VERSION "Version"

NS_ :

BS_:

BU_: Tester CCU ADC CCU_CCURT1 CCU_CCURT2 RLR RRR ZCUF ZCUL ZCUR ZCUT EMS IDM DCDC IPS NIDU DCUR OBC OPC LPC CPC EMCM GCU DCUF IPU BMS EOPR EVCC DCDC2 EDL SRS ECS EPS EPB RBM IBCS ICM IID IDC PHUDD AMP WHUD IMR INU IFC FAPA PAS PCS SCMR SCMRL SCMRR SCMRM MFS WSM DRM IDU FCP LBMSAD AVAS ATSS DLPFL FBLCM FLISD FLLCM FRLCM RLLCMA RLLCMB RRLCMA RRLCMB RLISD DLPML DLPMR TRM PSDL PSDR HVSPRL HVSPRR RFR SBM WCM ETC TBOX2 TBOX IDUR CBM PLGM TMC LPC2 SCMT RCP RRISD LBMS RLBMS CCURT1 CCURT2 RT1_C1 RT2_C3 RT1_C0 OTAWL RAS EBB RCICP WCMFR WCMRL SAS CD

BO_ 696 CCU_ZCUR_SBM_5: 64 CCU
 SG_ SBM_5_CRC : 7|16@0+ (1,0) [0|65535] ""  ADC,FAPA
 SG_ SBM_5_Counter : 23|8@0+ (1,0) [0|255] ""  ADC,FAPA
 SG_ KAE_EDK1UnlockBtnPressSt : 31|2@0+ (1,0) [0|3] ""  ADC,FAPA
 SG_ KAE_EDK1LockBtnPressSt : 29|2@0+ (1,0) [0|3] ""  ADC,FAPA
 SG_ KAE_EDK1RESBtnPressSt : 27|2@0+ (1,0) [0|3] ""  ADC,FAPA
 SG_ KAE_EDK1PSD_LBtnPressSt : 25|2@0+ (1,0) [0|3] ""  ADC,FAPA
 SG_ KAE_EDK1PSD_RBtnPressSt : 39|2@0+ (1,0) [0|3] ""  ADC,FAPA
 SG_ KAE_EDK1TrunkBtnPressSt : 37|2@0+ (1,0) [0|3] ""  ADC,FAPA
 SG_ KAE_EDK1PanicBtnPressSt : 35|2@0+ (1,0) [0|3] ""  ADC,FAPA
 SG_ KAE_EDK1User_definedBtnPressSt : 33|2@0+ (1,0) [0|3] ""  ADC,FAPA
 SG_ KAE_EDK2UnlockBtnPressSt : 47|2@0+ (1,0) [0|3] ""  ADC,FAPA
 SG_ KAE_EDK2LockBtnPressSt : 45|2@0+ (1,0) [0|3] ""  ADC,FAPA
 SG_ KAE_EDK2RESBtnPressSt : 43|2@0+ (1,0) [0|3] ""  ADC,FAPA
 SG_ KAE_EDK2PSD_LBtnPressSt : 41|2@0+ (1,0) [0|3] ""  ADC,FAPA
 SG_ KAE_EDK2PSD_RBtnPressSt : 55|2@0+ (1,0) [0|3] ""  ADC,FAPA
 SG_ KAE_EDK2TrunkBtnPressSt : 53|2@0+ (1,0) [0|3] ""  ADC,FAPA
 SG_ KAE_EDK2PanicBtnPressSt : 51|2@0+ (1,0) [0|3] ""  ADC,FAPA
 SG_ KAE_EDK2User_definedBtnPressSt : 49|2@0+ (1,0) [0|3] ""  ADC,FAPA
 SG_ KAE_EDK3UnlockBtnPressSt : 63|2@0+ (1,0) [0|3] ""  ADC,FAPA
 SG_ KAE_EDK3LockBtnPressSt : 61|2@0+ (1,0) [0|3] ""  ADC,FAPA
 SG_ KAE_EDK3RESBtnPressSt : 59|2@0+ (1,0) [0|3] ""  ADC,FAPA
 SG_ KAE_EDK3PSD_LBtnPressSt : 57|2@0+ (1,0) [0|3] ""  ADC,FAPA
 SG_ KAE_EDK3PSD_RBtnPressSt : 71|2@0+ (1,0) [0|3] ""  ADC,FAPA
 SG_ KAE_EDK3TrunkBtnPressSt : 69|2@0+ (1,0) [0|3] ""  ADC,FAPA
 SG_ KAE_EDK3PanicBtnPressSt : 67|2@0+ (1,0) [0|3] ""  ADC,FAPA
 SG_ KAE_EDK3User_definedBtnPressSt : 65|2@0+ (1,0) [0|3] ""  ADC,FAPA
 SG_ KAE_RPADirectionSel : 79|3@0+ (1,0) [0|7] ""  ADC,FAPA
 SG_ KAE_RPAmode : 76|2@0+ (1,0) [0|3] ""  ADC,FAPA
 SG_ KAE_RPADeviceSt : 74|3@0+ (1,0) [0|7] ""  ADC,FAPA
 SG_ KAE_PhoneBatt : 87|8@0+ (1,0) [0|100] ""  ADC,FAPA
 SG_ KAE_RPACheckReq : 95|1@0+ (1,0) [0|1] ""  ADC,FAPA
 SG_ KAE_RPAKeyPstSt : 94|2@0+ (1,0) [0|3] ""  ADC,FAPA
 SG_ KAE_RPADeviceFailReason : 92|4@0+ (1,0) [0|15] ""  ADC,FAPA
 SG_ KAE_RPABtnSt : 88|1@0+ (1,0) [0|1] ""  ADC,FAPA
 SG_ KAE_ForRPAFailReason : 103|4@0+ (1,0) [0|15] ""  ADC,FAPA
 SG_ KAE_RPABtnStVD : 99|1@0+ (1,0) [0|1] ""  ADC,FAPA
 SG_ KAE_RPACancelBtnSt : 98|1@0+ (1,0) [0|1] ""  ADC,FAPA
 SG_ KAE_RPACancelBtnStVD : 97|1@0+ (1,0) [0|1] ""  ADC,FAPA
 SG_ KAE_ComSDKUBouncesSt : 96|1@0+ (1,0) [0|1] ""  ADC,FAPA
 SG_ KAE_HAVPCancelParking : 111|1@0+ (1,0) [0|1] ""  ADC,FAPA
 SG_ KAE_HAVPDisclaimerAgree : 110|2@0+ (1,0) [0|3] ""  ADC,FAPA
 SG_ KAE_HAVPPathSelect : 108|4@0+ (1,0) [0|15] ""  ADC,FAPA
 SG_ KAE_RPAResponse : 119|8@0+ (1,0) [0|255] ""  ADC,FAPA
 SG_ KAE_HAVPUWBZone : 127|4@0+ (1,0) [0|15] ""  ADC,FAPA
 SG_ KAE_HAVPUWBXPosition : 123|12@0+ (1,0) [0|4095] ""  ADC,FAPA
 SG_ KAE_HAVPUWBYPosition : 143|12@0+ (1,0) [0|4095] ""  ADC,FAPA
 SG_ KAE_UnlockDoorReq : 147|1@0+ (1,0) [0|1] ""  ADC,FAPA
 SG_ KAE_UnlockDoorReqVD : 146|1@0+ (1,0) [0|1] ""  ADC,FAPA
 SG_ KAE_LockDoorReq : 145|1@0+ (1,0) [0|1] ""  ADC,FAPA
 SG_ KAE_LockDoorReqVD : 144|1@0+ (1,0) [0|1] ""  ADC,FAPA
 SG_ KAE_WindowsCloseReq : 159|1@0+ (1,0) [0|1] ""  ADC,FAPA
 SG_ KAE_WindowsCloseReqVD : 158|1@0+ (1,0) [0|1] ""  ADC,FAPA
 SG_ KAE_WindowsOpenReq : 157|1@0+ (1,0) [0|1] ""  ADC,FAPA
 SG_ KAE_WindowsOpenReqVD : 156|1@0+ (1,0) [0|1] ""  ADC,FAPA
 SG_ KAE_TrunkUnlockReq : 155|1@0+ (1,0) [0|1] ""  ADC,FAPA
 SG_ KAE_TrunkUnlockReqVD : 154|1@0+ (1,0) [0|1] ""  ADC,FAPA
 SG_ KAE_HoodUnlockReq : 153|1@0+ (1,0) [0|1] ""  ADC,FAPA
 SG_ KAE_HoodUnlockReqVD : 152|1@0+ (1,0) [0|1] ""  ADC,FAPA
 SG_ KAE_PLGMOpenReq : 167|1@0+ (1,0) [0|1] ""  ADC,FAPA
 SG_ KAE_PLGMOpenReqVD : 166|1@0+ (1,0) [0|1] ""  ADC,FAPA
 SG_ KAE_PLGMCloseReq : 165|1@0+ (1,0) [0|1] ""  ADC,FAPA
 SG_ KAE_PLGMCloseReqVD : 164|1@0+ (1,0) [0|1] ""  ADC,FAPA
 SG_ KAE_SunRoofOpenReq : 163|1@0+ (1,0) [0|1] ""  ADC,FAPA
 SG_ KAE_SunRoofOpenReqVD : 162|1@0+ (1,0) [0|1] ""  ADC,FAPA
 SG_ KAE_SunRoofCloseReq : 161|1@0+ (1,0) [0|1] ""  ADC,FAPA
 SG_ KAE_SunRoofCloseReqVD : 160|1@0+ (1,0) [0|1] ""  ADC,FAPA
 SG_ KAE_PAAReq : 287|4@0+ (1,0) [0|15] ""  ADC,FAPA
 SG_ KAE_PAAReqVd : 283|1@0+ (1,0) [0|1] ""  ADC,FAPA
 SG_ KAE_EDK1UnlockBtnSt : 282|1@0+ (1,0) [0|1] ""  ADC,FAPA
 SG_ KAE_EDK1LockBtnSt : 281|1@0+ (1,0) [0|1] ""  ADC,FAPA
 SG_ KAE_EDK1RESBtnSt : 280|1@0+ (1,0) [0|1] ""  ADC,FAPA
 SG_ KAE_EDK1PSD_LBtnSt : 295|1@0+ (1,0) [0|1] ""  ADC,FAPA
 SG_ KAE_EDK1PSD_RBtnSt : 294|1@0+ (1,0) [0|1] ""  ADC,FAPA
 SG_ KAE_EDK1TrunkBtnSt : 293|1@0+ (1,0) [0|1] ""  ADC,FAPA
 SG_ KAE_EDK1PanicBtnSt : 292|1@0+ (1,0) [0|1] ""  ADC,FAPA
 SG_ KAE_EDK1User_definedBtnSt : 291|1@0+ (1,0) [0|1] ""  ADC,FAPA
 SG_ KAE_EDK2UnlockBtnSt : 290|1@0+ (1,0) [0|1] ""  ADC,FAPA
 SG_ KAE_EDK2LockBtnSt : 289|1@0+ (1,0) [0|1] ""  ADC,FAPA
 SG_ KAE_EDK2RESBtnSt : 288|1@0+ (1,0) [0|1] ""  ADC,FAPA
 SG_ PKC_RemPwrOnOffReq : 314|3@0+ (1,0) [0|7] ""  ADC,FAPA
 SG_ KAE_EDK2PSD_LBtnSt : 303|1@0+ (1,0) [0|1] ""  ADC,FAPA
 SG_ KAE_EDK2PSD_RBtnSt : 302|1@0+ (1,0) [0|1] ""  ADC,FAPA
 SG_ KAE_EDK2TrunkBtnSt : 301|1@0+ (1,0) [0|1] ""  ADC,FAPA
 SG_ KAE_EDK2PanicBtnSt : 300|1@0+ (1,0) [0|1] ""  ADC,FAPA
 SG_ KAE_EDK2User_definedBtnSt : 299|1@0+ (1,0) [0|1] ""  ADC,FAPA
 SG_ KAE_EDK3UnlockBtnSt : 298|1@0+ (1,0) [0|1] ""  ADC,FAPA
 SG_ KAE_EDK3LockBtnSt : 297|1@0+ (1,0) [0|1] ""  ADC,FAPA
 SG_ KAE_EDK3RESBtnSt : 296|1@0+ (1,0) [0|1] ""  ADC,FAPA
 SG_ KAE_EDK3PSD_LBtnSt : 311|1@0+ (1,0) [0|1] ""  ADC,FAPA
 SG_ KAE_EDK3PSD_RBtnSt : 310|1@0+ (1,0) [0|1] ""  ADC,FAPA
 SG_ KAE_EDK3TrunkBtnSt : 309|1@0+ (1,0) [0|1] ""  ADC,FAPA
 SG_ KAE_EDK3PanicBtnSt : 308|1@0+ (1,0) [0|1] ""  ADC,FAPA
 SG_ KAE_EDK3User_definedBtnSt : 316|1@0+ (1,0) [0|1] ""  ADC,FAPA
 SG_ PKC_PhoneRPAOnlineOrNot : 455|8@0+ (1,0) [0|255] ""  ADC

BO_ 134 CCU_VIM_ADCCode: 16 CCU_CCURT1
 SG_ Theft_Auth_ADCCode : 7|128@0+ (1,0) [0|3.40282366920938E+38] ""  ADC,FAPA

BO_ 793 CCU_LBMS_1: 64 CCU
 SG_ LBMS_1_CRC : 7|16@0+ (1,0) [0|65535] ""  ADC
 SG_ LBMS_1_Counter : 23|8@0+ (1,0) [0|255] ""  ADC
 SG_ LBMS_SOFVD : 28|1@0+ (1,0) [0|1] ""  ADC
 SG_ LBMS_SOFEN : 30|2@0+ (1,0) [0|3] ""  ADC

BO_ 1024 CCU_TimeSync: 16 CCU
 SG_ SYNC_FC_Type : 7|8@0+ (1,0) [0|255] ""  ZCUF,ZCUL,ZCUR,ZCUT,ADC,FAPA
 SG_ SYNC_FC_CRC : 15|8@0+ (1,0) [0|255] ""  ZCUF,ZCUL,ZCUR,ZCUT,ADC,FAPA
 SG_ SYNC_FC_Sequencecnt : 19|4@0+ (1,0) [0|15] ""  ZCUF,ZCUL,ZCUR,ZCUT,ADC,FAPA
 SG_ SYNC_FC_TimeDomain : 23|4@0+ (1,0) [0|15] ""  ZCUF,ZCUL,ZCUR,ZCUT,ADC,FAPA
 SG_ SYNC_FC_OVS : 25|2@0+ (1,0) [0|3] ""  ZCUF,ZCUL,ZCUR,ZCUT,ADC,FAPA
 SG_ SYNC_FC_SGW : 26|1@0+ (1,0) [0|1] ""  ZCUF,ZCUL,ZCUR,ZCUT,ADC,FAPA
 SG_ SYNC_FC_Reserved : 31|5@0+ (1,0) [0|31] ""  ZCUF,ZCUL,ZCUR,ZCUT,ADC,FAPA
 SG_ SYNC_FC_SyncTime : 39|32@0+ (1,0) [0|4294967295] ""  ZCUF,ZCUL,ZCUR,ZCUT,ADC,FAPA

BO_ 476 CCU_FCP_1: 16 CCU
 SG_ FCP_OmniViewBtnSt : 96|1@0+ (1,0) [0|1] ""  IDC,ADC
 SG_ FCP_OmniViewBtnStVD : 97|1@0+ (1,0) [0|1] ""  IDC,ADC

BO_ 1657 ADC_MCU_Diag_Request: 64 Tester
 SG_ ADC_MCU_Diag_Request : 7|64@0+ (1,0) [0|0] ""  ADC

BO_ 1806 ADC_Phys_Diag_Rx: 64 Tester
 SG_ ADC_Diag_Request : 7|512@0+ (1,0) [0|0] ""  ADC

BO_ 1854 FR_Phys_Diag_Rx: 64 Tester
 SG_ FR_Diag_Request : 7|512@0+ (1,0) [0|0] ""  ADC,IFC,FAPA

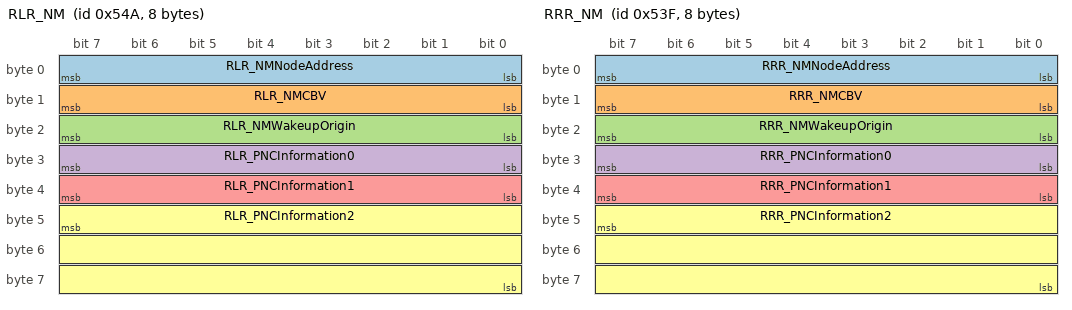
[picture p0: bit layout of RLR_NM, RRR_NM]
BO_ 1354 RLR_NM: 8 RLR
 SG_ RLR_NMNodeAddress : 7|8@0+ (1,0) [0|255] ""  CCU,ADC,RRR
 SG_ RLR_NMCBV : 15|8@0+ (1,0) [0|0] ""  CCU,ADC,RRR
 SG_ RLR_NMWakeupOrigin : 23|8@0+ (1,0) [0|255] ""  CCU,ADC,RRR
 SG_ RLR_PNCInformation0 : 31|8@0+ (1,0) [0|255] ""  CCU,ADC,RRR
 SG_ RLR_PNCInformation1 : 39|8@0+ (1,0) [0|255] ""  CCU,ADC,RRR
 SG_ RLR_PNCInformation2 : 47|24@0+ (1,0) [0|0] ""  CCU,ADC,RRR

BO_ 987 RLR_1: 32 RLR
 SG_ RLR_1_CRC : 7|16@0+ (1,0) [0|65535] ""  ADC,IFC,FAPA
 SG_ RLR_1_Counter : 23|8@0+ (1,0) [0|255] ""  ADC,IFC,FAPA
 SG_ RLR_MRRSt : 31|3@0+ (1,0) [0|7] ""  ADC,IFC,FAPA
 SG_ RLR_ExMirLedWarnL : 28|2@0+ (1,0) [0|3] ""  ADC,IFC,FAPA
 SG_ RLR_LCASt : 26|2@0+ (1,0) [0|3] ""  ADC,IFC,FAPA
 SG_ RLR_LCAWarnLeft : 24|2@0+ (1,0) [0|3] ""  ADC,IFC,FAPA
 SG_ RLR_ClusterLamp : 38|3@0+ (1,0) [0|7] ""  ADC,IFC,FAPA
 SG_ RLR_DOWWarnL : 35|2@0+ (1,0) [0|3] ""  ADC,IFC,FAPA
 SG_ RLR_DOWSt : 33|2@0+ (1,0) [0|3] ""  ADC,IFC,FAPA
 SG_ RLR_AudioWarnFL : 41|2@0+ (1,0) [0|3] ""  ADC,IFC,FAPA
 SG_ RLR_AudioWarnRL : 43|2@0+ (1,0) [0|3] ""  ADC,IFC,FAPA
 SG_ RLR_IALWarnFL : 45|2@0+ (1,0) [0|3] ""  ADC,IFC,FAPA
 SG_ RLR_IALWarnRL : 47|2@0+ (1,0) [0|3] ""  ADC,IFC,FAPA
 SG_ RLR_RCTAWarnLeft : 49|2@0+ (1,0) [0|3] ""  ADC,IFC,FAPA
 SG_ RLR_RCWSt : 51|2@0+ (1,0) [0|3] ""  ADC,IFC,FAPA
 SG_ RLR_RCWWarn : 53|2@0+ (1,0) [0|3] ""  ADC,IFC,FAPA,RRR
 SG_ RLR_TargetLVD : 55|2@0+ (1,0) [0|3] ""  ADC,IFC,FAPA
 SG_ RLR_TargetRelSpdL : 63|10@0+ (0.06225,-10) [-10|50] "m/s"  ADC,IFC,FAPA
 SG_ RLR_TargetDstL : 69|11@0+ (0.06225,-90) [-90|10] "m"  ADC,IFC,FAPA
 SG_ RLR_TargetLatDistL : 74|7@0+ (0.1,0) [0|12.7] "m"  ADC,IFC,FAPA
 SG_ RLR_RCTASt : 83|2@0+ (1,0) [0|3] ""  ADC,IFC,FAPA
 SG_ RLR_RCTAAssistType : 81|2@0+ (1,0) [0|3] ""  ADC,IFC,FAPA,RRR

BO_ 1343 RRR_NM: 8 RRR
 SG_ RRR_NMNodeAddress : 7|8@0+ (1,0) [0|255] ""  CCU,ADC,RLR
 SG_ RRR_NMCBV : 15|8@0+ (1,0) [0|0] ""  CCU,ADC,RLR
 SG_ RRR_NMWakeupOrigin : 23|8@0+ (1,0) [0|255] ""  CCU,ADC,RLR
 SG_ RRR_PNCInformation0 : 31|8@0+ (1,0) [0|255] ""  CCU,ADC,RLR
 SG_ RRR_PNCInformation1 : 39|8@0+ (1,0) [0|255] ""  CCU,ADC,RLR
 SG_ RRR_PNCInformation2 : 47|24@0+ (1,0) [0|0] ""  CCU,ADC,RLR

BO_ 932 RRR_1: 32 RRR
 SG_ RRR_1_CRC : 7|16@0+ (1,0) [0|65535] ""  ADC,IFC,FAPA
 SG_ RRR_1_Counter : 23|8@0+ (1,0) [0|255] ""  ADC,IFC,FAPA
 SG_ RRR_MRRSt : 31|3@0+ (1,0) [0|7] ""  ADC,IFC,FAPA
 SG_ RRR_ExMirLedWarnR : 28|2@0+ (1,0) [0|3] ""  ADC,IFC,FAPA
 SG_ RRR_LCASt : 26|2@0+ (1,0) [0|3] ""  ADC,IFC,FAPA
 SG_ RRR_LCAWarnRight : 24|2@0+ (1,0) [0|3] ""  ADC,IFC,FAPA
 SG_ RRR_ClusterLamp : 38|3@0+ (1,0) [0|7] ""  ADC,IFC,FAPA
 SG_ RRR_DOWWarnR : 35|2@0+ (1,0) [0|3] ""  ADC,IFC,FAPA
 SG_ RRR_DOWSt : 33|2@0+ (1,0) [0|3] ""  ADC,IFC,FAPA
 SG_ RRR_AudioWarnFR : 41|2@0+ (1,0) [0|3] ""  ADC,IFC,FAPA
 SG_ RRR_AudioWarnRR : 43|2@0+ (1,0) [0|3] ""  ADC,IFC,FAPA
 SG_ RRR_IALWarnFR : 45|2@0+ (1,0) [0|3] ""  ADC,IFC,FAPA
 SG_ RRR_IALWarnRR : 47|2@0+ (1,0) [0|3] ""  ADC,IFC,FAPA
 SG_ RRR_RCTASt : 49|2@0+ (1,0) [0|3] ""  ADC,IFC,FAPA
 SG_ RRR_RCTAWarnRight : 51|2@0+ (1,0) [0|3] ""  ADC,IFC,FAPA
 SG_ RRR_RCWSt : 53|2@0+ (1,0) [0|3] ""  ADC,IFC,FAPA
 SG_ RRR_RCWWarn : 55|2@0+ (1,0) [0|3] ""  ADC,IFC,FAPA
 SG_ RRR_RCTBTargetDecel : 63|8@0+ (0.05,-10) [-10|2.75] "m/s2"  ADC,IFC,FAPA
 SG_ RRR_RCTBBrkReq : 64|1@0+ (1,0) [0|1] ""  ADC,IFC,FAPA
 SG_ RRR_TargetLatDistR : 71|7@0+ (0.1,-12.7) [-12.7|0] ""  ADC,IFC,FAPA
 SG_ RRR_TargetRelSpdR : 79|10@0+ (0.06225,-10) [-10|50] "m/s"  ADC,IFC,FAPA
 SG_ RRR_RCTBBrkgVD : 83|1@0+ (1,0) [0|1] ""  ADC,IFC,FAPA
 SG_ RRR_TargetRVD : 85|2@0+ (1,0) [0|3] ""  ADC,IFC,FAPA
 SG_ RRR_TargetDstR : 82|11@0+ (0.06225,-90) [-90|10] "m"  ADC,IFC,FAPA
 SG_ RRR_RCTAAssistType : 103|2@0+ (1,0) [0|3] ""  ADC,IFC,FAPA

BO_ 620 CCU_PADS_2: 32 CCU_CCURT1
 SG_ CCU_PADS_2_CRC : 7|16@0+ (1,0) [0|65535] ""  ADC,IFC,FAPA
 SG_ CCU_PADS_2_Counter : 23|8@0+ (1,0) [0|255] ""  ADC,IFC,FAPA
 SG_ UINM_PADS_ResponseErr : 28|1@0+ (1,0) [0|1] ""  ADC,IFC,FAPA
 SG_ UINM_PADS_CustomSWSt : 41|1@0+ (1,0) [0|1] ""  ICM,IDC,ADC,IFC,FAPA
 SG_ UINM_PADS_CustomSWStVD : 42|1@0+ (1,0) [0|1] ""  ICM,IDC,ADC,IFC,FAPA
 SG_ UINM_PADS_CustomSWstuck : 43|1@0+ (1,0) [0|1] ""  ICM,IDC,ADC,IFC,FAPA
 SG_ UINM_PADS_IDC_PlaySWSt : 58|1@0+ (1,0) [0|1] ""  ICM,IDC,ADC,IFC,FAPA
 SG_ UINM_PADS_IDC_PlaySWStVD : 59|1@0+ (1,0) [0|1] ""  ICM,IDC,ADC,IFC,FAPA
 SG_ UINM_PADS_CruSetSpeedRollerRotatedDir : 62|2@0+ (1,0) [0|3] ""  ICM,IDC,ADC,IFC,FAPA
 SG_ UINM_PADS_FolDistIncSWSt : 63|1@0+ (1,0) [0|1] ""  ICM,IDC,ADC,IFC,FAPA
 SG_ UINM_PADS_CruSetSpeedRollerSt : 69|6@0+ (1,0) [0|63] ""  ICM,IDC,ADC,IFC,FAPA
 SG_ UINM_PADS_FolDistIncSWStVD : 70|1@0+ (1,0) [0|1] ""  ICM,IDC,ADC,IFC,FAPA
 SG_ UINM_PADS_FolDistIncSWStuckSt : 71|1@0+ (1,0) [0|1] ""  ICM,IDC,ADC,IFC,FAPA
 SG_ UINM_PADS_FolDistDecSWStVD : 73|1@0+ (1,0) [0|1] ""  ICM,IDC,ADC,IFC,FAPA
 SG_ UINM_PADS_FolDistDecSWStuckSt : 74|1@0+ (1,0) [0|1] ""  ICM,IDC,ADC,IFC,FAPA
 SG_ UINM_PADS_OKSWSt : 75|1@0+ (1,0) [0|1] ""  ICM,IDC,ADC,IFC,FAPA
 SG_ UINM_PADS_OKSWStVD : 76|1@0+ (1,0) [0|1] ""  ICM,IDC,ADC,IFC,FAPA
 SG_ UINM_PADS_OKSWStuckSt : 77|1@0+ (1,0) [0|1] ""  ICM,IDC,ADC,IFC,FAPA
 SG_ UINM_PADS_CruSetSpeedRollerVD : 79|1@0+ (1,0) [0|1] ""  IDC,ADC,IFC,FAPA
 SG_ UINM_PADS_FolDistDecSWSt : 72|1@0+ (1,0) [0|1] ""  ICM,IDC,ADC,IFC,FAPA
 SG_ IL_PADS_LightbarErrSt : 140|1@0+ (1,0) [0|1] "/"  ADC,FAPA
 SG_ UINM_PADS_CruSWSt : 107|1@0+ (1,0) [0|1] ""  ADC,IFC,FAPA
 SG_ UINM_PADS_CruSWStVD : 108|1@0+ (1,0) [0|1] ""  ADC,IFC,FAPA
 SG_ UINM_PADS_CruSWStuckSt : 109|1@0+ (1,0) [0|1] ""  ADC,IFC,FAPA
 SG_ UINM_PADS_CruSpeedDecSWSt : 110|1@0+ (1,0) [0|1] ""  ADC,IFC,FAPA
 SG_ UINM_PADS_CruSpeedDecSWStVD : 111|1@0+ (1,0) [0|1] ""  ADC,IFC,FAPA
 SG_ UINM_PADS_CruSpeedDecSWStuckSt : 112|1@0+ (1,0) [0|1] ""  ADC,IFC,FAPA
 SG_ UINM_PADS_CruResumeSpeedIncSWSt : 113|1@0+ (1,0) [0|1] ""  ADC,IFC,FAPA
 SG_ UINM_PADS_CruResumeSpeedIncSWStVD : 114|1@0+ (1,0) [0|1] ""  ADC,IFC,FAPA
 SG_ UINM_PADS_CruResumeSpeedIncSWStuckSt : 115|1@0+ (1,0) [0|1] ""  ADC,IFC,FAPA
 SG_ UINM_PADS_CruTJAICASWSt : 119|1@0+ (1,0) [0|1] ""  ADC,IFC,FAPA
 SG_ UINM_PADS_CruTJAICASWStVD : 120|1@0+ (1,0) [0|1] ""  ADC,IFC,FAPA
 SG_ UINM_PADS_CruTJAICASWStuckSt : 121|1@0+ (1,0) [0|1] ""  ADC,IFC,FAPA
 SG_ UINM_PADS_Custom2SWSt : 125|1@0+ (1,0) [0|1] ""  IDC,ADC,IFC,FAPA
 SG_ UINM_PADS_Custom2SWStVD : 126|1@0+ (1,0) [0|1] ""  IDC,ADC,IFC,FAPA
 SG_ UINM_PADS_Custom2SWStuckSt : 127|1@0+ (1,0) [0|1] ""  IDC,ADC,IFC,FAPA
 SG_ UINM_PADS_ACCSWSt : 129|2@0+ (1,0) [0|3] ""  ADC,IFC,FAPA
 SG_ UINM_PADS_VoltageFaultSt : 131|2@0+ (1,0) [0|3] ""  ADC,IFC,FAPA
 SG_ UINM_PADS_L3SWSt : 133|2@0+ (1,0) [0|3] ""  ADC
 SG_ UINM_PADS_L3SWStVD : 134|1@0+ (1,0) [0|1] ""  ADC
 SG_ UINM_PADS_L3SWStuckSt : 135|1@0+ (1,0) [0|1] ""  ADC
 SG_ IL_PADS_LightbarSt : 139|4@0+ (1,0) [0|15] "/"  ADC,FAPA

CM_ SG_ 696 SBM_5_CRC "E2E Profile 5 CRC";
CM_ SG_ 696 SBM_5_Counter "E2E Profile 5 Counter";
CM_ SG_ 696 KAE_EDK1UnlockBtnPressSt "EDK Unlock Button Pressed Status";
CM_ SG_ 696 KAE_EDK1LockBtnPressSt "EDK Lock Button Pressed Status";
CM_ SG_ 696 KAE_EDK1RESBtnPressSt "EDK RES Button Status";
CM_ SG_ 696 KAE_EDK1PSD_LBtnPressSt "EDK PSD_L Button Status";
CM_ SG_ 696 KAE_EDK1PSD_RBtnPressSt "EDK PSD_R Button Status";
CM_ SG_ 696 KAE_EDK1TrunkBtnPressSt "EDK Trunk Button Status";
CM_ SG_ 696 KAE_EDK1PanicBtnPressSt "EDK Panic Button Status";
CM_ SG_ 696 KAE_EDK1User_definedBtnPressSt "EDK User_defined Button Status";
CM_ SG_ 696 KAE_EDK2UnlockBtnPressSt "EDK Unlock Button Pressed Status";
CM_ SG_ 696 KAE_EDK2LockBtnPressSt "EDK Lock Button Pressed Status";
CM_ SG_ 696 KAE_EDK2RESBtnPressSt "EDK RES Button Status";
CM_ SG_ 696 KAE_EDK2PSD_LBtnPressSt "EDK PSD_L Button Status";
CM_ SG_ 696 KAE_EDK2PSD_RBtnPressSt "EDK PSD_R Button Status";
CM_ SG_ 696 KAE_EDK2TrunkBtnPressSt "EDK Trunk Button Status";
CM_ SG_ 696 KAE_EDK2PanicBtnPressSt "EDK Panic Button Status";
CM_ SG_ 696 KAE_EDK2User_definedBtnPressSt "EDK User_defined Button Status";
CM_ SG_ 696 KAE_EDK3UnlockBtnPressSt "EDK Unlock Button Pressed Status";
CM_ SG_ 696 KAE_EDK3LockBtnPressSt "EDK Lock Button Pressed Status";
CM_ SG_ 696 KAE_EDK3RESBtnPressSt "EDK RES Button Status";
CM_ SG_ 696 KAE_EDK3PSD_LBtnPressSt "EDK PSD_L Button Status";
CM_ SG_ 696 KAE_EDK3PSD_RBtnPressSt "EDK PSD_R Button Status";
CM_ SG_ 696 KAE_EDK3TrunkBtnPressSt "EDK Trunk Button Status";
CM_ SG_ 696 KAE_EDK3PanicBtnPressSt "EDK Panic Button Status";
CM_ SG_ 696 KAE_EDK3User_definedBtnPressSt "EDK User_defined Button Status";
CM_ SG_ 696 KAE_RPADirectionSel "RPA Direction Selection";
CM_ SG_ 696 KAE_RPAmode "SBM RPA mode";
CM_ SG_ 696 KAE_RPADeviceSt "RPA Device Status";
CM_ SG_ 696 KAE_PhoneBatt "SBM Phone batt";
CM_ SG_ 696 KAE_RPACheckReq "SBM RPA Checking Req";
CM_ SG_ 696 KAE_RPAKeyPstSt "RPA Key Position Status";
CM_ SG_ 696 KAE_RPADeviceFailReason "RPA Device Failure Reason";
CM_ SG_ 696 KAE_RPABtnSt "RPA Button Status";
CM_ SG_ 696 KAE_ForRPAFailReason "RPA and SBM failure reason";
CM_ SG_ 696 KAE_RPABtnStVD "RPA Button Status valid value";
CM_ SG_ 696 KAE_RPACancelBtnSt "RPA Cancal Button Status";
CM_ SG_ 696 KAE_RPACancelBtnStVD "RPA Button Statusvalid valid value";
CM_ SG_ 696 KAE_ComSDKUBouncesSt "Communication status between SBM and SDK,This signal bounces every time the SDK updates the data";
CM_ SG_ 696 KAE_HAVPCancelParking "HAVP User cancellation SBM";
CM_ SG_ 696 KAE_HAVPDisclaimerAgree "App HAVP Disclaimer confirm";
CM_ SG_ 696 KAE_HAVPPathSelect "HAVP User path selection SBM";
CM_ SG_ 696 KAE_RPAResponse "SBM Response RPA Challenge  Singal";
CM_ SG_ 696 KAE_HAVPUWBZone "SBM UWB HAVP Zone";
CM_ SG_ 696 KAE_HAVPUWBXPosition "SBM UWB HAVP X Position";
CM_ SG_ 696 KAE_HAVPUWBYPosition "SBM UWB HAVP Y Position";
CM_ SG_ 696 KAE_UnlockDoorReq "Virtual Key APP Unlock door request";
CM_ SG_ 696 KAE_UnlockDoorReqVD "KAE_UnlockDoorReq valid value";
CM_ SG_ 696 KAE_LockDoorReq "Virtual Key APP Lock door request";
CM_ SG_ 696 KAE_LockDoorReqVD "KAE_LockDoorReq valid value";
CM_ SG_ 696 KAE_WindowsCloseReq "Virtual Key APP close the windows request";
CM_ SG_ 696 KAE_WindowsCloseReqVD "KAE_WindowsCloseReq valid value";
CM_ SG_ 696 KAE_WindowsOpenReq "Virtual Key APP open the windows request";
CM_ SG_ 696 KAE_WindowsOpenReqVD "KAE_WindowsOpenReq valid value";
CM_ SG_ 696 KAE_TrunkUnlockReq "Virtual Key APP request unlock the trunck";
CM_ SG_ 696 KAE_TrunkUnlockReqVD "KAE_TrunkUnlockReq valid value";
CM_ SG_ 696 KAE_HoodUnlockReq "Virtual Key APP request unlock the hood";
CM_ SG_ 696 KAE_HoodUnlockReqVD "KAE_HoodeUnlockReq valid value";
CM_ SG_ 696 KAE_PLGMOpenReq "Virtual Key APP PLGM(Power Liftgate Module) open request";
CM_ SG_ 696 KAE_PLGMOpenReqVD "KAE_PLGMOpenReq valid value";
CM_ SG_ 696 KAE_PLGMCloseReq "Virtual Key APP PLGM(Power Liftgate Module) close request";
CM_ SG_ 696 KAE_PLGMCloseReqVD "KAE_PLGMCloseReq valid value";
CM_ SG_ 696 KAE_SunRoofOpenReq "Virtual Key APP sun roof open request";
CM_ SG_ 696 KAE_SunRoofOpenReqVD "KAE_SunRoofOpenReq valid value";
CM_ SG_ 696 KAE_SunRoofCloseReq "Virtual Key APP sun roof close request";
CM_ SG_ 696 KAE_SunRoofCloseReqVD "KAE_SunRoofCloseReq valid value";
CM_ SG_ 696 KAE_PAAReq "KAE PAA request";
CM_ SG_ 696 KAE_PAAReqVd "KAE_PAA Req valid value";
CM_ SG_ 696 KAE_EDK1UnlockBtnSt "EDK1 Unlock Button current Status";
CM_ SG_ 696 KAE_EDK1LockBtnSt "EDK1 Lock Button current Status";
CM_ SG_ 696 KAE_EDK1RESBtnSt "EDK1 RES Button  current Status";
CM_ SG_ 696 KAE_EDK1PSD_LBtnSt "EDK1 PSD_L Button current Status";
CM_ SG_ 696 KAE_EDK1PSD_RBtnSt "EDK1 PSD_R Button current Status";
CM_ SG_ 696 KAE_EDK1TrunkBtnSt "EDK1 Trunk Button current Status";
CM_ SG_ 696 KAE_EDK1PanicBtnSt "EDK1 Panic Button current Status";
CM_ SG_ 696 KAE_EDK1User_definedBtnSt "EDK1 User_defined Button current Status";
CM_ SG_ 696 KAE_EDK2UnlockBtnSt "EDK2 Unlock Button current Status";
CM_ SG_ 696 KAE_EDK2LockBtnSt "EDK2 Lock Button current Status";
CM_ SG_ 696 KAE_EDK2RESBtnSt "EDK2 RES Button  current Status";
CM_ SG_ 696 PKC_RemPwrOnOffReq "RPA power on and power off request";
CM_ SG_ 696 KAE_EDK2PSD_LBtnSt "EDK2 PSD_L Button current Status";
CM_ SG_ 696 KAE_EDK2PSD_RBtnSt "EDK2 PSD_R Button current Status";
CM_ SG_ 696 KAE_EDK2TrunkBtnSt "EDK2 Trunk Button current Status";
CM_ SG_ 696 KAE_EDK2PanicBtnSt "EDK2 Panic Button current Status";
CM_ SG_ 696 KAE_EDK2User_definedBtnSt "EDK2 User_defined Button current Status";
CM_ SG_ 696 KAE_EDK3UnlockBtnSt "EDK3 Unlock Button current Status";
CM_ SG_ 696 KAE_EDK3LockBtnSt "EDK3 Lock Button current Status";
CM_ SG_ 696 KAE_EDK3RESBtnSt "EDK3 RES Button  current Status";
CM_ SG_ 696 KAE_EDK3PSD_LBtnSt "EDK3 PSD_L Button current Status";
CM_ SG_ 696 KAE_EDK3PSD_RBtnSt "EDK3 PSD_R Button current Status";
CM_ SG_ 696 KAE_EDK3TrunkBtnSt "EDK3 Trunk Button current Status";
CM_ SG_ 696 KAE_EDK3PanicBtnSt "EDK3 Panic Button current Status";
CM_ SG_ 696 KAE_EDK3User_definedBtnSt "EDK3 User_defined Button current Status";
CM_ SG_ 696 PKC_PhoneRPAOnlineOrNot "Phone RPA Online Or Not";
CM_ SG_ 134 Theft_Auth_ADCCode "Remote Control Random Code to ADC";
CM_ SG_ 793 LBMS_1_CRC "E2E Profile 5 CRC";
CM_ SG_ 793 LBMS_1_Counter "E2E Profile 5 Counter";
CM_ SG_ 793 LBMS_SOFVD "LBMS Validity of SOF";
CM_ SG_ 793 LBMS_SOFEN "LBMS  State of Function Enable";
CM_ SG_ 1024 SYNC_FC_Type "Type=0x20:TsyncType=0x28:Tsync FUP";
CM_ SG_ 1024 SYNC_FC_CRC "CRC";
CM_ SG_ 1024 SYNC_FC_Sequencecnt "Sequence counter";
CM_ SG_ 1024 SYNC_FC_TimeDomain "Time Domain";
CM_ SG_ 1024 SYNC_FC_OVS "In FUP PDUOVS=Overflow of seconds";
CM_ SG_ 1024 SYNC_FC_SGW "In FUP PDUSyncToGTM=0SyncToSubDomain=1";
CM_ SG_ 1024 SYNC_FC_Reserved "In FUP PDUReserved default=0";
CM_ SG_ 1024 SYNC_FC_SyncTime "Tsync:SyncTimeSec=32bit LSB of the 48 bits seconds part timeTsync FUP:Sync TimeNSec=32 bit value in nanosconds";
CM_ SG_ 476 FCP_OmniViewBtnSt "OmniView Button Status";
CM_ SG_ 476 FCP_OmniViewBtnStVD "indicates signal FCP_OmniViewBtnSt validity";
CM_ SG_ 1657 ADC_MCU_Diag_Request "Diagnostic function of ADC_MCU request";
CM_ SG_ 1806 ADC_Diag_Request "Diagnostic physical request";
CM_ SG_ 1854 FR_Diag_Request "Diagnostic physical request";
CM_ SG_ 1354 RLR_NMNodeAddress "RLR node address";
CM_ SG_ 1354 RLR_NMCBV "RLR Network management control bit vector";
CM_ SG_ 1354 RLR_NMWakeupOrigin "Origin of the wake up";
CM_ SG_ 1354 RLR_PNCInformation0 "PNC Information";
CM_ SG_ 1354 RLR_PNCInformation1 "PNC Information";
CM_ SG_ 1354 RLR_PNCInformation2 "PNC Information";
CM_ SG_ 987 RLR_1_CRC "E2E Profile 5 CRC";
CM_ SG_ 987 RLR_1_Counter "E2E Profile 5 Counter";
CM_ SG_ 987 RLR_MRRSt "MRR systems ON OFF andError Status";
CM_ SG_ 987 RLR_ExMirLedWarnL "Exterior mirror LED warning left";
CM_ SG_ 987 RLR_LCASt "BSD-LCA Function status";
CM_ SG_ 987 RLR_LCAWarnLeft " the vehicle Left warning level in the LCA feature";
CM_ SG_ 987 RLR_ClusterLamp "Cluster lamp color status";
CM_ SG_ 987 RLR_DOWWarnL "DOW warning left";
CM_ SG_ 987 RLR_DOWSt "DOW function state left";
CM_ SG_ 987 RLR_AudioWarnFL "Front left door speaker warning";
CM_ SG_ 987 RLR_AudioWarnRL "Rear left door speaker warning";
CM_ SG_ 987 RLR_IALWarnFL "Front left door light warning";
CM_ SG_ 987 RLR_IALWarnRL "Rear left door light warning";
CM_ SG_ 987 RLR_RCTAWarnLeft "the vehicle left warning in the RCTAfeature";
CM_ SG_ 987 RLR_RCWSt "RCW(rear collision warning ) feature status";
CM_ SG_ 987 RLR_RCWWarn "the vehicle warning level in the RCWfeature";
CM_ SG_ 987 RLR_TargetLVD "ELK left target valid state";
CM_ SG_ 987 RLR_TargetRelSpdL "ELK left target relative speed";
CM_ SG_ 987 RLR_TargetDstL "ELK left target relative distance";
CM_ SG_ 987 RLR_TargetLatDistL "ELK left target lateral relative distance ";
CM_ SG_ 987 RLR_RCTASt "RCTA Function status left";
CM_ SG_ 987 RLR_RCTAAssistType "RCTA assist type request";
CM_ SG_ 1343 RRR_NMNodeAddress "RRR node address";
CM_ SG_ 1343 RRR_NMCBV "RRR Network management control bit vector";
CM_ SG_ 1343 RRR_NMWakeupOrigin "Origin of the wake up";
CM_ SG_ 1343 RRR_PNCInformation0 "PNC Information";
CM_ SG_ 1343 RRR_PNCInformation1 "PNC Information";
CM_ SG_ 1343 RRR_PNCInformation2 "PNC Information";
CM_ SG_ 932 RRR_1_CRC "E2E Profile 5 CRC";
CM_ SG_ 932 RRR_1_Counter "E2E Profile 5 Counter";
CM_ SG_ 932 RRR_MRRSt "MRR systems ON OFF andError Status";
CM_ SG_ 932 RRR_ExMirLedWarnR "Exterior mirror LED warning right";
CM_ SG_ 932 RRR_LCASt "BSD-LCA Function status";
CM_ SG_ 932 RRR_LCAWarnRight " the vehicle right warning level in the LCA feature";
CM_ SG_ 932 RRR_ClusterLamp "Cluster lamp color status";
CM_ SG_ 932 RRR_DOWWarnR "DOW warning right";
CM_ SG_ 932 RRR_DOWSt "DOW function state  right";
CM_ SG_ 932 RRR_AudioWarnFR "Front right door speaker warning";
CM_ SG_ 932 RRR_AudioWarnRR "Rear right door speaker warning";
CM_ SG_ 932 RRR_IALWarnFR "Front right door light warning";
CM_ SG_ 932 RRR_IALWarnRR "Rear right door light warning";
CM_ SG_ 932 RRR_RCTASt "RCTA Function status";
CM_ SG_ 932 RRR_RCTAWarnRight "the vehicle right warning in the RCTAfeature";
CM_ SG_ 932 RRR_RCWSt "RCW(rear collision warning ) feature status";
CM_ SG_ 932 RRR_RCWWarn "the vehicle warning level in the RCWfeature";
CM_ SG_ 932 RRR_RCTBTargetDecel "target deceleration value from RCTB";
CM_ SG_ 932 RRR_RCTBBrkReq "RCTB brake request";
CM_ SG_ 932 RRR_TargetLatDistR "ELK right target lateral relative distance";
CM_ SG_ 932 RRR_TargetRelSpdR "ELK right target relative speed";
CM_ SG_ 932 RRR_RCTBBrkgVD "RCTB brake request valid flag";
CM_ SG_ 932 RRR_TargetRVD "ELK right target valid state";
CM_ SG_ 932 RRR_TargetDstR "ELK right target relative distance";
CM_ SG_ 932 RRR_RCTAAssistType "RCTA assist type request";
CM_ SG_ 620 CCU_PADS_2_CRC "E2E Profile 5 CRC";
CM_ SG_ 620 CCU_PADS_2_Counter "E2E Profile 5 Counter";
CM_ SG_ 620 UINM_PADS_ResponseErr "LIN response error";
CM_ SG_ 620 UINM_PADS_CustomSWSt "PADS Custom  swtich state";
CM_ SG_ 620 UINM_PADS_CustomSWStVD "PADS_CustomSWSt validity";
CM_ SG_ 620 UINM_PADS_CustomSWstuck "PADS Custom  swtich stuck state";
CM_ SG_ 620 UINM_PADS_IDC_PlaySWSt "Indicates PADS Play swtich state";
CM_ SG_ 620 UINM_PADS_IDC_PlaySWStVD "Indicates PADS_IDC_PlaySWSt validity";
CM_ SG_ 620 UINM_PADS_CruSetSpeedRollerRotatedDir "indicate PADS curise  roller rotating direction";
CM_ SG_ 620 UINM_PADS_FolDistIncSWSt "PADS Following distance level increase  swtich state";
CM_ SG_ 620 UINM_PADS_CruSetSpeedRollerSt "indicate PADS curise  roller rotating steps";
CM_ SG_ 620 UINM_PADS_FolDistIncSWStVD "Indicates PADS_FolDistIncSWSt validity";
CM_ SG_ 620 UINM_PADS_FolDistIncSWStuckSt "Indicates PADS's   distance level increase swtich stuck state";
CM_ SG_ 620 UINM_PADS_FolDistDecSWStVD "Indicates PADS_FolDistDecSWSt validity";
CM_ SG_ 620 UINM_PADS_FolDistDecSWStuckSt "Indicates PADS's   distance level decrease swtich stuck state";
CM_ SG_ 620 UINM_PADS_OKSWSt "PADS OK swtich state";
CM_ SG_ 620 UINM_PADS_OKSWStVD "Indicates PADS_OKSWSt validity";
CM_ SG_ 620 UINM_PADS_OKSWStuckSt "PADS OK swtich Stuck state";
CM_ SG_ 620 UINM_PADS_CruSetSpeedRollerVD "Indicates PADS's CruSetSpeed singal  validity";
CM_ SG_ 620 UINM_PADS_FolDistDecSWSt "PADS Following distance level decrease  swtich state";
CM_ SG_ 620 IL_PADS_LightbarErrSt "Steering wheel ambient light bar error feedback ";
CM_ SG_ 620 UINM_PADS_CruSWSt "Indicates PADS's Cruise On or Off swtich state";
CM_ SG_ 620 UINM_PADS_CruSWStVD "Indicates PADS_CruSWSt validity";
CM_ SG_ 620 UINM_PADS_CruSWStuckSt "Indicates PADS's Cruise On or Off swtich  stuck state";
CM_ SG_ 620 UINM_PADS_CruSpeedDecSWSt "Indicates PADS's Cruise Speed decrease swtich state";
CM_ SG_ 620 UINM_PADS_CruSpeedDecSWStVD "Indicates PADS_CruSpeedDecSWSt validity";
CM_ SG_ 620 UINM_PADS_CruSpeedDecSWStuckSt "Indicates PADS's Cruise Speed decrease swtich stcuk state";
CM_ SG_ 620 UINM_PADS_CruResumeSpeedIncSWSt "Indicates PADS's Cruise Resume&Speed increase or resume swtich state";
CM_ SG_ 620 UINM_PADS_CruResumeSpeedIncSWStVD "Indicates PADS_CruResumeSpeedIncSWSt validity";
CM_ SG_ 620 UINM_PADS_CruResumeSpeedIncSWStuckSt "Indicates PADS's Cruise Resume&Speed increase or resume swtich state";
CM_ SG_ 620 UINM_PADS_CruTJAICASWSt "Indicates PADS's Trafiic Jam Assist or Integrated Cruise Assit  swtich state";
CM_ SG_ 620 UINM_PADS_CruTJAICASWStVD "Indicates PADS_CruTJAICASWSt validity";
CM_ SG_ 620 UINM_PADS_CruTJAICASWStuckSt "Indicates PADS's Trafiic Jam Assist or Integrated Cruise Assit  swtich Stuck state";
CM_ SG_ 620 UINM_PADS_Custom2SWSt "PADS Custom2  swtich state";
CM_ SG_ 620 UINM_PADS_Custom2SWStVD "PADS_Custom2SWSt validity";
CM_ SG_ 620 UINM_PADS_Custom2SWStuckSt "PADS Custom2  swtich stuck state";
CM_ SG_ 620 UINM_PADS_ACCSWSt "Indicates PADS's ACC swtich state";
CM_ SG_ 620 UINM_PADS_VoltageFaultSt "Indicates PADS's Supply voltage fault state";
CM_ SG_ 620 UINM_PADS_L3SWSt "Indicates PADS's L3 swtich state";
CM_ SG_ 620 UINM_PADS_L3SWStVD "Indicates PADS's L3 swtich state Validity";
CM_ SG_ 620 UINM_PADS_L3SWStuckSt "Indicates PADS's IDC MODE swtich stuck state";
CM_ SG_ 620 IL_PADS_LightbarSt "Steering wheel ambient light bar current status";

BA_DEF_ BO_  "GenMsgCycleTime" INT 0 0;
BA_DEF_ BO_  "GenMsgCycleTimeFast" INT 0 0;
BA_DEF_ BO_  "GenMsgSendType" ENUM  "Periodic","Event","IfActive","POE","PA","FixedPeriodic","Event","EnabledPeriodic","NotUsed","NotUsed","EventPeriodic","NotUsed","NotUsed","NoMsgSendType";
BA_DEF_ BO_  "VFrameFormat" ENUM  "StandardCAN","ExtendedCAN","reserved","reserved","reserved","reserved","reserved","reserved","reserved","reserved","reserved","reserved","reserved","reserved","StandardCAN_FD","ExtendedCAN_FD";
BA_DEF_ BO_  "CANFD_BRS" ENUM  "0","1";
BA_DEF_ SG_  "EventCommandSignal" ENUM  "No","Yes";
BA_DEF_ SG_  "GatewayedSignals" ENUM  "No","Yes";
BA_DEF_ SG_  "GenSigInactiveValue" HEX 0 0;
BA_DEF_ SG_  "GenSigInvalidValue" HEX 0 0;
BA_DEF_ SG_  "GenSigSendType" ENUM  "Trigger","Passive","Cyclic","OnWrite","OnWriteWithRepetition","OnChange","OnChangeWithRepetition","IfActive","IfActiveWithRepetition","NoSigSendType";
BA_DEF_ SG_  "GenSigStartValue" HEX 0 0;
BA_DEF_ SG_  "GenSigTimeoutValue" HEX 0 0;
BA_DEF_ SG_  "Remark" STRING ;
BA_ "GenMsgCycleTime" BO_ 696 40;
BA_ "GenMsgCycleTimeFast" BO_ 696 0;
BA_ "GenMsgSendType" BO_ 696 0;
BA_ "VFrameFormat" BO_ 696 14;
BA_ "CANFD_BRS" BO_ 696 1;
BA_ "GenMsgCycleTime" BO_ 696 40;
BA_ "GenMsgCycleTimeFast" BO_ 696 0;
BA_ "GenMsgSendType" BO_ 696 0;
BA_ "VFrameFormat" BO_ 696 14;
BA_ "CANFD_BRS" BO_ 696 1;
BA_ "GenMsgCycleTime" BO_ 696 40;
BA_ "GenMsgCycleTimeFast" BO_ 696 0;
BA_ "GenMsgSendType" BO_ 696 0;
BA_ "VFrameFormat" BO_ 696 14;
BA_ "CANFD_BRS" BO_ 696 1;
BA_ "GenMsgCycleTime" BO_ 696 40;
BA_ "GenMsgCycleTimeFast" BO_ 696 0;
BA_ "GenMsgSendType" BO_ 696 0;
BA_ "VFrameFormat" BO_ 696 14;
BA_ "CANFD_BRS" BO_ 696 1;
BA_ "GenMsgCycleTime" BO_ 696 40;
BA_ "GenMsgCycleTimeFast" BO_ 696 0;
BA_ "GenMsgSendType" BO_ 696 0;
BA_ "VFrameFormat" BO_ 696 14;
BA_ "CANFD_BRS" BO_ 696 1;
BA_ "GenMsgCycleTime" BO_ 696 40;
BA_ "GenMsgCycleTimeFast" BO_ 696 0;
BA_ "GenMsgSendType" BO_ 696 0;
BA_ "VFrameFormat" BO_ 696 14;
BA_ "CANFD_BRS" BO_ 696 1;
BA_ "GenMsgCycleTime" BO_ 696 40;
BA_ "GenMsgCycleTimeFast" BO_ 696 0;
BA_ "GenMsgSendType" BO_ 696 0;
BA_ "VFrameFormat" BO_ 696 14;
BA_ "CANFD_BRS" BO_ 696 1;
BA_ "GenMsgCycleTime" BO_ 696 40;
BA_ "GenMsgCycleTimeFast" BO_ 696 0;
BA_ "GenMsgSendType" BO_ 696 0;
BA_ "VFrameFormat" BO_ 696 14;
BA_ "CANFD_BRS" BO_ 696 1;
BA_ "GenMsgCycleTime" BO_ 696 40;
BA_ "GenMsgCycleTimeFast" BO_ 696 0;
BA_ "GenMsgSendType" BO_ 696 0;
BA_ "VFrameFormat" BO_ 696 14;
BA_ "CANFD_BRS" BO_ 696 1;
BA_ "GenMsgCycleTime" BO_ 696 40;
BA_ "GenMsgCycleTimeFast" BO_ 696 0;
BA_ "GenMsgSendType" BO_ 696 0;
BA_ "VFrameFormat" BO_ 696 14;
BA_ "CANFD_BRS" BO_ 696 1;
BA_ "GenMsgCycleTime" BO_ 696 40;
BA_ "GenMsgCycleTimeFast" BO_ 696 0;
BA_ "GenMsgSendType" BO_ 696 0;
BA_ "VFrameFormat" BO_ 696 14;
BA_ "CANFD_BRS" BO_ 696 1;
BA_ "GenMsgCycleTime" BO_ 696 40;
BA_ "GenMsgCycleTimeFast" BO_ 696 0;
BA_ "GenMsgSendType" BO_ 696 0;
BA_ "VFrameFormat" BO_ 696 14;
BA_ "CANFD_BRS" BO_ 696 1;
BA_ "GenMsgCycleTime" BO_ 696 40;
BA_ "GenMsgCycleTimeFast" BO_ 696 0;
BA_ "GenMsgSendType" BO_ 696 0;
BA_ "VFrameFormat" BO_ 696 14;
BA_ "CANFD_BRS" BO_ 696 1;
BA_ "GenMsgCycleTime" BO_ 696 40;
BA_ "GenMsgCycleTimeFast" BO_ 696 0;
BA_ "GenMsgSendType" BO_ 696 0;
BA_ "VFrameFormat" BO_ 696 14;
BA_ "CANFD_BRS" BO_ 696 1;
BA_ "GenMsgCycleTime" BO_ 696 40;
BA_ "GenMsgCycleTimeFast" BO_ 696 0;
BA_ "GenMsgSendType" BO_ 696 0;
BA_ "VFrameFormat" BO_ 696 14;
BA_ "CANFD_BRS" BO_ 696 1;
BA_ "GenMsgCycleTime" BO_ 696 40;
BA_ "GenMsgCycleTimeFast" BO_ 696 0;
BA_ "GenMsgSendType" BO_ 696 0;
BA_ "VFrameFormat" BO_ 696 14;
BA_ "CANFD_BRS" BO_ 696 1;
BA_ "GenMsgCycleTime" BO_ 696 40;
BA_ "GenMsgCycleTimeFast" BO_ 696 0;
BA_ "GenMsgSendType" BO_ 696 0;
BA_ "VFrameFormat" BO_ 696 14;
BA_ "CANFD_BRS" BO_ 696 1;
BA_ "GenMsgCycleTime" BO_ 696 40;
BA_ "GenMsgCycleTimeFast" BO_ 696 0;
BA_ "GenMsgSendType" BO_ 696 0;
BA_ "VFrameFormat" BO_ 696 14;
BA_ "CANFD_BRS" BO_ 696 1;
BA_ "GenMsgCycleTime" BO_ 696 40;
BA_ "GenMsgCycleTimeFast" BO_ 696 0;
BA_ "GenMsgSendType" BO_ 696 0;
BA_ "VFrameFormat" BO_ 696 14;
BA_ "CANFD_BRS" BO_ 696 1;
BA_ "GenMsgCycleTime" BO_ 696 40;
BA_ "GenMsgCycleTimeFast" BO_ 696 0;
BA_ "GenMsgSendType" BO_ 696 0;
BA_ "VFrameFormat" BO_ 696 14;
BA_ "CANFD_BRS" BO_ 696 1;
BA_ "GenMsgCycleTime" BO_ 696 40;
BA_ "GenMsgCycleTimeFast" BO_ 696 0;
BA_ "GenMsgSendType" BO_ 696 0;
BA_ "VFrameFormat" BO_ 696 14;
BA_ "CANFD_BRS" BO_ 696 1;
BA_ "GenMsgCycleTime" BO_ 696 40;
BA_ "GenMsgCycleTimeFast" BO_ 696 0;
BA_ "GenMsgSendType" BO_ 696 0;
BA_ "VFrameFormat" BO_ 696 14;
BA_ "CANFD_BRS" BO_ 696 1;
BA_ "GenMsgCycleTime" BO_ 696 40;
BA_ "GenMsgCycleTimeFast" BO_ 696 0;
BA_ "GenMsgSendType" BO_ 696 0;
BA_ "VFrameFormat" BO_ 696 14;
BA_ "CANFD_BRS" BO_ 696 1;
BA_ "GenMsgCycleTime" BO_ 696 40;
BA_ "GenMsgCycleTimeFast" BO_ 696 0;
BA_ "GenMsgSendType" BO_ 696 0;
BA_ "VFrameFormat" BO_ 696 14;
BA_ "CANFD_BRS" BO_ 696 1;
BA_ "GenMsgCycleTime" BO_ 696 40;
BA_ "GenMsgCycleTimeFast" BO_ 696 0;
BA_ "GenMsgSendType" BO_ 696 0;
BA_ "VFrameFormat" BO_ 696 14;
BA_ "CANFD_BRS" BO_ 696 1;
BA_ "GenMsgCycleTime" BO_ 696 40;
BA_ "GenMsgCycleTimeFast" BO_ 696 0;
BA_ "GenMsgSendType" BO_ 696 0;
BA_ "VFrameFormat" BO_ 696 14;
BA_ "CANFD_BRS" BO_ 696 1;
BA_ "GenMsgCycleTime" BO_ 696 40;
BA_ "GenMsgCycleTimeFast" BO_ 696 0;
BA_ "GenMsgSendType" BO_ 696 0;
BA_ "VFrameFormat" BO_ 696 14;
BA_ "CANFD_BRS" BO_ 696 1;
BA_ "GenMsgCycleTime" BO_ 696 40;
BA_ "GenMsgCycleTimeFast" BO_ 696 0;
BA_ "GenMsgSendType" BO_ 696 0;
BA_ "VFrameFormat" BO_ 696 14;
BA_ "CANFD_BRS" BO_ 696 1;
BA_ "GenMsgCycleTime" BO_ 696 40;
BA_ "GenMsgCycleTimeFast" BO_ 696 0;
BA_ "GenMsgSendType" BO_ 696 0;
BA_ "VFrameFormat" BO_ 696 14;
BA_ "CANFD_BRS" BO_ 696 1;
BA_ "GenMsgCycleTime" BO_ 696 40;
BA_ "GenMsgCycleTimeFast" BO_ 696 0;
BA_ "GenMsgSendType" BO_ 696 0;
BA_ "VFrameFormat" BO_ 696 14;
BA_ "CANFD_BRS" BO_ 696 1;
BA_ "GenMsgCycleTime" BO_ 696 40;
BA_ "GenMsgCycleTimeFast" BO_ 696 0;
BA_ "GenMsgSendType" BO_ 696 0;
BA_ "VFrameFormat" BO_ 696 14;
BA_ "CANFD_BRS" BO_ 696 1;
BA_ "GenMsgCycleTime" BO_ 696 40;
BA_ "GenMsgCycleTimeFast" BO_ 696 0;
BA_ "GenMsgSendType" BO_ 696 0;
BA_ "VFrameFormat" BO_ 696 14;
BA_ "CANFD_BRS" BO_ 696 1;
BA_ "GenMsgCycleTime" BO_ 696 40;
BA_ "GenMsgCycleTimeFast" BO_ 696 0;
BA_ "GenMsgSendType" BO_ 696 0;
BA_ "VFrameFormat" BO_ 696 14;
BA_ "CANFD_BRS" BO_ 696 1;
BA_ "GenMsgCycleTime" BO_ 696 40;
BA_ "GenMsgCycleTimeFast" BO_ 696 0;
BA_ "GenMsgSendType" BO_ 696 0;
BA_ "VFrameFormat" BO_ 696 14;
BA_ "CANFD_BRS" BO_ 696 1;
BA_ "GenMsgCycleTime" BO_ 696 40;
BA_ "GenMsgCycleTimeFast" BO_ 696 0;
BA_ "GenMsgSendType" BO_ 696 0;
BA_ "VFrameFormat" BO_ 696 14;
BA_ "CANFD_BRS" BO_ 696 1;
BA_ "GenMsgCycleTime" BO_ 696 40;
BA_ "GenMsgCycleTimeFast" BO_ 696 0;
BA_ "GenMsgSendType" BO_ 696 0;
BA_ "VFrameFormat" BO_ 696 14;
BA_ "CANFD_BRS" BO_ 696 1;
BA_ "GenMsgCycleTime" BO_ 696 40;
BA_ "GenMsgCycleTimeFast" BO_ 696 0;
BA_ "GenMsgSendType" BO_ 696 0;
BA_ "VFrameFormat" BO_ 696 14;
BA_ "CANFD_BRS" BO_ 696 1;
BA_ "GenMsgCycleTime" BO_ 696 40;
BA_ "GenMsgCycleTimeFast" BO_ 696 0;
BA_ "GenMsgSendType" BO_ 696 0;
BA_ "VFrameFormat" BO_ 696 14;
BA_ "CANFD_BRS" BO_ 696 1;
BA_ "GenMsgCycleTime" BO_ 696 40;
BA_ "GenMsgCycleTimeFast" BO_ 696 0;
BA_ "GenMsgSendType" BO_ 696 0;
BA_ "VFrameFormat" BO_ 696 14;
BA_ "CANFD_BRS" BO_ 696 1;
BA_ "GenMsgCycleTime" BO_ 696 40;
BA_ "GenMsgCycleTimeFast" BO_ 696 0;
BA_ "GenMsgSendType" BO_ 696 0;
BA_ "VFrameFormat" BO_ 696 14;
BA_ "CANFD_BRS" BO_ 696 1;
BA_ "GenMsgCycleTime" BO_ 696 40;
BA_ "GenMsgCycleTimeFast" BO_ 696 0;
BA_ "GenMsgSendType" BO_ 696 0;
BA_ "VFrameFormat" BO_ 696 14;
BA_ "CANFD_BRS" BO_ 696 1;
BA_ "GenMsgCycleTime" BO_ 696 40;
BA_ "GenMsgCycleTimeFast" BO_ 696 0;
BA_ "GenMsgSendType" BO_ 696 0;
BA_ "VFrameFormat" BO_ 696 14;
BA_ "CANFD_BRS" BO_ 696 1;
BA_ "GenMsgCycleTime" BO_ 696 40;
BA_ "GenMsgCycleTimeFast" BO_ 696 0;
BA_ "GenMsgSendType" BO_ 696 0;
BA_ "VFrameFormat" BO_ 696 14;
BA_ "CANFD_BRS" BO_ 696 1;
BA_ "GenMsgCycleTime" BO_ 696 40;
BA_ "GenMsgCycleTimeFast" BO_ 696 0;
BA_ "GenMsgSendType" BO_ 696 0;
BA_ "VFrameFormat" BO_ 696 14;
BA_ "CANFD_BRS" BO_ 696 1;
BA_ "GenMsgCycleTime" BO_ 696 40;
BA_ "GenMsgCycleTimeFast" BO_ 696 0;
BA_ "GenMsgSendType" BO_ 696 0;
BA_ "VFrameFormat" BO_ 696 14;
BA_ "CANFD_BRS" BO_ 696 1;
BA_ "GenMsgCycleTime" BO_ 696 40;
BA_ "GenMsgCycleTimeFast" BO_ 696 0;
BA_ "GenMsgSendType" BO_ 696 0;
BA_ "VFrameFormat" BO_ 696 14;
BA_ "CANFD_BRS" BO_ 696 1;
BA_ "GenMsgCycleTime" BO_ 696 40;
BA_ "GenMsgCycleTimeFast" BO_ 696 0;
BA_ "GenMsgSendType" BO_ 696 0;
BA_ "VFrameFormat" BO_ 696 14;
BA_ "CANFD_BRS" BO_ 696 1;
BA_ "GenMsgCycleTime" BO_ 696 40;
BA_ "GenMsgCycleTimeFast" BO_ 696 0;
BA_ "GenMsgSendType" BO_ 696 0;
BA_ "VFrameFormat" BO_ 696 14;
BA_ "CANFD_BRS" BO_ 696 1;
BA_ "GenMsgCycleTime" BO_ 696 40;
BA_ "GenMsgCycleTimeFast" BO_ 696 0;
BA_ "GenMsgSendType" BO_ 696 0;
BA_ "VFrameFormat" BO_ 696 14;
BA_ "CANFD_BRS" BO_ 696 1;
BA_ "GenMsgCycleTime" BO_ 696 40;
BA_ "GenMsgCycleTimeFast" BO_ 696 0;
BA_ "GenMsgSendType" BO_ 696 0;
BA_ "VFrameFormat" BO_ 696 14;
BA_ "CANFD_BRS" BO_ 696 1;
BA_ "GenMsgCycleTime" BO_ 696 40;
BA_ "GenMsgCycleTimeFast" BO_ 696 0;
BA_ "GenMsgSendType" BO_ 696 0;
BA_ "VFrameFormat" BO_ 696 14;
BA_ "CANFD_BRS" BO_ 696 1;
BA_ "GenMsgCycleTime" BO_ 696 40;
BA_ "GenMsgCycleTimeFast" BO_ 696 0;
BA_ "GenMsgSendType" BO_ 696 0;
BA_ "VFrameFormat" BO_ 696 14;
BA_ "CANFD_BRS" BO_ 696 1;
BA_ "GenMsgCycleTime" BO_ 696 40;
BA_ "GenMsgCycleTimeFast" BO_ 696 0;
BA_ "GenMsgSendType" BO_ 696 0;
BA_ "VFrameFormat" BO_ 696 14;
BA_ "CANFD_BRS" BO_ 696 1;
BA_ "GenMsgCycleTime" BO_ 696 40;
BA_ "GenMsgCycleTimeFast" BO_ 696 0;
BA_ "GenMsgSendType" BO_ 696 0;
BA_ "VFrameFormat" BO_ 696 14;
BA_ "CANFD_BRS" BO_ 696 1;
BA_ "GenMsgCycleTime" BO_ 696 40;
BA_ "GenMsgCycleTimeFast" BO_ 696 0;
BA_ "GenMsgSendType" BO_ 696 0;
BA_ "VFrameFormat" BO_ 696 14;
BA_ "CANFD_BRS" BO_ 696 1;
BA_ "GenMsgCycleTime" BO_ 696 40;
BA_ "GenMsgCycleTimeFast" BO_ 696 0;
BA_ "GenMsgSendType" BO_ 696 0;
BA_ "VFrameFormat" BO_ 696 14;
BA_ "CANFD_BRS" BO_ 696 1;
BA_ "GenMsgCycleTime" BO_ 696 40;
BA_ "GenMsgCycleTimeFast" BO_ 696 0;
BA_ "GenMsgSendType" BO_ 696 0;
BA_ "VFrameFormat" BO_ 696 14;
BA_ "CANFD_BRS" BO_ 696 1;
BA_ "GenMsgCycleTime" BO_ 696 40;
BA_ "GenMsgCycleTimeFast" BO_ 696 0;
BA_ "GenMsgSendType" BO_ 696 0;
BA_ "VFrameFormat" BO_ 696 14;
BA_ "CANFD_BRS" BO_ 696 1;
BA_ "GenMsgCycleTime" BO_ 696 40;
BA_ "GenMsgCycleTimeFast" BO_ 696 0;
BA_ "GenMsgSendType" BO_ 696 0;
BA_ "VFrameFormat" BO_ 696 14;
BA_ "CANFD_BRS" BO_ 696 1;
BA_ "GenMsgCycleTime" BO_ 696 40;
BA_ "GenMsgCycleTimeFast" BO_ 696 0;
BA_ "GenMsgSendType" BO_ 696 0;
BA_ "VFrameFormat" BO_ 696 14;
BA_ "CANFD_BRS" BO_ 696 1;
BA_ "GenMsgCycleTime" BO_ 696 40;
BA_ "GenMsgCycleTimeFast" BO_ 696 0;
BA_ "GenMsgSendType" BO_ 696 0;
BA_ "VFrameFormat" BO_ 696 14;
BA_ "CANFD_BRS" BO_ 696 1;
BA_ "GenMsgCycleTime" BO_ 696 40;
BA_ "GenMsgCycleTimeFast" BO_ 696 0;
BA_ "GenMsgSendType" BO_ 696 0;
BA_ "VFrameFormat" BO_ 696 14;
BA_ "CANFD_BRS" BO_ 696 1;
BA_ "GenMsgCycleTime" BO_ 696 40;
BA_ "GenMsgCycleTimeFast" BO_ 696 0;
BA_ "GenMsgSendType" BO_ 696 0;
BA_ "VFrameFormat" BO_ 696 14;
BA_ "CANFD_BRS" BO_ 696 1;
BA_ "GenMsgCycleTime" BO_ 696 40;
BA_ "GenMsgCycleTimeFast" BO_ 696 0;
BA_ "GenMsgSendType" BO_ 696 0;
BA_ "VFrameFormat" BO_ 696 14;
BA_ "CANFD_BRS" BO_ 696 1;
BA_ "GenMsgCycleTime" BO_ 696 40;
BA_ "GenMsgCycleTimeFast" BO_ 696 0;
BA_ "GenMsgSendType" BO_ 696 0;
BA_ "VFrameFormat" BO_ 696 14;
BA_ "CANFD_BRS" BO_ 696 1;
BA_ "GenMsgCycleTime" BO_ 696 40;
BA_ "GenMsgCycleTimeFast" BO_ 696 0;
BA_ "GenMsgSendType" BO_ 696 0;
BA_ "VFrameFormat" BO_ 696 14;
BA_ "CANFD_BRS" BO_ 696 1;
BA_ "GenMsgCycleTime" BO_ 696 40;
BA_ "GenMsgCycleTimeFast" BO_ 696 0;
BA_ "GenMsgSendType" BO_ 696 0;
BA_ "VFrameFormat" BO_ 696 14;
BA_ "CANFD_BRS" BO_ 696 1;
BA_ "GenMsgCycleTime" BO_ 696 40;
BA_ "GenMsgCycleTimeFast" BO_ 696 0;
BA_ "GenMsgSendType" BO_ 696 0;
BA_ "VFrameFormat" BO_ 696 14;
BA_ "CANFD_BRS" BO_ 696 1;
BA_ "GenMsgCycleTime" BO_ 696 40;
BA_ "GenMsgCycleTimeFast" BO_ 696 0;
BA_ "GenMsgSendType" BO_ 696 0;
BA_ "VFrameFormat" BO_ 696 14;
BA_ "CANFD_BRS" BO_ 696 1;
BA_ "GenMsgCycleTime" BO_ 696 40;
BA_ "GenMsgCycleTimeFast" BO_ 696 0;
BA_ "GenMsgSendType" BO_ 696 0;
BA_ "VFrameFormat" BO_ 696 14;
BA_ "CANFD_BRS" BO_ 696 1;
BA_ "GenMsgCycleTime" BO_ 696 40;
BA_ "GenMsgCycleTimeFast" BO_ 696 0;
BA_ "GenMsgSendType" BO_ 696 0;
BA_ "VFrameFormat" BO_ 696 14;
BA_ "CANFD_BRS" BO_ 696 1;
BA_ "GenMsgCycleTime" BO_ 696 40;
BA_ "GenMsgCycleTimeFast" BO_ 696 0;
BA_ "GenMsgSendType" BO_ 696 0;
BA_ "VFrameFormat" BO_ 696 14;
BA_ "CANFD_BRS" BO_ 696 1;
BA_ "GenMsgCycleTime" BO_ 696 40;
BA_ "GenMsgCycleTimeFast" BO_ 696 0;
BA_ "GenMsgSendType" BO_ 696 0;
BA_ "VFrameFormat" BO_ 696 14;
BA_ "CANFD_BRS" BO_ 696 1;
BA_ "GenMsgCycleTime" BO_ 696 40;
BA_ "GenMsgCycleTimeFast" BO_ 696 0;
BA_ "GenMsgSendType" BO_ 696 0;
BA_ "VFrameFormat" BO_ 696 14;
BA_ "CANFD_BRS" BO_ 696 1;
BA_ "GenMsgCycleTime" BO_ 696 40;
BA_ "GenMsgCycleTimeFast" BO_ 696 0;
BA_ "GenMsgSendType" BO_ 696 0;
BA_ "VFrameFormat" BO_ 696 14;
BA_ "CANFD_BRS" BO_ 696 1;
BA_ "GenMsgCycleTime" BO_ 696 40;
BA_ "GenMsgCycleTimeFast" BO_ 696 0;
BA_ "GenMsgSendType" BO_ 696 0;
BA_ "VFrameFormat" BO_ 696 14;
BA_ "CANFD_BRS" BO_ 696 1;
BA_ "GenMsgCycleTime" BO_ 696 40;
BA_ "GenMsgCycleTimeFast" BO_ 696 0;
BA_ "GenMsgSendType" BO_ 696 0;
BA_ "VFrameFormat" BO_ 696 14;
BA_ "CANFD_BRS" BO_ 696 1;
BA_ "GenMsgCycleTime" BO_ 696 40;
BA_ "GenMsgCycleTimeFast" BO_ 696 0;
BA_ "GenMsgSendType" BO_ 696 0;
BA_ "VFrameFormat" BO_ 696 14;
BA_ "CANFD_BRS" BO_ 696 1;
BA_ "GenMsgCycleTime" BO_ 696 40;
BA_ "GenMsgCycleTimeFast" BO_ 696 0;
BA_ "GenMsgSendType" BO_ 696 0;
BA_ "VFrameFormat" BO_ 696 14;
BA_ "CANFD_BRS" BO_ 696 1;
BA_ "GenMsgCycleTime" BO_ 696 40;
BA_ "GenMsgCycleTimeFast" BO_ 696 0;
BA_ "GenMsgSendType" BO_ 696 0;
BA_ "VFrameFormat" BO_ 696 14;
BA_ "CANFD_BRS" BO_ 696 1;
BA_ "GenMsgCycleTime" BO_ 696 40;
BA_ "GenMsgCycleTimeFast" BO_ 696 0;
BA_ "GenMsgSendType" BO_ 696 0;
BA_ "VFrameFormat" BO_ 696 14;
BA_ "CANFD_BRS" BO_ 696 1;
BA_ "GenMsgCycleTime" BO_ 696 40;
BA_ "GenMsgCycleTimeFast" BO_ 696 0;
BA_ "GenMsgSendType" BO_ 696 0;
BA_ "VFrameFormat" BO_ 696 14;
BA_ "CANFD_BRS" BO_ 696 1;
BA_ "GenMsgCycleTime" BO_ 696 40;
BA_ "GenMsgCycleTimeFast" BO_ 696 0;
BA_ "GenMsgSendType" BO_ 696 0;
BA_ "VFrameFormat" BO_ 696 14;
BA_ "CANFD_BRS" BO_ 696 1;
BA_ "GenMsgCycleTime" BO_ 696 40;
BA_ "GenMsgCycleTimeFast" BO_ 696 0;
BA_ "GenMsgSendType" BO_ 696 0;
BA_ "VFrameFormat" BO_ 696 14;
BA_ "CANFD_BRS" BO_ 696 1;
BA_ "GenMsgCycleTime" BO_ 696 40;
BA_ "GenMsgCycleTimeFast" BO_ 696 0;
BA_ "GenMsgSendType" BO_ 696 0;
BA_ "VFrameFormat" BO_ 696 14;
BA_ "CANFD_BRS" BO_ 696 1;
BA_ "GenMsgCycleTime" BO_ 696 40;
BA_ "GenMsgCycleTimeFast" BO_ 696 0;
BA_ "GenMsgSendType" BO_ 696 0;
BA_ "VFrameFormat" BO_ 696 14;
BA_ "CANFD_BRS" BO_ 696 1;
BA_ "GenMsgCycleTime" BO_ 696 40;
BA_ "GenMsgCycleTimeFast" BO_ 696 0;
BA_ "GenMsgSendType" BO_ 696 0;
BA_ "VFrameFormat" BO_ 696 14;
BA_ "CANFD_BRS" BO_ 696 1;
BA_ "GenMsgCycleTime" BO_ 696 40;
BA_ "GenMsgCycleTimeFast" BO_ 696 0;
BA_ "GenMsgSendType" BO_ 696 0;
BA_ "VFrameFormat" BO_ 696 14;
BA_ "CANFD_BRS" BO_ 696 1;
BA_ "GenMsgCycleTime" BO_ 696 40;
BA_ "GenMsgCycleTimeFast" BO_ 696 0;
BA_ "GenMsgSendType" BO_ 696 0;
BA_ "VFrameFormat" BO_ 696 14;
BA_ "CANFD_BRS" BO_ 696 1;
BA_ "GenMsgCycleTime" BO_ 696 40;
BA_ "GenMsgCycleTimeFast" BO_ 696 0;
BA_ "GenMsgSendType" BO_ 696 0;
BA_ "VFrameFormat" BO_ 696 14;
BA_ "CANFD_BRS" BO_ 696 1;
BA_ "GenMsgCycleTime" BO_ 696 40;
BA_ "GenMsgCycleTimeFast" BO_ 696 0;
BA_ "GenMsgSendType" BO_ 696 0;
BA_ "VFrameFormat" BO_ 696 14;
BA_ "CANFD_BRS" BO_ 696 1;
BA_ "GenMsgCycleTime" BO_ 696 40;
BA_ "GenMsgCycleTimeFast" BO_ 696 0;
BA_ "GenMsgSendType" BO_ 696 0;
BA_ "VFrameFormat" BO_ 696 14;
BA_ "CANFD_BRS" BO_ 696 1;
BA_ "GenMsgCycleTime" BO_ 696 40;
BA_ "GenMsgCycleTimeFast" BO_ 696 0;
BA_ "GenMsgSendType" BO_ 696 0;
BA_ "VFrameFormat" BO_ 696 14;
BA_ "CANFD_BRS" BO_ 696 1;
BA_ "GenMsgCycleTime" BO_ 696 40;
BA_ "GenMsgCycleTimeFast" BO_ 696 0;
BA_ "GenMsgSendType" BO_ 696 0;
BA_ "VFrameFormat" BO_ 696 14;
BA_ "CANFD_BRS" BO_ 696 1;
BA_ "GenMsgCycleTime" BO_ 134 0;
BA_ "GenMsgCycleTimeFast" BO_ 134 0;
BA_ "GenMsgSendType" BO_ 134 1;
BA_ "VFrameFormat" BO_ 134 14;
BA_ "CANFD_BRS" BO_ 134 1;
BA_ "GenMsgCycleTime" BO_ 793 100;
BA_ "GenMsgCycleTimeFast" BO_ 793 0;
BA_ "GenMsgSendType" BO_ 793 0;
BA_ "VFrameFormat" BO_ 793 14;
BA_ "CANFD_BRS" BO_ 793 1;
BA_ "GenMsgCycleTime" BO_ 793 100;
BA_ "GenMsgCycleTimeFast" BO_ 793 0;
BA_ "GenMsgSendType" BO_ 793 0;
BA_ "VFrameFormat" BO_ 793 14;
BA_ "CANFD_BRS" BO_ 793 1;
BA_ "GenMsgCycleTime" BO_ 793 100;
BA_ "GenMsgCycleTimeFast" BO_ 793 0;
BA_ "GenMsgSendType" BO_ 793 0;
BA_ "VFrameFormat" BO_ 793 14;
BA_ "CANFD_BRS" BO_ 793 1;
BA_ "GenMsgCycleTime" BO_ 793 100;
BA_ "GenMsgCycleTimeFast" BO_ 793 0;
BA_ "GenMsgSendType" BO_ 793 0;
BA_ "VFrameFormat" BO_ 793 14;
BA_ "CANFD_BRS" BO_ 793 1;
BA_ "GenMsgCycleTime" BO_ 1024 500;
BA_ "GenMsgCycleTimeFast" BO_ 1024 0;
BA_ "GenMsgSendType" BO_ 1024 0;
BA_ "VFrameFormat" BO_ 1024 14;
BA_ "CANFD_BRS" BO_ 1024 1;
BA_ "GenMsgCycleTime" BO_ 1024 500;
BA_ "GenMsgCycleTimeFast" BO_ 1024 0;
BA_ "GenMsgSendType" BO_ 1024 0;
BA_ "VFrameFormat" BO_ 1024 14;
BA_ "CANFD_BRS" BO_ 1024 1;
BA_ "GenMsgCycleTime" BO_ 1024 500;
BA_ "GenMsgCycleTimeFast" BO_ 1024 0;
BA_ "GenMsgSendType" BO_ 1024 0;
BA_ "VFrameFormat" BO_ 1024 14;
BA_ "CANFD_BRS" BO_ 1024 1;
BA_ "GenMsgCycleTime" BO_ 1024 500;
BA_ "GenMsgCycleTimeFast" BO_ 1024 0;
BA_ "GenMsgSendType" BO_ 1024 0;
BA_ "VFrameFormat" BO_ 1024 14;
BA_ "CANFD_BRS" BO_ 1024 1;
BA_ "GenMsgCycleTime" BO_ 1024 500;
BA_ "GenMsgCycleTimeFast" BO_ 1024 0;
BA_ "GenMsgSendType" BO_ 1024 0;
BA_ "VFrameFormat" BO_ 1024 14;
BA_ "CANFD_BRS" BO_ 1024 1;
BA_ "GenMsgCycleTime" BO_ 1024 500;
BA_ "GenMsgCycleTimeFast" BO_ 1024 0;
BA_ "GenMsgSendType" BO_ 1024 0;
BA_ "VFrameFormat" BO_ 1024 14;
BA_ "CANFD_BRS" BO_ 1024 1;
BA_ "GenMsgCycleTime" BO_ 1024 500;
BA_ "GenMsgCycleTimeFast" BO_ 1024 0;
BA_ "GenMsgSendType" BO_ 1024 0;
BA_ "VFrameFormat" BO_ 1024 14;
BA_ "CANFD_BRS" BO_ 1024 1;
BA_ "GenMsgCycleTime" BO_ 1024 500;
BA_ "GenMsgCycleTimeFast" BO_ 1024 0;
BA_ "GenMsgSendType" BO_ 1024 0;
BA_ "VFrameFormat" BO_ 1024 14;
BA_ "CANFD_BRS" BO_ 1024 1;
BA_ "GenMsgCycleTime" BO_ 476 1000;
BA_ "GenMsgCycleTimeFast" BO_ 476 40;
BA_ "GenMsgSendType" BO_ 476 4;
BA_ "VFrameFormat" BO_ 476 14;
BA_ "CANFD_BRS" BO_ 476 1;
BA_ "GenMsgCycleTime" BO_ 476 1000;
BA_ "GenMsgCycleTimeFast" BO_ 476 40;
BA_ "GenMsgSendType" BO_ 476 4;
BA_ "VFrameFormat" BO_ 476 14;
BA_ "CANFD_BRS" BO_ 476 1;
BA_ "GenMsgCycleTime" BO_ 1657 0;
BA_ "GenMsgCycleTimeFast" BO_ 1657 0;
BA_ "GenMsgSendType" BO_ 1657 1;
BA_ "VFrameFormat" BO_ 1657 14;
BA_ "CANFD_BRS" BO_ 1657 1;
BA_ "GenMsgCycleTime" BO_ 1806 0;
BA_ "GenMsgCycleTimeFast" BO_ 1806 0;
BA_ "GenMsgSendType" BO_ 1806 1;
BA_ "VFrameFormat" BO_ 1806 14;
BA_ "CANFD_BRS" BO_ 1806 1;
BA_ "GenMsgCycleTime" BO_ 1854 0;
BA_ "GenMsgCycleTimeFast" BO_ 1854 0;
BA_ "GenMsgSendType" BO_ 1854 1;
BA_ "VFrameFormat" BO_ 1854 14;
BA_ "CANFD_BRS" BO_ 1854 1;
BA_ "GenMsgCycleTime" BO_ 1354 200;
BA_ "GenMsgCycleTimeFast" BO_ 1354 0;
BA_ "GenMsgSendType" BO_ 1354 0;
BA_ "VFrameFormat" BO_ 1354 0;
BA_ "CANFD_BRS" BO_ 1354 1;
BA_ "GenMsgCycleTime" BO_ 1354 200;
BA_ "GenMsgCycleTimeFast" BO_ 1354 0;
BA_ "GenMsgSendType" BO_ 1354 0;
BA_ "VFrameFormat" BO_ 1354 0;
BA_ "CANFD_BRS" BO_ 1354 1;
BA_ "GenMsgCycleTime" BO_ 1354 200;
BA_ "GenMsgCycleTimeFast" BO_ 1354 0;
BA_ "GenMsgSendType" BO_ 1354 0;
BA_ "VFrameFormat" BO_ 1354 0;
BA_ "CANFD_BRS" BO_ 1354 1;
BA_ "GenMsgCycleTime" BO_ 1354 200;
BA_ "GenMsgCycleTimeFast" BO_ 1354 0;
BA_ "GenMsgSendType" BO_ 1354 0;
BA_ "VFrameFormat" BO_ 1354 0;
BA_ "CANFD_BRS" BO_ 1354 1;
BA_ "GenMsgCycleTime" BO_ 1354 200;
BA_ "GenMsgCycleTimeFast" BO_ 1354 0;
BA_ "GenMsgSendType" BO_ 1354 0;
BA_ "VFrameFormat" BO_ 1354 0;
BA_ "CANFD_BRS" BO_ 1354 1;
BA_ "GenMsgCycleTime" BO_ 1354 200;
BA_ "GenMsgCycleTimeFast" BO_ 1354 0;
BA_ "GenMsgSendType" BO_ 1354 0;
BA_ "VFrameFormat" BO_ 1354 0;
BA_ "CANFD_BRS" BO_ 1354 1;
BA_ "GenMsgCycleTime" BO_ 987 50;
BA_ "GenMsgCycleTimeFast" BO_ 987 0;
BA_ "GenMsgSendType" BO_ 987 0;
BA_ "VFrameFormat" BO_ 987 14;
BA_ "CANFD_BRS" BO_ 987 1;
BA_ "GenMsgCycleTime" BO_ 987 50;
BA_ "GenMsgCycleTimeFast" BO_ 987 0;
BA_ "GenMsgSendType" BO_ 987 0;
BA_ "VFrameFormat" BO_ 987 14;
BA_ "CANFD_BRS" BO_ 987 1;
BA_ "GenMsgCycleTime" BO_ 987 50;
BA_ "GenMsgCycleTimeFast" BO_ 987 0;
BA_ "GenMsgSendType" BO_ 987 0;
BA_ "VFrameFormat" BO_ 987 14;
BA_ "CANFD_BRS" BO_ 987 1;
BA_ "GenMsgCycleTime" BO_ 987 50;
BA_ "GenMsgCycleTimeFast" BO_ 987 0;
BA_ "GenMsgSendType" BO_ 987 0;
BA_ "VFrameFormat" BO_ 987 14;
BA_ "CANFD_BRS" BO_ 987 1;
BA_ "GenMsgCycleTime" BO_ 987 50;
BA_ "GenMsgCycleTimeFast" BO_ 987 0;
BA_ "GenMsgSendType" BO_ 987 0;
BA_ "VFrameFormat" BO_ 987 14;
BA_ "CANFD_BRS" BO_ 987 1;
BA_ "GenMsgCycleTime" BO_ 987 50;
BA_ "GenMsgCycleTimeFast" BO_ 987 0;
BA_ "GenMsgSendType" BO_ 987 0;
BA_ "VFrameFormat" BO_ 987 14;
BA_ "CANFD_BRS" BO_ 987 1;
BA_ "GenMsgCycleTime" BO_ 987 50;
BA_ "GenMsgCycleTimeFast" BO_ 987 0;
BA_ "GenMsgSendType" BO_ 987 0;
BA_ "VFrameFormat" BO_ 987 14;
BA_ "CANFD_BRS" BO_ 987 1;
BA_ "GenMsgCycleTime" BO_ 987 50;
BA_ "GenMsgCycleTimeFast" BO_ 987 0;
BA_ "GenMsgSendType" BO_ 987 0;
BA_ "VFrameFormat" BO_ 987 14;
BA_ "CANFD_BRS" BO_ 987 1;
BA_ "GenMsgCycleTime" BO_ 987 50;
BA_ "GenMsgCycleTimeFast" BO_ 987 0;
BA_ "GenMsgSendType" BO_ 987 0;
BA_ "VFrameFormat" BO_ 987 14;
BA_ "CANFD_BRS" BO_ 987 1;
BA_ "GenMsgCycleTime" BO_ 987 50;
BA_ "GenMsgCycleTimeFast" BO_ 987 0;
BA_ "GenMsgSendType" BO_ 987 0;
BA_ "VFrameFormat" BO_ 987 14;
BA_ "CANFD_BRS" BO_ 987 1;
BA_ "GenMsgCycleTime" BO_ 987 50;
BA_ "GenMsgCycleTimeFast" BO_ 987 0;
BA_ "GenMsgSendType" BO_ 987 0;
BA_ "VFrameFormat" BO_ 987 14;
BA_ "CANFD_BRS" BO_ 987 1;
BA_ "GenMsgCycleTime" BO_ 987 50;
BA_ "GenMsgCycleTimeFast" BO_ 987 0;
BA_ "GenMsgSendType" BO_ 987 0;
BA_ "VFrameFormat" BO_ 987 14;
BA_ "CANFD_BRS" BO_ 987 1;
BA_ "GenMsgCycleTime" BO_ 987 50;
BA_ "GenMsgCycleTimeFast" BO_ 987 0;
BA_ "GenMsgSendType" BO_ 987 0;
BA_ "VFrameFormat" BO_ 987 14;
BA_ "CANFD_BRS" BO_ 987 1;
BA_ "GenMsgCycleTime" BO_ 987 50;
BA_ "GenMsgCycleTimeFast" BO_ 987 0;
BA_ "GenMsgSendType" BO_ 987 0;
BA_ "VFrameFormat" BO_ 987 14;
BA_ "CANFD_BRS" BO_ 987 1;
BA_ "GenMsgCycleTime" BO_ 987 50;
BA_ "GenMsgCycleTimeFast" BO_ 987 0;
BA_ "GenMsgSendType" BO_ 987 0;
BA_ "VFrameFormat" BO_ 987 14;
BA_ "CANFD_BRS" BO_ 987 1;
BA_ "GenMsgCycleTime" BO_ 987 50;
BA_ "GenMsgCycleTimeFast" BO_ 987 0;
BA_ "GenMsgSendType" BO_ 987 0;
BA_ "VFrameFormat" BO_ 987 14;
BA_ "CANFD_BRS" BO_ 987 1;
BA_ "GenMsgCycleTime" BO_ 987 50;
BA_ "GenMsgCycleTimeFast" BO_ 987 0;
BA_ "GenMsgSendType" BO_ 987 0;
BA_ "VFrameFormat" BO_ 987 14;
BA_ "CANFD_BRS" BO_ 987 1;
BA_ "GenMsgCycleTime" BO_ 987 50;
BA_ "GenMsgCycleTimeFast" BO_ 987 0;
BA_ "GenMsgSendType" BO_ 987 0;
BA_ "VFrameFormat" BO_ 987 14;
BA_ "CANFD_BRS" BO_ 987 1;
BA_ "GenMsgCycleTime" BO_ 987 50;
BA_ "GenMsgCycleTimeFast" BO_ 987 0;
BA_ "GenMsgSendType" BO_ 987 0;
BA_ "VFrameFormat" BO_ 987 14;
BA_ "CANFD_BRS" BO_ 987 1;
BA_ "GenMsgCycleTime" BO_ 987 50;
BA_ "GenMsgCycleTimeFast" BO_ 987 0;
BA_ "GenMsgSendType" BO_ 987 0;
BA_ "VFrameFormat" BO_ 987 14;
BA_ "CANFD_BRS" BO_ 987 1;
BA_ "GenMsgCycleTime" BO_ 987 50;
BA_ "GenMsgCycleTimeFast" BO_ 987 0;
BA_ "GenMsgSendType" BO_ 987 0;
BA_ "VFrameFormat" BO_ 987 14;
BA_ "CANFD_BRS" BO_ 987 1;
BA_ "GenMsgCycleTime" BO_ 987 50;
BA_ "GenMsgCycleTimeFast" BO_ 987 0;
BA_ "GenMsgSendType" BO_ 987 0;
BA_ "VFrameFormat" BO_ 987 14;
BA_ "CANFD_BRS" BO_ 987 1;
BA_ "GenMsgCycleTime" BO_ 1343 200;
BA_ "GenMsgCycleTimeFast" BO_ 1343 0;
BA_ "GenMsgSendType" BO_ 1343 0;
BA_ "VFrameFormat" BO_ 1343 0;
BA_ "CANFD_BRS" BO_ 1343 1;
BA_ "GenMsgCycleTime" BO_ 1343 200;
BA_ "GenMsgCycleTimeFast" BO_ 1343 0;
BA_ "GenMsgSendType" BO_ 1343 0;
BA_ "VFrameFormat" BO_ 1343 0;
BA_ "CANFD_BRS" BO_ 1343 1;
BA_ "GenMsgCycleTime" BO_ 1343 200;
BA_ "GenMsgCycleTimeFast" BO_ 1343 0;
BA_ "GenMsgSendType" BO_ 1343 0;
BA_ "VFrameFormat" BO_ 1343 0;
BA_ "CANFD_BRS" BO_ 1343 1;
BA_ "GenMsgCycleTime" BO_ 1343 200;
BA_ "GenMsgCycleTimeFast" BO_ 1343 0;
BA_ "GenMsgSendType" BO_ 1343 0;
BA_ "VFrameFormat" BO_ 1343 0;
BA_ "CANFD_BRS" BO_ 1343 1;
BA_ "GenMsgCycleTime" BO_ 1343 200;
BA_ "GenMsgCycleTimeFast" BO_ 1343 0;
BA_ "GenMsgSendType" BO_ 1343 0;
BA_ "VFrameFormat" BO_ 1343 0;
BA_ "CANFD_BRS" BO_ 1343 1;
BA_ "GenMsgCycleTime" BO_ 1343 200;
BA_ "GenMsgCycleTimeFast" BO_ 1343 0;
BA_ "GenMsgSendType" BO_ 1343 0;
BA_ "VFrameFormat" BO_ 1343 0;
BA_ "CANFD_BRS" BO_ 1343 1;
BA_ "GenMsgCycleTime" BO_ 932 50;
BA_ "GenMsgCycleTimeFast" BO_ 932 0;
BA_ "GenMsgSendType" BO_ 932 0;
BA_ "VFrameFormat" BO_ 932 14;
BA_ "CANFD_BRS" BO_ 932 1;
BA_ "GenMsgCycleTime" BO_ 932 50;
BA_ "GenMsgCycleTimeFast" BO_ 932 0;
BA_ "GenMsgSendType" BO_ 932 0;
BA_ "VFrameFormat" BO_ 932 14;
BA_ "CANFD_BRS" BO_ 932 1;
BA_ "GenMsgCycleTime" BO_ 932 50;
BA_ "GenMsgCycleTimeFast" BO_ 932 0;
BA_ "GenMsgSendType" BO_ 932 0;
BA_ "VFrameFormat" BO_ 932 14;
BA_ "CANFD_BRS" BO_ 932 1;
BA_ "GenMsgCycleTime" BO_ 932 50;
BA_ "GenMsgCycleTimeFast" BO_ 932 0;
BA_ "GenMsgSendType" BO_ 932 0;
BA_ "VFrameFormat" BO_ 932 14;
BA_ "CANFD_BRS" BO_ 932 1;
BA_ "GenMsgCycleTime" BO_ 932 50;
BA_ "GenMsgCycleTimeFast" BO_ 932 0;
BA_ "GenMsgSendType" BO_ 932 0;
BA_ "VFrameFormat" BO_ 932 14;
BA_ "CANFD_BRS" BO_ 932 1;
BA_ "GenMsgCycleTime" BO_ 932 50;
BA_ "GenMsgCycleTimeFast" BO_ 932 0;
BA_ "GenMsgSendType" BO_ 932 0;
BA_ "VFrameFormat" BO_ 932 14;
BA_ "CANFD_BRS" BO_ 932 1;
BA_ "GenMsgCycleTime" BO_ 932 50;
BA_ "GenMsgCycleTimeFast" BO_ 932 0;
BA_ "GenMsgSendType" BO_ 932 0;
BA_ "VFrameFormat" BO_ 932 14;
BA_ "CANFD_BRS" BO_ 932 1;
BA_ "GenMsgCycleTime" BO_ 932 50;
BA_ "GenMsgCycleTimeFast" BO_ 932 0;
BA_ "GenMsgSendType" BO_ 932 0;
BA_ "VFrameFormat" BO_ 932 14;
BA_ "CANFD_BRS" BO_ 932 1;
BA_ "GenMsgCycleTime" BO_ 932 50;
BA_ "GenMsgCycleTimeFast" BO_ 932 0;
BA_ "GenMsgSendType" BO_ 932 0;
BA_ "VFrameFormat" BO_ 932 14;
BA_ "CANFD_BRS" BO_ 932 1;
BA_ "GenMsgCycleTime" BO_ 932 50;
BA_ "GenMsgCycleTimeFast" BO_ 932 0;
BA_ "GenMsgSendType" BO_ 932 0;
BA_ "VFrameFormat" BO_ 932 14;
BA_ "CANFD_BRS" BO_ 932 1;
BA_ "GenMsgCycleTime" BO_ 932 50;
BA_ "GenMsgCycleTimeFast" BO_ 932 0;
BA_ "GenMsgSendType" BO_ 932 0;
BA_ "VFrameFormat" BO_ 932 14;
BA_ "CANFD_BRS" BO_ 932 1;
BA_ "GenMsgCycleTime" BO_ 932 50;
BA_ "GenMsgCycleTimeFast" BO_ 932 0;
BA_ "GenMsgSendType" BO_ 932 0;
BA_ "VFrameFormat" BO_ 932 14;
BA_ "CANFD_BRS" BO_ 932 1;
BA_ "GenMsgCycleTime" BO_ 932 50;
BA_ "GenMsgCycleTimeFast" BO_ 932 0;
BA_ "GenMsgSendType" BO_ 932 0;
BA_ "VFrameFormat" BO_ 932 14;
BA_ "CANFD_BRS" BO_ 932 1;
BA_ "GenMsgCycleTime" BO_ 932 50;
BA_ "GenMsgCycleTimeFast" BO_ 932 0;
BA_ "GenMsgSendType" BO_ 932 0;
BA_ "VFrameFormat" BO_ 932 14;
BA_ "CANFD_BRS" BO_ 932 1;
BA_ "GenMsgCycleTime" BO_ 932 50;
BA_ "GenMsgCycleTimeFast" BO_ 932 0;
BA_ "GenMsgSendType" BO_ 932 0;
BA_ "VFrameFormat" BO_ 932 14;
BA_ "CANFD_BRS" BO_ 932 1;
BA_ "GenMsgCycleTime" BO_ 932 50;
BA_ "GenMsgCycleTimeFast" BO_ 932 0;
BA_ "GenMsgSendType" BO_ 932 0;
BA_ "VFrameFormat" BO_ 932 14;
BA_ "CANFD_BRS" BO_ 932 1;
BA_ "GenMsgCycleTime" BO_ 932 50;
BA_ "GenMsgCycleTimeFast" BO_ 932 0;
BA_ "GenMsgSendType" BO_ 932 0;
BA_ "VFrameFormat" BO_ 932 14;
BA_ "CANFD_BRS" BO_ 932 1;
BA_ "GenMsgCycleTime" BO_ 932 50;
BA_ "GenMsgCycleTimeFast" BO_ 932 0;
BA_ "GenMsgSendType" BO_ 932 0;
BA_ "VFrameFormat" BO_ 932 14;
BA_ "CANFD_BRS" BO_ 932 1;
BA_ "GenMsgCycleTime" BO_ 932 50;
BA_ "GenMsgCycleTimeFast" BO_ 932 0;
BA_ "GenMsgSendType" BO_ 932 0;
BA_ "VFrameFormat" BO_ 932 14;
BA_ "CANFD_BRS" BO_ 932 1;
BA_ "GenMsgCycleTime" BO_ 932 50;
BA_ "GenMsgCycleTimeFast" BO_ 932 0;
BA_ "GenMsgSendType" BO_ 932 0;
BA_ "VFrameFormat" BO_ 932 14;
BA_ "CANFD_BRS" BO_ 932 1;
BA_ "GenMsgCycleTime" BO_ 932 50;
BA_ "GenMsgCycleTimeFast" BO_ 932 0;
BA_ "GenMsgSendType" BO_ 932 0;
BA_ "VFrameFormat" BO_ 932 14;
BA_ "CANFD_BRS" BO_ 932 1;
BA_ "GenMsgCycleTime" BO_ 932 50;
BA_ "GenMsgCycleTimeFast" BO_ 932 0;
BA_ "GenMsgSendType" BO_ 932 0;
BA_ "VFrameFormat" BO_ 932 14;
BA_ "CANFD_BRS" BO_ 932 1;
BA_ "GenMsgCycleTime" BO_ 932 50;
BA_ "GenMsgCycleTimeFast" BO_ 932 0;
BA_ "GenMsgSendType" BO_ 932 0;
BA_ "VFrameFormat" BO_ 932 14;
BA_ "CANFD_BRS" BO_ 932 1;
BA_ "GenMsgCycleTime" BO_ 932 50;
BA_ "GenMsgCycleTimeFast" BO_ 932 0;
BA_ "GenMsgSendType" BO_ 932 0;
BA_ "VFrameFormat" BO_ 932 14;
BA_ "CANFD_BRS" BO_ 932 1;
BA_ "GenMsgCycleTime" BO_ 932 50;
BA_ "GenMsgCycleTimeFast" BO_ 932 0;
BA_ "GenMsgSendType" BO_ 932 0;
BA_ "VFrameFormat" BO_ 932 14;
BA_ "CANFD_BRS" BO_ 932 1;
BA_ "GenMsgCycleTime" BO_ 620 60;
BA_ "GenMsgCycleTimeFast" BO_ 620 0;
BA_ "GenMsgSendType" BO_ 620 0;
BA_ "VFrameFormat" BO_ 620 14;
BA_ "CANFD_BRS" BO_ 620 1;
BA_ "GenMsgCycleTime" BO_ 620 60;
BA_ "GenMsgCycleTimeFast" BO_ 620 0;
BA_ "GenMsgSendType" BO_ 620 0;
BA_ "VFrameFormat" BO_ 620 14;
BA_ "CANFD_BRS" BO_ 620 1;
BA_ "GenMsgCycleTime" BO_ 620 60;
BA_ "GenMsgCycleTimeFast" BO_ 620 0;
BA_ "GenMsgSendType" BO_ 620 0;
BA_ "VFrameFormat" BO_ 620 14;
BA_ "CANFD_BRS" BO_ 620 1;
BA_ "GenMsgCycleTime" BO_ 620 60;
BA_ "GenMsgCycleTimeFast" BO_ 620 0;
BA_ "GenMsgSendType" BO_ 620 0;
BA_ "VFrameFormat" BO_ 620 14;
BA_ "CANFD_BRS" BO_ 620 1;
BA_ "GenMsgCycleTime" BO_ 620 60;
BA_ "GenMsgCycleTimeFast" BO_ 620 0;
BA_ "GenMsgSendType" BO_ 620 0;
BA_ "VFrameFormat" BO_ 620 14;
BA_ "CANFD_BRS" BO_ 620 1;
BA_ "GenMsgCycleTime" BO_ 620 60;
BA_ "GenMsgCycleTimeFast" BO_ 620 0;
BA_ "GenMsgSendType" BO_ 620 0;
BA_ "VFrameFormat" BO_ 620 14;
BA_ "CANFD_BRS" BO_ 620 1;
BA_ "GenMsgCycleTime" BO_ 620 60;
BA_ "GenMsgCycleTimeFast" BO_ 620 0;
BA_ "GenMsgSendType" BO_ 620 0;
BA_ "VFrameFormat" BO_ 620 14;
BA_ "CANFD_BRS" BO_ 620 1;
BA_ "GenMsgCycleTime" BO_ 620 60;
BA_ "GenMsgCycleTimeFast" BO_ 620 0;
BA_ "GenMsgSendType" BO_ 620 0;
BA_ "VFrameFormat" BO_ 620 14;
BA_ "CANFD_BRS" BO_ 620 1;
BA_ "GenMsgCycleTime" BO_ 620 60;
BA_ "GenMsgCycleTimeFast" BO_ 620 0;
BA_ "GenMsgSendType" BO_ 620 0;
BA_ "VFrameFormat" BO_ 620 14;
BA_ "CANFD_BRS" BO_ 620 1;
BA_ "GenMsgCycleTime" BO_ 620 60;
BA_ "GenMsgCycleTimeFast" BO_ 620 0;
BA_ "GenMsgSendType" BO_ 620 0;
BA_ "VFrameFormat" BO_ 620 14;
BA_ "CANFD_BRS" BO_ 620 1;
BA_ "GenMsgCycleTime" BO_ 620 60;
BA_ "GenMsgCycleTimeFast" BO_ 620 0;
BA_ "GenMsgSendType" BO_ 620 0;
BA_ "VFrameFormat" BO_ 620 14;
BA_ "CANFD_BRS" BO_ 620 1;
BA_ "GenMsgCycleTime" BO_ 620 60;
BA_ "GenMsgCycleTimeFast" BO_ 620 0;
BA_ "GenMsgSendType" BO_ 620 0;
BA_ "VFrameFormat" BO_ 620 14;
BA_ "CANFD_BRS" BO_ 620 1;
BA_ "GenMsgCycleTime" BO_ 620 60;
BA_ "GenMsgCycleTimeFast" BO_ 620 0;
BA_ "GenMsgSendType" BO_ 620 0;
BA_ "VFrameFormat" BO_ 620 14;
BA_ "CANFD_BRS" BO_ 620 1;
BA_ "GenMsgCycleTime" BO_ 620 60;
BA_ "GenMsgCycleTimeFast" BO_ 620 0;
BA_ "GenMsgSendType" BO_ 620 0;
BA_ "VFrameFormat" BO_ 620 14;
BA_ "CANFD_BRS" BO_ 620 1;
BA_ "GenMsgCycleTime" BO_ 620 60;
BA_ "GenMsgCycleTimeFast" BO_ 620 0;
BA_ "GenMsgSendType" BO_ 620 0;
BA_ "VFrameFormat" BO_ 620 14;
BA_ "CANFD_BRS" BO_ 620 1;
BA_ "GenMsgCycleTime" BO_ 620 60;
BA_ "GenMsgCycleTimeFast" BO_ 620 0;
BA_ "GenMsgSendType" BO_ 620 0;
BA_ "VFrameFormat" BO_ 620 14;
BA_ "CANFD_BRS" BO_ 620 1;
BA_ "GenMsgCycleTime" BO_ 620 60;
BA_ "GenMsgCycleTimeFast" BO_ 620 0;
BA_ "GenMsgSendType" BO_ 620 0;
BA_ "VFrameFormat" BO_ 620 14;
BA_ "CANFD_BRS" BO_ 620 1;
BA_ "GenMsgCycleTime" BO_ 620 60;
BA_ "GenMsgCycleTimeFast" BO_ 620 0;
BA_ "GenMsgSendType" BO_ 620 0;
BA_ "VFrameFormat" BO_ 620 14;
BA_ "CANFD_BRS" BO_ 620 1;
BA_ "GenMsgCycleTime" BO_ 620 60;
BA_ "GenMsgCycleTimeFast" BO_ 620 0;
BA_ "GenMsgSendType" BO_ 620 0;
BA_ "VFrameFormat" BO_ 620 14;
BA_ "CANFD_BRS" BO_ 620 1;
BA_ "GenMsgCycleTime" BO_ 620 60;
BA_ "GenMsgCycleTimeFast" BO_ 620 0;
BA_ "GenMsgSendType" BO_ 620 0;
BA_ "VFrameFormat" BO_ 620 14;
BA_ "CANFD_BRS" BO_ 620 1;
BA_ "GenMsgCycleTime" BO_ 620 60;
BA_ "GenMsgCycleTimeFast" BO_ 620 0;
BA_ "GenMsgSendType" BO_ 620 0;
BA_ "VFrameFormat" BO_ 620 14;
BA_ "CANFD_BRS" BO_ 620 1;
BA_ "GenMsgCycleTime" BO_ 620 60;
BA_ "GenMsgCycleTimeFast" BO_ 620 0;
BA_ "GenMsgSendType" BO_ 620 0;
BA_ "VFrameFormat" BO_ 620 14;
BA_ "CANFD_BRS" BO_ 620 1;
BA_ "GenMsgCycleTime" BO_ 620 60;
BA_ "GenMsgCycleTimeFast" BO_ 620 0;
BA_ "GenMsgSendType" BO_ 620 0;
BA_ "VFrameFormat" BO_ 620 14;
BA_ "CANFD_BRS" BO_ 620 1;
BA_ "GenMsgCycleTime" BO_ 620 60;
BA_ "GenMsgCycleTimeFast" BO_ 620 0;
BA_ "GenMsgSendType" BO_ 620 0;
BA_ "VFrameFormat" BO_ 620 14;
BA_ "CANFD_BRS" BO_ 620 1;
BA_ "GenMsgCycleTime" BO_ 620 60;
BA_ "GenMsgCycleTimeFast" BO_ 620 0;
BA_ "GenMsgSendType" BO_ 620 0;
BA_ "VFrameFormat" BO_ 620 14;
BA_ "CANFD_BRS" BO_ 620 1;
BA_ "GenMsgCycleTime" BO_ 620 60;
BA_ "GenMsgCycleTimeFast" BO_ 620 0;
BA_ "GenMsgSendType" BO_ 620 0;
BA_ "VFrameFormat" BO_ 620 14;
BA_ "CANFD_BRS" BO_ 620 1;
BA_ "GenMsgCycleTime" BO_ 620 60;
BA_ "GenMsgCycleTimeFast" BO_ 620 0;
BA_ "GenMsgSendType" BO_ 620 0;
BA_ "VFrameFormat" BO_ 620 14;
BA_ "CANFD_BRS" BO_ 620 1;
BA_ "GenMsgCycleTime" BO_ 620 60;
BA_ "GenMsgCycleTimeFast" BO_ 620 0;
BA_ "GenMsgSendType" BO_ 620 0;
BA_ "VFrameFormat" BO_ 620 14;
BA_ "CANFD_BRS" BO_ 620 1;
BA_ "GenMsgCycleTime" BO_ 620 60;
BA_ "GenMsgCycleTimeFast" BO_ 620 0;
BA_ "GenMsgSendType" BO_ 620 0;
BA_ "VFrameFormat" BO_ 620 14;
BA_ "CANFD_BRS" BO_ 620 1;
BA_ "GenMsgCycleTime" BO_ 620 60;
BA_ "GenMsgCycleTimeFast" BO_ 620 0;
BA_ "GenMsgSendType" BO_ 620 0;
BA_ "VFrameFormat" BO_ 620 14;
BA_ "CANFD_BRS" BO_ 620 1;
BA_ "GenMsgCycleTime" BO_ 620 60;
BA_ "GenMsgCycleTimeFast" BO_ 620 0;
BA_ "GenMsgSendType" BO_ 620 0;
BA_ "VFrameFormat" BO_ 620 14;
BA_ "CANFD_BRS" BO_ 620 1;
BA_ "GenMsgCycleTime" BO_ 620 60;
BA_ "GenMsgCycleTimeFast" BO_ 620 0;
BA_ "GenMsgSendType" BO_ 620 0;
BA_ "VFrameFormat" BO_ 620 14;
BA_ "CANFD_BRS" BO_ 620 1;
BA_ "GenMsgCycleTime" BO_ 620 60;
BA_ "GenMsgCycleTimeFast" BO_ 620 0;
BA_ "GenMsgSendType" BO_ 620 0;
BA_ "VFrameFormat" BO_ 620 14;
BA_ "CANFD_BRS" BO_ 620 1;
BA_ "GenMsgCycleTime" BO_ 620 60;
BA_ "GenMsgCycleTimeFast" BO_ 620 0;
BA_ "GenMsgSendType" BO_ 620 0;
BA_ "VFrameFormat" BO_ 620 14;
BA_ "CANFD_BRS" BO_ 620 1;
BA_ "GenMsgCycleTime" BO_ 620 60;
BA_ "GenMsgCycleTimeFast" BO_ 620 0;
BA_ "GenMsgSendType" BO_ 620 0;
BA_ "VFrameFormat" BO_ 620 14;
BA_ "CANFD_BRS" BO_ 620 1;
BA_ "GenMsgCycleTime" BO_ 620 60;
BA_ "GenMsgCycleTimeFast" BO_ 620 0;
BA_ "GenMsgSendType" BO_ 620 0;
BA_ "VFrameFormat" BO_ 620 14;
BA_ "CANFD_BRS" BO_ 620 1;
BA_ "GenMsgCycleTime" BO_ 620 60;
BA_ "GenMsgCycleTimeFast" BO_ 620 0;
BA_ "GenMsgSendType" BO_ 620 0;
BA_ "VFrameFormat" BO_ 620 14;
BA_ "CANFD_BRS" BO_ 620 1;
BA_ "GenMsgCycleTime" BO_ 620 60;
BA_ "GenMsgCycleTimeFast" BO_ 620 0;
BA_ "GenMsgSendType" BO_ 620 0;
BA_ "VFrameFormat" BO_ 620 14;
BA_ "CANFD_BRS" BO_ 620 1;
BA_ "GenMsgCycleTime" BO_ 620 60;
BA_ "GenMsgCycleTimeFast" BO_ 620 0;
BA_ "GenMsgSendType" BO_ 620 0;
BA_ "VFrameFormat" BO_ 620 14;
BA_ "CANFD_BRS" BO_ 620 1;
BA_ "GenMsgCycleTime" BO_ 620 60;
BA_ "GenMsgCycleTimeFast" BO_ 620 0;
BA_ "GenMsgSendType" BO_ 620 0;
BA_ "VFrameFormat" BO_ 620 14;
BA_ "CANFD_BRS" BO_ 620 1;
BA_ "GenMsgCycleTime" BO_ 620 60;
BA_ "GenMsgCycleTimeFast" BO_ 620 0;
BA_ "GenMsgSendType" BO_ 620 0;
BA_ "VFrameFormat" BO_ 620 14;
BA_ "CANFD_BRS" BO_ 620 1;
BA_ "GenMsgCycleTime" BO_ 620 60;
BA_ "GenMsgCycleTimeFast" BO_ 620 0;
BA_ "GenMsgSendType" BO_ 620 0;
BA_ "VFrameFormat" BO_ 620 14;
BA_ "CANFD_BRS" BO_ 620 1;
BA_ "EventCommandSignal" SG_ 696 SBM_5_CRC 0;
BA_ "GatewayedSignals" SG_ 696 SBM_5_CRC 0;
BA_ "GenSigInactiveValue" SG_ 696 SBM_5_CRC 0;
BA_ "GenSigInvalidValue" SG_ 696 SBM_5_CRC 0;
BA_ "GenSigSendType" SG_ 696 SBM_5_CRC 1;
BA_ "GenSigStartValue" SG_ 696 SBM_5_CRC 0;
BA_ "GenSigTimeoutValue" SG_ 696 SBM_5_CRC 0;
BA_ "Remark" SG_ 696 SBM_5_CRC "";
BA_ "EventCommandSignal" SG_ 696 SBM_5_Counter 0;
BA_ "GatewayedSignals" SG_ 696 SBM_5_Counter 0;
BA_ "GenSigInactiveValue" SG_ 696 SBM_5_Counter 0;
BA_ "GenSigInvalidValue" SG_ 696 SBM_5_Counter 0;
BA_ "GenSigSendType" SG_ 696 SBM_5_Counter 1;
BA_ "GenSigStartValue" SG_ 696 SBM_5_Counter 0;
BA_ "GenSigTimeoutValue" SG_ 696 SBM_5_Counter 0;
BA_ "Remark" SG_ 696 SBM_5_Counter "";
BA_ "EventCommandSignal" SG_ 696 KAE_EDK1UnlockBtnPressSt 0;
BA_ "GatewayedSignals" SG_ 696 KAE_EDK1UnlockBtnPressSt 0;
BA_ "GenSigInactiveValue" SG_ 696 KAE_EDK1UnlockBtnPressSt 0;
BA_ "GenSigInvalidValue" SG_ 696 KAE_EDK1UnlockBtnPressSt 0;
BA_ "GenSigSendType" SG_ 696 KAE_EDK1UnlockBtnPressSt 1;
BA_ "GenSigStartValue" SG_ 696 KAE_EDK1UnlockBtnPressSt 0;
BA_ "GenSigTimeoutValue" SG_ 696 KAE_EDK1UnlockBtnPressSt 0;
BA_ "Remark" SG_ 696 KAE_EDK1UnlockBtnPressSt "";
BA_ "EventCommandSignal" SG_ 696 KAE_EDK1LockBtnPressSt 0;
BA_ "GatewayedSignals" SG_ 696 KAE_EDK1LockBtnPressSt 0;
BA_ "GenSigInactiveValue" SG_ 696 KAE_EDK1LockBtnPressSt 0;
BA_ "GenSigInvalidValue" SG_ 696 KAE_EDK1LockBtnPressSt 0;
BA_ "GenSigSendType" SG_ 696 KAE_EDK1LockBtnPressSt 1;
BA_ "GenSigStartValue" SG_ 696 KAE_EDK1LockBtnPressSt 0;
BA_ "GenSigTimeoutValue" SG_ 696 KAE_EDK1LockBtnPressSt 0;
BA_ "Remark" SG_ 696 KAE_EDK1LockBtnPressSt "";
BA_ "EventCommandSignal" SG_ 696 KAE_EDK1RESBtnPressSt 0;
BA_ "GatewayedSignals" SG_ 696 KAE_EDK1RESBtnPressSt 0;
BA_ "GenSigInactiveValue" SG_ 696 KAE_EDK1RESBtnPressSt 0;
BA_ "GenSigInvalidValue" SG_ 696 KAE_EDK1RESBtnPressSt 0;
BA_ "GenSigSendType" SG_ 696 KAE_EDK1RESBtnPressSt 1;
BA_ "GenSigStartValue" SG_ 696 KAE_EDK1RESBtnPressSt 0;
BA_ "GenSigTimeoutValue" SG_ 696 KAE_EDK1RESBtnPressSt 0;
BA_ "Remark" SG_ 696 KAE_EDK1RESBtnPressSt "";
BA_ "EventCommandSignal" SG_ 696 KAE_EDK1PSD_LBtnPressSt 0;
BA_ "GatewayedSignals" SG_ 696 KAE_EDK1PSD_LBtnPressSt 0;
BA_ "GenSigInactiveValue" SG_ 696 KAE_EDK1PSD_LBtnPressSt 0;
BA_ "GenSigInvalidValue" SG_ 696 KAE_EDK1PSD_LBtnPressSt 0;
BA_ "GenSigSendType" SG_ 696 KAE_EDK1PSD_LBtnPressSt 1;
BA_ "GenSigStartValue" SG_ 696 KAE_EDK1PSD_LBtnPressSt 0;
BA_ "GenSigTimeoutValue" SG_ 696 KAE_EDK1PSD_LBtnPressSt 0;
BA_ "Remark" SG_ 696 KAE_EDK1PSD_LBtnPressSt "";
BA_ "EventCommandSignal" SG_ 696 KAE_EDK1PSD_RBtnPressSt 0;
BA_ "GatewayedSignals" SG_ 696 KAE_EDK1PSD_RBtnPressSt 0;
BA_ "GenSigInactiveValue" SG_ 696 KAE_EDK1PSD_RBtnPressSt 0;
BA_ "GenSigInvalidValue" SG_ 696 KAE_EDK1PSD_RBtnPressSt 0;
BA_ "GenSigSendType" SG_ 696 KAE_EDK1PSD_RBtnPressSt 1;
BA_ "GenSigStartValue" SG_ 696 KAE_EDK1PSD_RBtnPressSt 0;
BA_ "GenSigTimeoutValue" SG_ 696 KAE_EDK1PSD_RBtnPressSt 0;
BA_ "Remark" SG_ 696 KAE_EDK1PSD_RBtnPressSt "";
BA_ "EventCommandSignal" SG_ 696 KAE_EDK1TrunkBtnPressSt 0;
BA_ "GatewayedSignals" SG_ 696 KAE_EDK1TrunkBtnPressSt 0;
BA_ "GenSigInactiveValue" SG_ 696 KAE_EDK1TrunkBtnPressSt 0;
BA_ "GenSigInvalidValue" SG_ 696 KAE_EDK1TrunkBtnPressSt 0;
BA_ "GenSigSendType" SG_ 696 KAE_EDK1TrunkBtnPressSt 1;
BA_ "GenSigStartValue" SG_ 696 KAE_EDK1TrunkBtnPressSt 0;
BA_ "GenSigTimeoutValue" SG_ 696 KAE_EDK1TrunkBtnPressSt 0;
BA_ "Remark" SG_ 696 KAE_EDK1TrunkBtnPressSt "";
BA_ "EventCommandSignal" SG_ 696 KAE_EDK1PanicBtnPressSt 0;
BA_ "GatewayedSignals" SG_ 696 KAE_EDK1PanicBtnPressSt 0;
BA_ "GenSigInactiveValue" SG_ 696 KAE_EDK1PanicBtnPressSt 0;
BA_ "GenSigInvalidValue" SG_ 696 KAE_EDK1PanicBtnPressSt 0;
BA_ "GenSigSendType" SG_ 696 KAE_EDK1PanicBtnPressSt 1;
BA_ "GenSigStartValue" SG_ 696 KAE_EDK1PanicBtnPressSt 0;
BA_ "GenSigTimeoutValue" SG_ 696 KAE_EDK1PanicBtnPressSt 0;
BA_ "Remark" SG_ 696 KAE_EDK1PanicBtnPressSt "";
BA_ "EventCommandSignal" SG_ 696 KAE_EDK1User_definedBtnPressSt 0;
BA_ "GatewayedSignals" SG_ 696 KAE_EDK1User_definedBtnPressSt 0;
BA_ "GenSigInactiveValue" SG_ 696 KAE_EDK1User_definedBtnPressSt 0;
BA_ "GenSigInvalidValue" SG_ 696 KAE_EDK1User_definedBtnPressSt 0;
BA_ "GenSigSendType" SG_ 696 KAE_EDK1User_definedBtnPressSt 1;
BA_ "GenSigStartValue" SG_ 696 KAE_EDK1User_definedBtnPressSt 0;
BA_ "GenSigTimeoutValue" SG_ 696 KAE_EDK1User_definedBtnPressSt 0;
BA_ "Remark" SG_ 696 KAE_EDK1User_definedBtnPressSt "";
BA_ "EventCommandSignal" SG_ 696 KAE_EDK2UnlockBtnPressSt 0;
BA_ "GatewayedSignals" SG_ 696 KAE_EDK2UnlockBtnPressSt 0;
BA_ "GenSigInactiveValue" SG_ 696 KAE_EDK2UnlockBtnPressSt 0;
BA_ "GenSigInvalidValue" SG_ 696 KAE_EDK2UnlockBtnPressSt 0;
BA_ "GenSigSendType" SG_ 696 KAE_EDK2UnlockBtnPressSt 1;
BA_ "GenSigStartValue" SG_ 696 KAE_EDK2UnlockBtnPressSt 0;
BA_ "GenSigTimeoutValue" SG_ 696 KAE_EDK2UnlockBtnPressSt 0;
BA_ "Remark" SG_ 696 KAE_EDK2UnlockBtnPressSt "";
BA_ "EventCommandSignal" SG_ 696 KAE_EDK2LockBtnPressSt 0;
BA_ "GatewayedSignals" SG_ 696 KAE_EDK2LockBtnPressSt 0;
BA_ "GenSigInactiveValue" SG_ 696 KAE_EDK2LockBtnPressSt 0;
BA_ "GenSigInvalidValue" SG_ 696 KAE_EDK2LockBtnPressSt 0;
BA_ "GenSigSendType" SG_ 696 KAE_EDK2LockBtnPressSt 1;
BA_ "GenSigStartValue" SG_ 696 KAE_EDK2LockBtnPressSt 0;
BA_ "GenSigTimeoutValue" SG_ 696 KAE_EDK2LockBtnPressSt 0;
BA_ "Remark" SG_ 696 KAE_EDK2LockBtnPressSt "";
BA_ "EventCommandSignal" SG_ 696 KAE_EDK2RESBtnPressSt 0;
BA_ "GatewayedSignals" SG_ 696 KAE_EDK2RESBtnPressSt 0;
BA_ "GenSigInactiveValue" SG_ 696 KAE_EDK2RESBtnPressSt 0;
BA_ "GenSigInvalidValue" SG_ 696 KAE_EDK2RESBtnPressSt 0;
BA_ "GenSigSendType" SG_ 696 KAE_EDK2RESBtnPressSt 1;
BA_ "GenSigStartValue" SG_ 696 KAE_EDK2RESBtnPressSt 0;
BA_ "GenSigTimeoutValue" SG_ 696 KAE_EDK2RESBtnPressSt 0;
BA_ "Remark" SG_ 696 KAE_EDK2RESBtnPressSt "";
BA_ "EventCommandSignal" SG_ 696 KAE_EDK2PSD_LBtnPressSt 0;
BA_ "GatewayedSignals" SG_ 696 KAE_EDK2PSD_LBtnPressSt 0;
BA_ "GenSigInactiveValue" SG_ 696 KAE_EDK2PSD_LBtnPressSt 0;
BA_ "GenSigInvalidValue" SG_ 696 KAE_EDK2PSD_LBtnPressSt 0;
BA_ "GenSigSendType" SG_ 696 KAE_EDK2PSD_LBtnPressSt 1;
BA_ "GenSigStartValue" SG_ 696 KAE_EDK2PSD_LBtnPressSt 0;
BA_ "GenSigTimeoutValue" SG_ 696 KAE_EDK2PSD_LBtnPressSt 0;
BA_ "Remark" SG_ 696 KAE_EDK2PSD_LBtnPressSt "";
BA_ "EventCommandSignal" SG_ 696 KAE_EDK2PSD_RBtnPressSt 0;
BA_ "GatewayedSignals" SG_ 696 KAE_EDK2PSD_RBtnPressSt 0;
BA_ "GenSigInactiveValue" SG_ 696 KAE_EDK2PSD_RBtnPressSt 0;
BA_ "GenSigInvalidValue" SG_ 696 KAE_EDK2PSD_RBtnPressSt 0;
BA_ "GenSigSendType" SG_ 696 KAE_EDK2PSD_RBtnPressSt 1;
BA_ "GenSigStartValue" SG_ 696 KAE_EDK2PSD_RBtnPressSt 0;
BA_ "GenSigTimeoutValue" SG_ 696 KAE_EDK2PSD_RBtnPressSt 0;
BA_ "Remark" SG_ 696 KAE_EDK2PSD_RBtnPressSt "";
BA_ "EventCommandSignal" SG_ 696 KAE_EDK2TrunkBtnPressSt 0;
BA_ "GatewayedSignals" SG_ 696 KAE_EDK2TrunkBtnPressSt 0;
BA_ "GenSigInactiveValue" SG_ 696 KAE_EDK2TrunkBtnPressSt 0;
BA_ "GenSigInvalidValue" SG_ 696 KAE_EDK2TrunkBtnPressSt 0;
BA_ "GenSigSendType" SG_ 696 KAE_EDK2TrunkBtnPressSt 1;
BA_ "GenSigStartValue" SG_ 696 KAE_EDK2TrunkBtnPressSt 0;
BA_ "GenSigTimeoutValue" SG_ 696 KAE_EDK2TrunkBtnPressSt 0;
BA_ "Remark" SG_ 696 KAE_EDK2TrunkBtnPressSt "";
BA_ "EventCommandSignal" SG_ 696 KAE_EDK2PanicBtnPressSt 0;
BA_ "GatewayedSignals" SG_ 696 KAE_EDK2PanicBtnPressSt 0;
BA_ "GenSigInactiveValue" SG_ 696 KAE_EDK2PanicBtnPressSt 0;
BA_ "GenSigInvalidValue" SG_ 696 KAE_EDK2PanicBtnPressSt 0;
BA_ "GenSigSendType" SG_ 696 KAE_EDK2PanicBtnPressSt 1;
BA_ "GenSigStartValue" SG_ 696 KAE_EDK2PanicBtnPressSt 0;
BA_ "GenSigTimeoutValue" SG_ 696 KAE_EDK2PanicBtnPressSt 0;
BA_ "Remark" SG_ 696 KAE_EDK2PanicBtnPressSt "";
BA_ "EventCommandSignal" SG_ 696 KAE_EDK2User_definedBtnPressSt 0;
BA_ "GatewayedSignals" SG_ 696 KAE_EDK2User_definedBtnPressSt 0;
BA_ "GenSigInactiveValue" SG_ 696 KAE_EDK2User_definedBtnPressSt 0;
BA_ "GenSigInvalidValue" SG_ 696 KAE_EDK2User_definedBtnPressSt 0;
BA_ "GenSigSendType" SG_ 696 KAE_EDK2User_definedBtnPressSt 1;
BA_ "GenSigStartValue" SG_ 696 KAE_EDK2User_definedBtnPressSt 0;
BA_ "GenSigTimeoutValue" SG_ 696 KAE_EDK2User_definedBtnPressSt 0;
BA_ "Remark" SG_ 696 KAE_EDK2User_definedBtnPressSt "";
BA_ "EventCommandSignal" SG_ 696 KAE_EDK3UnlockBtnPressSt 0;
BA_ "GatewayedSignals" SG_ 696 KAE_EDK3UnlockBtnPressSt 0;
BA_ "GenSigInactiveValue" SG_ 696 KAE_EDK3UnlockBtnPressSt 0;
BA_ "GenSigInvalidValue" SG_ 696 KAE_EDK3UnlockBtnPressSt 0;
BA_ "GenSigSendType" SG_ 696 KAE_EDK3UnlockBtnPressSt 1;
BA_ "GenSigStartValue" SG_ 696 KAE_EDK3UnlockBtnPressSt 0;
BA_ "GenSigTimeoutValue" SG_ 696 KAE_EDK3UnlockBtnPressSt 0;
BA_ "Remark" SG_ 696 KAE_EDK3UnlockBtnPressSt "";
BA_ "EventCommandSignal" SG_ 696 KAE_EDK3LockBtnPressSt 0;
BA_ "GatewayedSignals" SG_ 696 KAE_EDK3LockBtnPressSt 0;
BA_ "GenSigInactiveValue" SG_ 696 KAE_EDK3LockBtnPressSt 0;
BA_ "GenSigInvalidValue" SG_ 696 KAE_EDK3LockBtnPressSt 0;
BA_ "GenSigSendType" SG_ 696 KAE_EDK3LockBtnPressSt 1;
BA_ "GenSigStartValue" SG_ 696 KAE_EDK3LockBtnPressSt 0;
BA_ "GenSigTimeoutValue" SG_ 696 KAE_EDK3LockBtnPressSt 0;
BA_ "Remark" SG_ 696 KAE_EDK3LockBtnPressSt "";
BA_ "EventCommandSignal" SG_ 696 KAE_EDK3RESBtnPressSt 0;
BA_ "GatewayedSignals" SG_ 696 KAE_EDK3RESBtnPressSt 0;
BA_ "GenSigInactiveValue" SG_ 696 KAE_EDK3RESBtnPressSt 0;
BA_ "GenSigInvalidValue" SG_ 696 KAE_EDK3RESBtnPressSt 0;
BA_ "GenSigSendType" SG_ 696 KAE_EDK3RESBtnPressSt 1;
BA_ "GenSigStartValue" SG_ 696 KAE_EDK3RESBtnPressSt 0;
BA_ "GenSigTimeoutValue" SG_ 696 KAE_EDK3RESBtnPressSt 0;
BA_ "Remark" SG_ 696 KAE_EDK3RESBtnPressSt "";
BA_ "EventCommandSignal" SG_ 696 KAE_EDK3PSD_LBtnPressSt 0;
BA_ "GatewayedSignals" SG_ 696 KAE_EDK3PSD_LBtnPressSt 0;
BA_ "GenSigInactiveValue" SG_ 696 KAE_EDK3PSD_LBtnPressSt 0;
BA_ "GenSigInvalidValue" SG_ 696 KAE_EDK3PSD_LBtnPressSt 0;
BA_ "GenSigSendType" SG_ 696 KAE_EDK3PSD_LBtnPressSt 1;
BA_ "GenSigStartValue" SG_ 696 KAE_EDK3PSD_LBtnPressSt 0;
BA_ "GenSigTimeoutValue" SG_ 696 KAE_EDK3PSD_LBtnPressSt 0;
BA_ "Remark" SG_ 696 KAE_EDK3PSD_LBtnPressSt "";
BA_ "EventCommandSignal" SG_ 696 KAE_EDK3PSD_RBtnPressSt 0;
BA_ "GatewayedSignals" SG_ 696 KAE_EDK3PSD_RBtnPressSt 0;
BA_ "GenSigInactiveValue" SG_ 696 KAE_EDK3PSD_RBtnPressSt 0;
BA_ "GenSigInvalidValue" SG_ 696 KAE_EDK3PSD_RBtnPressSt 0;
BA_ "GenSigSendType" SG_ 696 KAE_EDK3PSD_RBtnPressSt 1;
BA_ "GenSigStartValue" SG_ 696 KAE_EDK3PSD_RBtnPressSt 0;
BA_ "GenSigTimeoutValue" SG_ 696 KAE_EDK3PSD_RBtnPressSt 0;
BA_ "Remark" SG_ 696 KAE_EDK3PSD_RBtnPressSt "";
BA_ "EventCommandSignal" SG_ 696 KAE_EDK3TrunkBtnPressSt 0;
BA_ "GatewayedSignals" SG_ 696 KAE_EDK3TrunkBtnPressSt 0;
BA_ "GenSigInactiveValue" SG_ 696 KAE_EDK3TrunkBtnPressSt 0;
BA_ "GenSigInvalidValue" SG_ 696 KAE_EDK3TrunkBtnPressSt 0;
BA_ "GenSigSendType" SG_ 696 KAE_EDK3TrunkBtnPressSt 1;
BA_ "GenSigStartValue" SG_ 696 KAE_EDK3TrunkBtnPressSt 0;
BA_ "GenSigTimeoutValue" SG_ 696 KAE_EDK3TrunkBtnPressSt 0;
BA_ "Remark" SG_ 696 KAE_EDK3TrunkBtnPressSt "";
BA_ "EventCommandSignal" SG_ 696 KAE_EDK3PanicBtnPressSt 0;
BA_ "GatewayedSignals" SG_ 696 KAE_EDK3PanicBtnPressSt 0;
BA_ "GenSigInactiveValue" SG_ 696 KAE_EDK3PanicBtnPressSt 0;
BA_ "GenSigInvalidValue" SG_ 696 KAE_EDK3PanicBtnPressSt 0;
BA_ "GenSigSendType" SG_ 696 KAE_EDK3PanicBtnPressSt 1;
BA_ "GenSigStartValue" SG_ 696 KAE_EDK3PanicBtnPressSt 0;
BA_ "GenSigTimeoutValue" SG_ 696 KAE_EDK3PanicBtnPressSt 0;
BA_ "Remark" SG_ 696 KAE_EDK3PanicBtnPressSt "";
BA_ "EventCommandSignal" SG_ 696 KAE_EDK3User_definedBtnPressSt 0;
BA_ "GatewayedSignals" SG_ 696 KAE_EDK3User_definedBtnPressSt 0;
BA_ "GenSigInactiveValue" SG_ 696 KAE_EDK3User_definedBtnPressSt 0;
BA_ "GenSigInvalidValue" SG_ 696 KAE_EDK3User_definedBtnPressSt 0;
BA_ "GenSigSendType" SG_ 696 KAE_EDK3User_definedBtnPressSt 1;
BA_ "GenSigStartValue" SG_ 696 KAE_EDK3User_definedBtnPressSt 0;
BA_ "GenSigTimeoutValue" SG_ 696 KAE_EDK3User_definedBtnPressSt 0;
BA_ "Remark" SG_ 696 KAE_EDK3User_definedBtnPressSt "";
BA_ "EventCommandSignal" SG_ 696 KAE_RPADirectionSel 0;
BA_ "GatewayedSignals" SG_ 696 KAE_RPADirectionSel 0;
BA_ "GenSigInactiveValue" SG_ 696 KAE_RPADirectionSel 0;
BA_ "GenSigInvalidValue" SG_ 696 KAE_RPADirectionSel 0;
BA_ "GenSigSendType" SG_ 696 KAE_RPADirectionSel 1;
BA_ "GenSigStartValue" SG_ 696 KAE_RPADirectionSel 0;
BA_ "GenSigTimeoutValue" SG_ 696 KAE_RPADirectionSel 0;
BA_ "Remark" SG_ 696 KAE_RPADirectionSel "";
BA_ "EventCommandSignal" SG_ 696 KAE_RPAmode 0;
BA_ "GatewayedSignals" SG_ 696 KAE_RPAmode 0;
BA_ "GenSigInactiveValue" SG_ 696 KAE_RPAmode 0;
BA_ "GenSigInvalidValue" SG_ 696 KAE_RPAmode 0;
BA_ "GenSigSendType" SG_ 696 KAE_RPAmode 1;
BA_ "GenSigStartValue" SG_ 696 KAE_RPAmode 0;
BA_ "GenSigTimeoutValue" SG_ 696 KAE_RPAmode 0;
BA_ "Remark" SG_ 696 KAE_RPAmode "";
BA_ "EventCommandSignal" SG_ 696 KAE_RPADeviceSt 0;
BA_ "GatewayedSignals" SG_ 696 KAE_RPADeviceSt 0;
BA_ "GenSigInactiveValue" SG_ 696 KAE_RPADeviceSt 0;
BA_ "GenSigInvalidValue" SG_ 696 KAE_RPADeviceSt 0;
BA_ "GenSigSendType" SG_ 696 KAE_RPADeviceSt 1;
BA_ "GenSigStartValue" SG_ 696 KAE_RPADeviceSt 0;
BA_ "GenSigTimeoutValue" SG_ 696 KAE_RPADeviceSt 0;
BA_ "Remark" SG_ 696 KAE_RPADeviceSt "";
BA_ "EventCommandSignal" SG_ 696 KAE_PhoneBatt 0;
BA_ "GatewayedSignals" SG_ 696 KAE_PhoneBatt 0;
BA_ "GenSigInactiveValue" SG_ 696 KAE_PhoneBatt 0;
BA_ "GenSigInvalidValue" SG_ 696 KAE_PhoneBatt 0;
BA_ "GenSigSendType" SG_ 696 KAE_PhoneBatt 1;
BA_ "GenSigStartValue" SG_ 696 KAE_PhoneBatt 0;
BA_ "GenSigTimeoutValue" SG_ 696 KAE_PhoneBatt 0;
BA_ "Remark" SG_ 696 KAE_PhoneBatt "";
BA_ "EventCommandSignal" SG_ 696 KAE_RPACheckReq 0;
BA_ "GatewayedSignals" SG_ 696 KAE_RPACheckReq 0;
BA_ "GenSigInactiveValue" SG_ 696 KAE_RPACheckReq 0;
BA_ "GenSigInvalidValue" SG_ 696 KAE_RPACheckReq 0;
BA_ "GenSigSendType" SG_ 696 KAE_RPACheckReq 1;
BA_ "GenSigStartValue" SG_ 696 KAE_RPACheckReq 0;
BA_ "GenSigTimeoutValue" SG_ 696 KAE_RPACheckReq 0;
BA_ "Remark" SG_ 696 KAE_RPACheckReq "";
BA_ "EventCommandSignal" SG_ 696 KAE_RPAKeyPstSt 0;
BA_ "GatewayedSignals" SG_ 696 KAE_RPAKeyPstSt 0;
BA_ "GenSigInactiveValue" SG_ 696 KAE_RPAKeyPstSt 0;
BA_ "GenSigInvalidValue" SG_ 696 KAE_RPAKeyPstSt 0;
BA_ "GenSigSendType" SG_ 696 KAE_RPAKeyPstSt 1;
BA_ "GenSigStartValue" SG_ 696 KAE_RPAKeyPstSt 0;
BA_ "GenSigTimeoutValue" SG_ 696 KAE_RPAKeyPstSt 0;
BA_ "Remark" SG_ 696 KAE_RPAKeyPstSt "";
BA_ "EventCommandSignal" SG_ 696 KAE_RPADeviceFailReason 0;
BA_ "GatewayedSignals" SG_ 696 KAE_RPADeviceFailReason 0;
BA_ "GenSigInactiveValue" SG_ 696 KAE_RPADeviceFailReason 0;
BA_ "GenSigInvalidValue" SG_ 696 KAE_RPADeviceFailReason 0;
BA_ "GenSigSendType" SG_ 696 KAE_RPADeviceFailReason 1;
BA_ "GenSigStartValue" SG_ 696 KAE_RPADeviceFailReason 0;
BA_ "GenSigTimeoutValue" SG_ 696 KAE_RPADeviceFailReason 0;
BA_ "Remark" SG_ 696 KAE_RPADeviceFailReason "";
BA_ "EventCommandSignal" SG_ 696 KAE_RPABtnSt 0;
BA_ "GatewayedSignals" SG_ 696 KAE_RPABtnSt 0;
BA_ "GenSigInactiveValue" SG_ 696 KAE_RPABtnSt 0;
BA_ "GenSigInvalidValue" SG_ 696 KAE_RPABtnSt 0;
BA_ "GenSigSendType" SG_ 696 KAE_RPABtnSt 1;
BA_ "GenSigStartValue" SG_ 696 KAE_RPABtnSt 0;
BA_ "GenSigTimeoutValue" SG_ 696 KAE_RPABtnSt 0;
BA_ "Remark" SG_ 696 KAE_RPABtnSt "";
BA_ "EventCommandSignal" SG_ 696 KAE_ForRPAFailReason 0;
BA_ "GatewayedSignals" SG_ 696 KAE_ForRPAFailReason 0;
BA_ "GenSigInactiveValue" SG_ 696 KAE_ForRPAFailReason 0;
BA_ "GenSigInvalidValue" SG_ 696 KAE_ForRPAFailReason 0;
BA_ "GenSigSendType" SG_ 696 KAE_ForRPAFailReason 1;
BA_ "GenSigStartValue" SG_ 696 KAE_ForRPAFailReason 0;
BA_ "GenSigTimeoutValue" SG_ 696 KAE_ForRPAFailReason 0;
BA_ "Remark" SG_ 696 KAE_ForRPAFailReason "";
BA_ "EventCommandSignal" SG_ 696 KAE_RPABtnStVD 0;
BA_ "GatewayedSignals" SG_ 696 KAE_RPABtnStVD 0;
BA_ "GenSigInactiveValue" SG_ 696 KAE_RPABtnStVD 0;
BA_ "GenSigInvalidValue" SG_ 696 KAE_RPABtnStVD 0;
BA_ "GenSigSendType" SG_ 696 KAE_RPABtnStVD 1;
BA_ "GenSigStartValue" SG_ 696 KAE_RPABtnStVD 0;
BA_ "GenSigTimeoutValue" SG_ 696 KAE_RPABtnStVD 0;
BA_ "Remark" SG_ 696 KAE_RPABtnStVD "";
BA_ "EventCommandSignal" SG_ 696 KAE_RPACancelBtnSt 0;
BA_ "GatewayedSignals" SG_ 696 KAE_RPACancelBtnSt 0;
BA_ "GenSigInactiveValue" SG_ 696 KAE_RPACancelBtnSt 0;
BA_ "GenSigInvalidValue" SG_ 696 KAE_RPACancelBtnSt 0;
BA_ "GenSigSendType" SG_ 696 KAE_RPACancelBtnSt 1;
BA_ "GenSigStartValue" SG_ 696 KAE_RPACancelBtnSt 0;
BA_ "GenSigTimeoutValue" SG_ 696 KAE_RPACancelBtnSt 0;
BA_ "Remark" SG_ 696 KAE_RPACancelBtnSt "";
BA_ "EventCommandSignal" SG_ 696 KAE_RPACancelBtnStVD 0;
BA_ "GatewayedSignals" SG_ 696 KAE_RPACancelBtnStVD 0;
BA_ "GenSigInactiveValue" SG_ 696 KAE_RPACancelBtnStVD 0;
BA_ "GenSigInvalidValue" SG_ 696 KAE_RPACancelBtnStVD 0;
BA_ "GenSigSendType" SG_ 696 KAE_RPACancelBtnStVD 1;
BA_ "GenSigStartValue" SG_ 696 KAE_RPACancelBtnStVD 0;
BA_ "GenSigTimeoutValue" SG_ 696 KAE_RPACancelBtnStVD 0;
BA_ "Remark" SG_ 696 KAE_RPACancelBtnStVD "";
BA_ "EventCommandSignal" SG_ 696 KAE_ComSDKUBouncesSt 0;
BA_ "GatewayedSignals" SG_ 696 KAE_ComSDKUBouncesSt 0;
BA_ "GenSigInactiveValue" SG_ 696 KAE_ComSDKUBouncesSt 0;
BA_ "GenSigInvalidValue" SG_ 696 KAE_ComSDKUBouncesSt 0;
BA_ "GenSigSendType" SG_ 696 KAE_ComSDKUBouncesSt 1;
BA_ "GenSigStartValue" SG_ 696 KAE_ComSDKUBouncesSt 0;
BA_ "GenSigTimeoutValue" SG_ 696 KAE_ComSDKUBouncesSt 0;
BA_ "Remark" SG_ 696 KAE_ComSDKUBouncesSt "";
BA_ "EventCommandSignal" SG_ 696 KAE_HAVPCancelParking 0;
BA_ "GatewayedSignals" SG_ 696 KAE_HAVPCancelParking 0;
BA_ "GenSigInactiveValue" SG_ 696 KAE_HAVPCancelParking 0;
BA_ "GenSigInvalidValue" SG_ 696 KAE_HAVPCancelParking 0;
BA_ "GenSigSendType" SG_ 696 KAE_HAVPCancelParking 1;
BA_ "GenSigStartValue" SG_ 696 KAE_HAVPCancelParking 0;
BA_ "GenSigTimeoutValue" SG_ 696 KAE_HAVPCancelParking 0;
BA_ "Remark" SG_ 696 KAE_HAVPCancelParking "";
BA_ "EventCommandSignal" SG_ 696 KAE_HAVPDisclaimerAgree 0;
BA_ "GatewayedSignals" SG_ 696 KAE_HAVPDisclaimerAgree 0;
BA_ "GenSigInactiveValue" SG_ 696 KAE_HAVPDisclaimerAgree 0;
BA_ "GenSigInvalidValue" SG_ 696 KAE_HAVPDisclaimerAgree 0;
BA_ "GenSigSendType" SG_ 696 KAE_HAVPDisclaimerAgree 1;
BA_ "GenSigStartValue" SG_ 696 KAE_HAVPDisclaimerAgree 0;
BA_ "GenSigTimeoutValue" SG_ 696 KAE_HAVPDisclaimerAgree 0;
BA_ "Remark" SG_ 696 KAE_HAVPDisclaimerAgree "";
BA_ "EventCommandSignal" SG_ 696 KAE_HAVPPathSelect 0;
BA_ "GatewayedSignals" SG_ 696 KAE_HAVPPathSelect 0;
BA_ "GenSigInactiveValue" SG_ 696 KAE_HAVPPathSelect 0;
BA_ "GenSigInvalidValue" SG_ 696 KAE_HAVPPathSelect 0;
BA_ "GenSigSendType" SG_ 696 KAE_HAVPPathSelect 1;
BA_ "GenSigStartValue" SG_ 696 KAE_HAVPPathSelect 0;
BA_ "GenSigTimeoutValue" SG_ 696 KAE_HAVPPathSelect 0;
BA_ "Remark" SG_ 696 KAE_HAVPPathSelect "";
BA_ "EventCommandSignal" SG_ 696 KAE_RPAResponse 0;
BA_ "GatewayedSignals" SG_ 696 KAE_RPAResponse 0;
BA_ "GenSigInactiveValue" SG_ 696 KAE_RPAResponse 0;
BA_ "GenSigInvalidValue" SG_ 696 KAE_RPAResponse 0;
BA_ "GenSigSendType" SG_ 696 KAE_RPAResponse 1;
BA_ "GenSigStartValue" SG_ 696 KAE_RPAResponse 0;
BA_ "GenSigTimeoutValue" SG_ 696 KAE_RPAResponse 0;
BA_ "Remark" SG_ 696 KAE_RPAResponse "";
BA_ "EventCommandSignal" SG_ 696 KAE_HAVPUWBZone 0;
BA_ "GatewayedSignals" SG_ 696 KAE_HAVPUWBZone 0;
BA_ "GenSigInactiveValue" SG_ 696 KAE_HAVPUWBZone 0;
BA_ "GenSigInvalidValue" SG_ 696 KAE_HAVPUWBZone 0;
BA_ "GenSigSendType" SG_ 696 KAE_HAVPUWBZone 1;
BA_ "GenSigStartValue" SG_ 696 KAE_HAVPUWBZone 0;
BA_ "GenSigTimeoutValue" SG_ 696 KAE_HAVPUWBZone 0;
BA_ "Remark" SG_ 696 KAE_HAVPUWBZone "";
BA_ "EventCommandSignal" SG_ 696 KAE_HAVPUWBXPosition 0;
BA_ "GatewayedSignals" SG_ 696 KAE_HAVPUWBXPosition 0;
BA_ "GenSigInactiveValue" SG_ 696 KAE_HAVPUWBXPosition 0;
BA_ "GenSigInvalidValue" SG_ 696 KAE_HAVPUWBXPosition 0;
BA_ "GenSigSendType" SG_ 696 KAE_HAVPUWBXPosition 1;
BA_ "GenSigStartValue" SG_ 696 KAE_HAVPUWBXPosition 0;
BA_ "GenSigTimeoutValue" SG_ 696 KAE_HAVPUWBXPosition 0;
BA_ "Remark" SG_ 696 KAE_HAVPUWBXPosition "";
BA_ "EventCommandSignal" SG_ 696 KAE_HAVPUWBYPosition 0;
BA_ "GatewayedSignals" SG_ 696 KAE_HAVPUWBYPosition 0;
BA_ "GenSigInactiveValue" SG_ 696 KAE_HAVPUWBYPosition 0;
BA_ "GenSigInvalidValue" SG_ 696 KAE_HAVPUWBYPosition 0;
BA_ "GenSigSendType" SG_ 696 KAE_HAVPUWBYPosition 1;
BA_ "GenSigStartValue" SG_ 696 KAE_HAVPUWBYPosition 0;
BA_ "GenSigTimeoutValue" SG_ 696 KAE_HAVPUWBYPosition 0;
BA_ "Remark" SG_ 696 KAE_HAVPUWBYPosition "";
BA_ "EventCommandSignal" SG_ 696 KAE_UnlockDoorReq 0;
BA_ "GatewayedSignals" SG_ 696 KAE_UnlockDoorReq 0;
BA_ "GenSigInactiveValue" SG_ 696 KAE_UnlockDoorReq 0;
BA_ "GenSigInvalidValue" SG_ 696 KAE_UnlockDoorReq 0;
BA_ "GenSigSendType" SG_ 696 KAE_UnlockDoorReq 1;
BA_ "GenSigStartValue" SG_ 696 KAE_UnlockDoorReq 0;
BA_ "GenSigTimeoutValue" SG_ 696 KAE_UnlockDoorReq 0;
BA_ "Remark" SG_ 696 KAE_UnlockDoorReq "";
BA_ "EventCommandSignal" SG_ 696 KAE_UnlockDoorReqVD 0;
BA_ "GatewayedSignals" SG_ 696 KAE_UnlockDoorReqVD 0;
BA_ "GenSigInactiveValue" SG_ 696 KAE_UnlockDoorReqVD 0;
BA_ "GenSigInvalidValue" SG_ 696 KAE_UnlockDoorReqVD 0;
BA_ "GenSigSendType" SG_ 696 KAE_UnlockDoorReqVD 1;
BA_ "GenSigStartValue" SG_ 696 KAE_UnlockDoorReqVD 0;
BA_ "GenSigTimeoutValue" SG_ 696 KAE_UnlockDoorReqVD 0;
BA_ "Remark" SG_ 696 KAE_UnlockDoorReqVD "";
BA_ "EventCommandSignal" SG_ 696 KAE_LockDoorReq 0;
BA_ "GatewayedSignals" SG_ 696 KAE_LockDoorReq 0;
BA_ "GenSigInactiveValue" SG_ 696 KAE_LockDoorReq 0;
BA_ "GenSigInvalidValue" SG_ 696 KAE_LockDoorReq 0;
BA_ "GenSigSendType" SG_ 696 KAE_LockDoorReq 1;
BA_ "GenSigStartValue" SG_ 696 KAE_LockDoorReq 0;
BA_ "GenSigTimeoutValue" SG_ 696 KAE_LockDoorReq 0;
BA_ "Remark" SG_ 696 KAE_LockDoorReq "";
BA_ "EventCommandSignal" SG_ 696 KAE_LockDoorReqVD 0;
BA_ "GatewayedSignals" SG_ 696 KAE_LockDoorReqVD 0;
BA_ "GenSigInactiveValue" SG_ 696 KAE_LockDoorReqVD 0;
BA_ "GenSigInvalidValue" SG_ 696 KAE_LockDoorReqVD 0;
BA_ "GenSigSendType" SG_ 696 KAE_LockDoorReqVD 1;
BA_ "GenSigStartValue" SG_ 696 KAE_LockDoorReqVD 0;
BA_ "GenSigTimeoutValue" SG_ 696 KAE_LockDoorReqVD 0;
BA_ "Remark" SG_ 696 KAE_LockDoorReqVD "";
BA_ "EventCommandSignal" SG_ 696 KAE_WindowsCloseReq 0;
BA_ "GatewayedSignals" SG_ 696 KAE_WindowsCloseReq 0;
BA_ "GenSigInactiveValue" SG_ 696 KAE_WindowsCloseReq 0;
BA_ "GenSigInvalidValue" SG_ 696 KAE_WindowsCloseReq 0;
BA_ "GenSigSendType" SG_ 696 KAE_WindowsCloseReq 1;
BA_ "GenSigStartValue" SG_ 696 KAE_WindowsCloseReq 0;
BA_ "GenSigTimeoutValue" SG_ 696 KAE_WindowsCloseReq 0;
BA_ "Remark" SG_ 696 KAE_WindowsCloseReq "";
BA_ "EventCommandSignal" SG_ 696 KAE_WindowsCloseReqVD 0;
BA_ "GatewayedSignals" SG_ 696 KAE_WindowsCloseReqVD 0;
BA_ "GenSigInactiveValue" SG_ 696 KAE_WindowsCloseReqVD 0;
BA_ "GenSigInvalidValue" SG_ 696 KAE_WindowsCloseReqVD 0;
BA_ "GenSigSendType" SG_ 696 KAE_WindowsCloseReqVD 1;
BA_ "GenSigStartValue" SG_ 696 KAE_WindowsCloseReqVD 0;
BA_ "GenSigTimeoutValue" SG_ 696 KAE_WindowsCloseReqVD 0;
BA_ "Remark" SG_ 696 KAE_WindowsCloseReqVD "";
BA_ "EventCommandSignal" SG_ 696 KAE_WindowsOpenReq 0;
BA_ "GatewayedSignals" SG_ 696 KAE_WindowsOpenReq 0;
BA_ "GenSigInactiveValue" SG_ 696 KAE_WindowsOpenReq 0;
BA_ "GenSigInvalidValue" SG_ 696 KAE_WindowsOpenReq 0;
BA_ "GenSigSendType" SG_ 696 KAE_WindowsOpenReq 1;
BA_ "GenSigStartValue" SG_ 696 KAE_WindowsOpenReq 0;
BA_ "GenSigTimeoutValue" SG_ 696 KAE_WindowsOpenReq 0;
BA_ "Remark" SG_ 696 KAE_WindowsOpenReq "";
BA_ "EventCommandSignal" SG_ 696 KAE_WindowsOpenReqVD 0;
BA_ "GatewayedSignals" SG_ 696 KAE_WindowsOpenReqVD 0;
BA_ "GenSigInactiveValue" SG_ 696 KAE_WindowsOpenReqVD 0;
BA_ "GenSigInvalidValue" SG_ 696 KAE_WindowsOpenReqVD 0;
BA_ "GenSigSendType" SG_ 696 KAE_WindowsOpenReqVD 1;
BA_ "GenSigStartValue" SG_ 696 KAE_WindowsOpenReqVD 0;
BA_ "GenSigTimeoutValue" SG_ 696 KAE_WindowsOpenReqVD 0;
BA_ "Remark" SG_ 696 KAE_WindowsOpenReqVD "";
BA_ "EventCommandSignal" SG_ 696 KAE_TrunkUnlockReq 0;
BA_ "GatewayedSignals" SG_ 696 KAE_TrunkUnlockReq 0;
BA_ "GenSigInactiveValue" SG_ 696 KAE_TrunkUnlockReq 0;
BA_ "GenSigInvalidValue" SG_ 696 KAE_TrunkUnlockReq 0;
BA_ "GenSigSendType" SG_ 696 KAE_TrunkUnlockReq 1;
BA_ "GenSigStartValue" SG_ 696 KAE_TrunkUnlockReq 0;
BA_ "GenSigTimeoutValue" SG_ 696 KAE_TrunkUnlockReq 0;
BA_ "Remark" SG_ 696 KAE_TrunkUnlockReq "";
BA_ "EventCommandSignal" SG_ 696 KAE_TrunkUnlockReqVD 0;
BA_ "GatewayedSignals" SG_ 696 KAE_TrunkUnlockReqVD 0;
BA_ "GenSigInactiveValue" SG_ 696 KAE_TrunkUnlockReqVD 0;
BA_ "GenSigInvalidValue" SG_ 696 KAE_TrunkUnlockReqVD 0;
BA_ "GenSigSendType" SG_ 696 KAE_TrunkUnlockReqVD 1;
BA_ "GenSigStartValue" SG_ 696 KAE_TrunkUnlockReqVD 0;
BA_ "GenSigTimeoutValue" SG_ 696 KAE_TrunkUnlockReqVD 0;
BA_ "Remark" SG_ 696 KAE_TrunkUnlockReqVD "";
BA_ "EventCommandSignal" SG_ 696 KAE_HoodUnlockReq 0;
BA_ "GatewayedSignals" SG_ 696 KAE_HoodUnlockReq 0;
BA_ "GenSigInactiveValue" SG_ 696 KAE_HoodUnlockReq 0;
BA_ "GenSigInvalidValue" SG_ 696 KAE_HoodUnlockReq 0;
BA_ "GenSigSendType" SG_ 696 KAE_HoodUnlockReq 1;
BA_ "GenSigStartValue" SG_ 696 KAE_HoodUnlockReq 0;
BA_ "GenSigTimeoutValue" SG_ 696 KAE_HoodUnlockReq 0;
BA_ "Remark" SG_ 696 KAE_HoodUnlockReq "";
BA_ "EventCommandSignal" SG_ 696 KAE_HoodUnlockReqVD 0;
BA_ "GatewayedSignals" SG_ 696 KAE_HoodUnlockReqVD 0;
BA_ "GenSigInactiveValue" SG_ 696 KAE_HoodUnlockReqVD 0;
BA_ "GenSigInvalidValue" SG_ 696 KAE_HoodUnlockReqVD 0;
BA_ "GenSigSendType" SG_ 696 KAE_HoodUnlockReqVD 1;
BA_ "GenSigStartValue" SG_ 696 KAE_HoodUnlockReqVD 0;
BA_ "GenSigTimeoutValue" SG_ 696 KAE_HoodUnlockReqVD 0;
BA_ "Remark" SG_ 696 KAE_HoodUnlockReqVD "";
BA_ "EventCommandSignal" SG_ 696 KAE_PLGMOpenReq 0;
BA_ "GatewayedSignals" SG_ 696 KAE_PLGMOpenReq 0;
BA_ "GenSigInactiveValue" SG_ 696 KAE_PLGMOpenReq 0;
BA_ "GenSigInvalidValue" SG_ 696 KAE_PLGMOpenReq 0;
BA_ "GenSigSendType" SG_ 696 KAE_PLGMOpenReq 1;
BA_ "GenSigStartValue" SG_ 696 KAE_PLGMOpenReq 0;
BA_ "GenSigTimeoutValue" SG_ 696 KAE_PLGMOpenReq 0;
BA_ "Remark" SG_ 696 KAE_PLGMOpenReq "";
BA_ "EventCommandSignal" SG_ 696 KAE_PLGMOpenReqVD 0;
BA_ "GatewayedSignals" SG_ 696 KAE_PLGMOpenReqVD 0;
BA_ "GenSigInactiveValue" SG_ 696 KAE_PLGMOpenReqVD 0;
BA_ "GenSigInvalidValue" SG_ 696 KAE_PLGMOpenReqVD 0;
BA_ "GenSigSendType" SG_ 696 KAE_PLGMOpenReqVD 1;
BA_ "GenSigStartValue" SG_ 696 KAE_PLGMOpenReqVD 0;
BA_ "GenSigTimeoutValue" SG_ 696 KAE_PLGMOpenReqVD 0;
BA_ "Remark" SG_ 696 KAE_PLGMOpenReqVD "";
BA_ "EventCommandSignal" SG_ 696 KAE_PLGMCloseReq 0;
BA_ "GatewayedSignals" SG_ 696 KAE_PLGMCloseReq 0;
BA_ "GenSigInactiveValue" SG_ 696 KAE_PLGMCloseReq 0;
BA_ "GenSigInvalidValue" SG_ 696 KAE_PLGMCloseReq 0;
BA_ "GenSigSendType" SG_ 696 KAE_PLGMCloseReq 1;
BA_ "GenSigStartValue" SG_ 696 KAE_PLGMCloseReq 0;
BA_ "GenSigTimeoutValue" SG_ 696 KAE_PLGMCloseReq 0;
BA_ "Remark" SG_ 696 KAE_PLGMCloseReq "";
BA_ "EventCommandSignal" SG_ 696 KAE_PLGMCloseReqVD 0;
BA_ "GatewayedSignals" SG_ 696 KAE_PLGMCloseReqVD 0;
BA_ "GenSigInactiveValue" SG_ 696 KAE_PLGMCloseReqVD 0;
BA_ "GenSigInvalidValue" SG_ 696 KAE_PLGMCloseReqVD 0;
BA_ "GenSigSendType" SG_ 696 KAE_PLGMCloseReqVD 1;
BA_ "GenSigStartValue" SG_ 696 KAE_PLGMCloseReqVD 0;
BA_ "GenSigTimeoutValue" SG_ 696 KAE_PLGMCloseReqVD 0;
BA_ "Remark" SG_ 696 KAE_PLGMCloseReqVD "";
BA_ "EventCommandSignal" SG_ 696 KAE_SunRoofOpenReq 0;
BA_ "GatewayedSignals" SG_ 696 KAE_SunRoofOpenReq 0;
BA_ "GenSigInactiveValue" SG_ 696 KAE_SunRoofOpenReq 0;
BA_ "GenSigInvalidValue" SG_ 696 KAE_SunRoofOpenReq 0;
BA_ "GenSigSendType" SG_ 696 KAE_SunRoofOpenReq 1;
BA_ "GenSigStartValue" SG_ 696 KAE_SunRoofOpenReq 0;
BA_ "GenSigTimeoutValue" SG_ 696 KAE_SunRoofOpenReq 0;
BA_ "Remark" SG_ 696 KAE_SunRoofOpenReq "";
BA_ "EventCommandSignal" SG_ 696 KAE_SunRoofOpenReqVD 0;
BA_ "GatewayedSignals" SG_ 696 KAE_SunRoofOpenReqVD 0;
BA_ "GenSigInactiveValue" SG_ 696 KAE_SunRoofOpenReqVD 0;
BA_ "GenSigInvalidValue" SG_ 696 KAE_SunRoofOpenReqVD 0;
BA_ "GenSigSendType" SG_ 696 KAE_SunRoofOpenReqVD 1;
BA_ "GenSigStartValue" SG_ 696 KAE_SunRoofOpenReqVD 0;
BA_ "GenSigTimeoutValue" SG_ 696 KAE_SunRoofOpenReqVD 0;
BA_ "Remark" SG_ 696 KAE_SunRoofOpenReqVD "";
BA_ "EventCommandSignal" SG_ 696 KAE_SunRoofCloseReq 0;
BA_ "GatewayedSignals" SG_ 696 KAE_SunRoofCloseReq 0;
BA_ "GenSigInactiveValue" SG_ 696 KAE_SunRoofCloseReq 0;
BA_ "GenSigInvalidValue" SG_ 696 KAE_SunRoofCloseReq 0;
BA_ "GenSigSendType" SG_ 696 KAE_SunRoofCloseReq 1;
BA_ "GenSigStartValue" SG_ 696 KAE_SunRoofCloseReq 0;
BA_ "GenSigTimeoutValue" SG_ 696 KAE_SunRoofCloseReq 0;
BA_ "Remark" SG_ 696 KAE_SunRoofCloseReq "";
BA_ "EventCommandSignal" SG_ 696 KAE_SunRoofCloseReqVD 0;
BA_ "GatewayedSignals" SG_ 696 KAE_SunRoofCloseReqVD 0;
BA_ "GenSigInactiveValue" SG_ 696 KAE_SunRoofCloseReqVD 0;
BA_ "GenSigInvalidValue" SG_ 696 KAE_SunRoofCloseReqVD 0;
BA_ "GenSigSendType" SG_ 696 KAE_SunRoofCloseReqVD 1;
BA_ "GenSigStartValue" SG_ 696 KAE_SunRoofCloseReqVD 0;
BA_ "GenSigTimeoutValue" SG_ 696 KAE_SunRoofCloseReqVD 0;
BA_ "Remark" SG_ 696 KAE_SunRoofCloseReqVD "";
BA_ "EventCommandSignal" SG_ 696 KAE_PAAReq 0;
BA_ "GatewayedSignals" SG_ 696 KAE_PAAReq 0;
BA_ "GenSigInactiveValue" SG_ 696 KAE_PAAReq 0;
BA_ "GenSigInvalidValue" SG_ 696 KAE_PAAReq 0;
BA_ "GenSigSendType" SG_ 696 KAE_PAAReq 1;
BA_ "GenSigStartValue" SG_ 696 KAE_PAAReq 0;
BA_ "GenSigTimeoutValue" SG_ 696 KAE_PAAReq 0;
BA_ "Remark" SG_ 696 KAE_PAAReq "";
BA_ "EventCommandSignal" SG_ 696 KAE_PAAReqVd 0;
BA_ "GatewayedSignals" SG_ 696 KAE_PAAReqVd 0;
BA_ "GenSigInactiveValue" SG_ 696 KAE_PAAReqVd 0;
BA_ "GenSigInvalidValue" SG_ 696 KAE_PAAReqVd 0;
BA_ "GenSigSendType" SG_ 696 KAE_PAAReqVd 1;
BA_ "GenSigStartValue" SG_ 696 KAE_PAAReqVd 0;
BA_ "GenSigTimeoutValue" SG_ 696 KAE_PAAReqVd 0;
BA_ "Remark" SG_ 696 KAE_PAAReqVd "";
BA_ "EventCommandSignal" SG_ 696 KAE_EDK1UnlockBtnSt 0;
BA_ "GatewayedSignals" SG_ 696 KAE_EDK1UnlockBtnSt 0;
BA_ "GenSigInactiveValue" SG_ 696 KAE_EDK1UnlockBtnSt 0;
BA_ "GenSigInvalidValue" SG_ 696 KAE_EDK1UnlockBtnSt 0;
BA_ "GenSigSendType" SG_ 696 KAE_EDK1UnlockBtnSt 1;
BA_ "GenSigStartValue" SG_ 696 KAE_EDK1UnlockBtnSt 0;
BA_ "GenSigTimeoutValue" SG_ 696 KAE_EDK1UnlockBtnSt 0;
BA_ "Remark" SG_ 696 KAE_EDK1UnlockBtnSt "";
BA_ "EventCommandSignal" SG_ 696 KAE_EDK1LockBtnSt 0;
BA_ "GatewayedSignals" SG_ 696 KAE_EDK1LockBtnSt 0;
BA_ "GenSigInactiveValue" SG_ 696 KAE_EDK1LockBtnSt 0;
BA_ "GenSigInvalidValue" SG_ 696 KAE_EDK1LockBtnSt 0;
BA_ "GenSigSendType" SG_ 696 KAE_EDK1LockBtnSt 1;
BA_ "GenSigStartValue" SG_ 696 KAE_EDK1LockBtnSt 0;
BA_ "GenSigTimeoutValue" SG_ 696 KAE_EDK1LockBtnSt 0;
BA_ "Remark" SG_ 696 KAE_EDK1LockBtnSt "";
BA_ "EventCommandSignal" SG_ 696 KAE_EDK1RESBtnSt 0;
BA_ "GatewayedSignals" SG_ 696 KAE_EDK1RESBtnSt 0;
BA_ "GenSigInactiveValue" SG_ 696 KAE_EDK1RESBtnSt 0;
BA_ "GenSigInvalidValue" SG_ 696 KAE_EDK1RESBtnSt 0;
BA_ "GenSigSendType" SG_ 696 KAE_EDK1RESBtnSt 1;
BA_ "GenSigStartValue" SG_ 696 KAE_EDK1RESBtnSt 0;
BA_ "GenSigTimeoutValue" SG_ 696 KAE_EDK1RESBtnSt 0;
BA_ "Remark" SG_ 696 KAE_EDK1RESBtnSt "";
BA_ "EventCommandSignal" SG_ 696 KAE_EDK1PSD_LBtnSt 0;
BA_ "GatewayedSignals" SG_ 696 KAE_EDK1PSD_LBtnSt 0;
BA_ "GenSigInactiveValue" SG_ 696 KAE_EDK1PSD_LBtnSt 0;
BA_ "GenSigInvalidValue" SG_ 696 KAE_EDK1PSD_LBtnSt 0;
BA_ "GenSigSendType" SG_ 696 KAE_EDK1PSD_LBtnSt 1;
BA_ "GenSigStartValue" SG_ 696 KAE_EDK1PSD_LBtnSt 0;
BA_ "GenSigTimeoutValue" SG_ 696 KAE_EDK1PSD_LBtnSt 0;
BA_ "Remark" SG_ 696 KAE_EDK1PSD_LBtnSt "";
BA_ "EventCommandSignal" SG_ 696 KAE_EDK1PSD_RBtnSt 0;
BA_ "GatewayedSignals" SG_ 696 KAE_EDK1PSD_RBtnSt 0;
BA_ "GenSigInactiveValue" SG_ 696 KAE_EDK1PSD_RBtnSt 0;
BA_ "GenSigInvalidValue" SG_ 696 KAE_EDK1PSD_RBtnSt 0;
BA_ "GenSigSendType" SG_ 696 KAE_EDK1PSD_RBtnSt 1;
BA_ "GenSigStartValue" SG_ 696 KAE_EDK1PSD_RBtnSt 0;
BA_ "GenSigTimeoutValue" SG_ 696 KAE_EDK1PSD_RBtnSt 0;
BA_ "Remark" SG_ 696 KAE_EDK1PSD_RBtnSt "";
BA_ "EventCommandSignal" SG_ 696 KAE_EDK1TrunkBtnSt 0;
BA_ "GatewayedSignals" SG_ 696 KAE_EDK1TrunkBtnSt 0;
BA_ "GenSigInactiveValue" SG_ 696 KAE_EDK1TrunkBtnSt 0;
BA_ "GenSigInvalidValue" SG_ 696 KAE_EDK1TrunkBtnSt 0;
BA_ "GenSigSendType" SG_ 696 KAE_EDK1TrunkBtnSt 1;
BA_ "GenSigStartValue" SG_ 696 KAE_EDK1TrunkBtnSt 0;
BA_ "GenSigTimeoutValue" SG_ 696 KAE_EDK1TrunkBtnSt 0;
BA_ "Remark" SG_ 696 KAE_EDK1TrunkBtnSt "";
BA_ "EventCommandSignal" SG_ 696 KAE_EDK1PanicBtnSt 0;
BA_ "GatewayedSignals" SG_ 696 KAE_EDK1PanicBtnSt 0;
BA_ "GenSigInactiveValue" SG_ 696 KAE_EDK1PanicBtnSt 0;
BA_ "GenSigInvalidValue" SG_ 696 KAE_EDK1PanicBtnSt 0;
BA_ "GenSigSendType" SG_ 696 KAE_EDK1PanicBtnSt 1;
BA_ "GenSigStartValue" SG_ 696 KAE_EDK1PanicBtnSt 0;
BA_ "GenSigTimeoutValue" SG_ 696 KAE_EDK1PanicBtnSt 0;
BA_ "Remark" SG_ 696 KAE_EDK1PanicBtnSt "";
BA_ "EventCommandSignal" SG_ 696 KAE_EDK1User_definedBtnSt 0;
BA_ "GatewayedSignals" SG_ 696 KAE_EDK1User_definedBtnSt 0;
BA_ "GenSigInactiveValue" SG_ 696 KAE_EDK1User_definedBtnSt 0;
BA_ "GenSigInvalidValue" SG_ 696 KAE_EDK1User_definedBtnSt 0;
BA_ "GenSigSendType" SG_ 696 KAE_EDK1User_definedBtnSt 1;
BA_ "GenSigStartValue" SG_ 696 KAE_EDK1User_definedBtnSt 0;
BA_ "GenSigTimeoutValue" SG_ 696 KAE_EDK1User_definedBtnSt 0;
BA_ "Remark" SG_ 696 KAE_EDK1User_definedBtnSt "";
BA_ "EventCommandSignal" SG_ 696 KAE_EDK2UnlockBtnSt 0;
BA_ "GatewayedSignals" SG_ 696 KAE_EDK2UnlockBtnSt 0;
BA_ "GenSigInactiveValue" SG_ 696 KAE_EDK2UnlockBtnSt 0;
BA_ "GenSigInvalidValue" SG_ 696 KAE_EDK2UnlockBtnSt 0;
BA_ "GenSigSendType" SG_ 696 KAE_EDK2UnlockBtnSt 1;
BA_ "GenSigStartValue" SG_ 696 KAE_EDK2UnlockBtnSt 0;
BA_ "GenSigTimeoutValue" SG_ 696 KAE_EDK2UnlockBtnSt 0;
BA_ "Remark" SG_ 696 KAE_EDK2UnlockBtnSt "";
BA_ "EventCommandSignal" SG_ 696 KAE_EDK2LockBtnSt 0;
BA_ "GatewayedSignals" SG_ 696 KAE_EDK2LockBtnSt 0;
BA_ "GenSigInactiveValue" SG_ 696 KAE_EDK2LockBtnSt 0;
BA_ "GenSigInvalidValue" SG_ 696 KAE_EDK2LockBtnSt 0;
BA_ "GenSigSendType" SG_ 696 KAE_EDK2LockBtnSt 1;
BA_ "GenSigStartValue" SG_ 696 KAE_EDK2LockBtnSt 0;
BA_ "GenSigTimeoutValue" SG_ 696 KAE_EDK2LockBtnSt 0;
BA_ "Remark" SG_ 696 KAE_EDK2LockBtnSt "";
BA_ "EventCommandSignal" SG_ 696 KAE_EDK2RESBtnSt 0;
BA_ "GatewayedSignals" SG_ 696 KAE_EDK2RESBtnSt 0;
BA_ "GenSigInactiveValue" SG_ 696 KAE_EDK2RESBtnSt 0;
BA_ "GenSigInvalidValue" SG_ 696 KAE_EDK2RESBtnSt 0;
BA_ "GenSigSendType" SG_ 696 KAE_EDK2RESBtnSt 1;
BA_ "GenSigStartValue" SG_ 696 KAE_EDK2RESBtnSt 0;
BA_ "GenSigTimeoutValue" SG_ 696 KAE_EDK2RESBtnSt 0;
BA_ "Remark" SG_ 696 KAE_EDK2RESBtnSt "";
BA_ "EventCommandSignal" SG_ 696 PKC_RemPwrOnOffReq 0;
BA_ "GatewayedSignals" SG_ 696 PKC_RemPwrOnOffReq 0;
BA_ "GenSigInactiveValue" SG_ 696 PKC_RemPwrOnOffReq 0;
BA_ "GenSigInvalidValue" SG_ 696 PKC_RemPwrOnOffReq 0;
BA_ "GenSigSendType" SG_ 696 PKC_RemPwrOnOffReq 1;
BA_ "GenSigStartValue" SG_ 696 PKC_RemPwrOnOffReq 0;
BA_ "GenSigTimeoutValue" SG_ 696 PKC_RemPwrOnOffReq 0;
BA_ "Remark" SG_ 696 PKC_RemPwrOnOffReq "";
BA_ "EventCommandSignal" SG_ 696 KAE_EDK2PSD_LBtnSt 0;
BA_ "GatewayedSignals" SG_ 696 KAE_EDK2PSD_LBtnSt 0;
BA_ "GenSigInactiveValue" SG_ 696 KAE_EDK2PSD_LBtnSt 0;
BA_ "GenSigInvalidValue" SG_ 696 KAE_EDK2PSD_LBtnSt 0;
BA_ "GenSigSendType" SG_ 696 KAE_EDK2PSD_LBtnSt 1;
BA_ "GenSigStartValue" SG_ 696 KAE_EDK2PSD_LBtnSt 0;
BA_ "GenSigTimeoutValue" SG_ 696 KAE_EDK2PSD_LBtnSt 0;
BA_ "Remark" SG_ 696 KAE_EDK2PSD_LBtnSt "";
BA_ "EventCommandSignal" SG_ 696 KAE_EDK2PSD_RBtnSt 0;
BA_ "GatewayedSignals" SG_ 696 KAE_EDK2PSD_RBtnSt 0;
BA_ "GenSigInactiveValue" SG_ 696 KAE_EDK2PSD_RBtnSt 0;
BA_ "GenSigInvalidValue" SG_ 696 KAE_EDK2PSD_RBtnSt 0;
BA_ "GenSigSendType" SG_ 696 KAE_EDK2PSD_RBtnSt 1;
BA_ "GenSigStartValue" SG_ 696 KAE_EDK2PSD_RBtnSt 0;
BA_ "GenSigTimeoutValue" SG_ 696 KAE_EDK2PSD_RBtnSt 0;
BA_ "Remark" SG_ 696 KAE_EDK2PSD_RBtnSt "";
BA_ "EventCommandSignal" SG_ 696 KAE_EDK2TrunkBtnSt 0;
BA_ "GatewayedSignals" SG_ 696 KAE_EDK2TrunkBtnSt 0;
BA_ "GenSigInactiveValue" SG_ 696 KAE_EDK2TrunkBtnSt 0;
BA_ "GenSigInvalidValue" SG_ 696 KAE_EDK2TrunkBtnSt 0;
BA_ "GenSigSendType" SG_ 696 KAE_EDK2TrunkBtnSt 1;
BA_ "GenSigStartValue" SG_ 696 KAE_EDK2TrunkBtnSt 0;
BA_ "GenSigTimeoutValue" SG_ 696 KAE_EDK2TrunkBtnSt 0;
BA_ "Remark" SG_ 696 KAE_EDK2TrunkBtnSt "";
BA_ "EventCommandSignal" SG_ 696 KAE_EDK2PanicBtnSt 0;
BA_ "GatewayedSignals" SG_ 696 KAE_EDK2PanicBtnSt 0;
BA_ "GenSigInactiveValue" SG_ 696 KAE_EDK2PanicBtnSt 0;
BA_ "GenSigInvalidValue" SG_ 696 KAE_EDK2PanicBtnSt 0;
BA_ "GenSigSendType" SG_ 696 KAE_EDK2PanicBtnSt 1;
BA_ "GenSigStartValue" SG_ 696 KAE_EDK2PanicBtnSt 0;
BA_ "GenSigTimeoutValue" SG_ 696 KAE_EDK2PanicBtnSt 0;
BA_ "Remark" SG_ 696 KAE_EDK2PanicBtnSt "";
BA_ "EventCommandSignal" SG_ 696 KAE_EDK2User_definedBtnSt 0;
BA_ "GatewayedSignals" SG_ 696 KAE_EDK2User_definedBtnSt 0;
BA_ "GenSigInactiveValue" SG_ 696 KAE_EDK2User_definedBtnSt 0;
BA_ "GenSigInvalidValue" SG_ 696 KAE_EDK2User_definedBtnSt 0;
BA_ "GenSigSendType" SG_ 696 KAE_EDK2User_definedBtnSt 1;
BA_ "GenSigStartValue" SG_ 696 KAE_EDK2User_definedBtnSt 0;
BA_ "GenSigTimeoutValue" SG_ 696 KAE_EDK2User_definedBtnSt 0;
BA_ "Remark" SG_ 696 KAE_EDK2User_definedBtnSt "";
BA_ "EventCommandSignal" SG_ 696 KAE_EDK3UnlockBtnSt 0;
BA_ "GatewayedSignals" SG_ 696 KAE_EDK3UnlockBtnSt 0;
BA_ "GenSigInactiveValue" SG_ 696 KAE_EDK3UnlockBtnSt 0;
BA_ "GenSigInvalidValue" SG_ 696 KAE_EDK3UnlockBtnSt 0;
BA_ "GenSigSendType" SG_ 696 KAE_EDK3UnlockBtnSt 1;
BA_ "GenSigStartValue" SG_ 696 KAE_EDK3UnlockBtnSt 0;
BA_ "GenSigTimeoutValue" SG_ 696 KAE_EDK3UnlockBtnSt 0;
BA_ "Remark" SG_ 696 KAE_EDK3UnlockBtnSt "";
BA_ "EventCommandSignal" SG_ 696 KAE_EDK3LockBtnSt 0;
BA_ "GatewayedSignals" SG_ 696 KAE_EDK3LockBtnSt 0;
BA_ "GenSigInactiveValue" SG_ 696 KAE_EDK3LockBtnSt 0;
BA_ "GenSigInvalidValue" SG_ 696 KAE_EDK3LockBtnSt 0;
BA_ "GenSigSendType" SG_ 696 KAE_EDK3LockBtnSt 1;
BA_ "GenSigStartValue" SG_ 696 KAE_EDK3LockBtnSt 0;
BA_ "GenSigTimeoutValue" SG_ 696 KAE_EDK3LockBtnSt 0;
BA_ "Remark" SG_ 696 KAE_EDK3LockBtnSt "";
BA_ "EventCommandSignal" SG_ 696 KAE_EDK3RESBtnSt 0;
BA_ "GatewayedSignals" SG_ 696 KAE_EDK3RESBtnSt 0;
BA_ "GenSigInactiveValue" SG_ 696 KAE_EDK3RESBtnSt 0;
BA_ "GenSigInvalidValue" SG_ 696 KAE_EDK3RESBtnSt 0;
BA_ "GenSigSendType" SG_ 696 KAE_EDK3RESBtnSt 1;
BA_ "GenSigStartValue" SG_ 696 KAE_EDK3RESBtnSt 0;
BA_ "GenSigTimeoutValue" SG_ 696 KAE_EDK3RESBtnSt 0;
BA_ "Remark" SG_ 696 KAE_EDK3RESBtnSt "";
BA_ "EventCommandSignal" SG_ 696 KAE_EDK3PSD_LBtnSt 0;
BA_ "GatewayedSignals" SG_ 696 KAE_EDK3PSD_LBtnSt 0;
BA_ "GenSigInactiveValue" SG_ 696 KAE_EDK3PSD_LBtnSt 0;
BA_ "GenSigInvalidValue" SG_ 696 KAE_EDK3PSD_LBtnSt 0;
BA_ "GenSigSendType" SG_ 696 KAE_EDK3PSD_LBtnSt 1;
BA_ "GenSigStartValue" SG_ 696 KAE_EDK3PSD_LBtnSt 0;
BA_ "GenSigTimeoutValue" SG_ 696 KAE_EDK3PSD_LBtnSt 0;
BA_ "Remark" SG_ 696 KAE_EDK3PSD_LBtnSt "";
BA_ "EventCommandSignal" SG_ 696 KAE_EDK3PSD_RBtnSt 0;
BA_ "GatewayedSignals" SG_ 696 KAE_EDK3PSD_RBtnSt 0;
BA_ "GenSigInactiveValue" SG_ 696 KAE_EDK3PSD_RBtnSt 0;
BA_ "GenSigInvalidValue" SG_ 696 KAE_EDK3PSD_RBtnSt 0;
BA_ "GenSigSendType" SG_ 696 KAE_EDK3PSD_RBtnSt 1;
BA_ "GenSigStartValue" SG_ 696 KAE_EDK3PSD_RBtnSt 0;
BA_ "GenSigTimeoutValue" SG_ 696 KAE_EDK3PSD_RBtnSt 0;
BA_ "Remark" SG_ 696 KAE_EDK3PSD_RBtnSt "";
BA_ "EventCommandSignal" SG_ 696 KAE_EDK3TrunkBtnSt 0;
BA_ "GatewayedSignals" SG_ 696 KAE_EDK3TrunkBtnSt 0;
BA_ "GenSigInactiveValue" SG_ 696 KAE_EDK3TrunkBtnSt 0;
BA_ "GenSigInvalidValue" SG_ 696 KAE_EDK3TrunkBtnSt 0;
BA_ "GenSigSendType" SG_ 696 KAE_EDK3TrunkBtnSt 1;
BA_ "GenSigStartValue" SG_ 696 KAE_EDK3TrunkBtnSt 0;
BA_ "GenSigTimeoutValue" SG_ 696 KAE_EDK3TrunkBtnSt 0;
BA_ "Remark" SG_ 696 KAE_EDK3TrunkBtnSt "";
BA_ "EventCommandSignal" SG_ 696 KAE_EDK3PanicBtnSt 0;
BA_ "GatewayedSignals" SG_ 696 KAE_EDK3PanicBtnSt 0;
BA_ "GenSigInactiveValue" SG_ 696 KAE_EDK3PanicBtnSt 0;
BA_ "GenSigInvalidValue" SG_ 696 KAE_EDK3PanicBtnSt 0;
BA_ "GenSigSendType" SG_ 696 KAE_EDK3PanicBtnSt 1;
BA_ "GenSigStartValue" SG_ 696 KAE_EDK3PanicBtnSt 0;
BA_ "GenSigTimeoutValue" SG_ 696 KAE_EDK3PanicBtnSt 0;
BA_ "Remark" SG_ 696 KAE_EDK3PanicBtnSt "";
BA_ "EventCommandSignal" SG_ 696 KAE_EDK3User_definedBtnSt 0;
BA_ "GatewayedSignals" SG_ 696 KAE_EDK3User_definedBtnSt 0;
BA_ "GenSigInactiveValue" SG_ 696 KAE_EDK3User_definedBtnSt 0;
BA_ "GenSigInvalidValue" SG_ 696 KAE_EDK3User_definedBtnSt 0;
BA_ "GenSigSendType" SG_ 696 KAE_EDK3User_definedBtnSt 1;
BA_ "GenSigStartValue" SG_ 696 KAE_EDK3User_definedBtnSt 0;
BA_ "GenSigTimeoutValue" SG_ 696 KAE_EDK3User_definedBtnSt 0;
BA_ "Remark" SG_ 696 KAE_EDK3User_definedBtnSt "";
BA_ "EventCommandSignal" SG_ 696 PKC_PhoneRPAOnlineOrNot 0;
BA_ "GatewayedSignals" SG_ 696 PKC_PhoneRPAOnlineOrNot 0;
BA_ "GenSigInactiveValue" SG_ 696 PKC_PhoneRPAOnlineOrNot 0;
BA_ "GenSigInvalidValue" SG_ 696 PKC_PhoneRPAOnlineOrNot 0;
BA_ "GenSigSendType" SG_ 696 PKC_PhoneRPAOnlineOrNot 1;
BA_ "GenSigStartValue" SG_ 696 PKC_PhoneRPAOnlineOrNot 0;
BA_ "GenSigTimeoutValue" SG_ 696 PKC_PhoneRPAOnlineOrNot 0;
BA_ "Remark" SG_ 696 PKC_PhoneRPAOnlineOrNot "";
BA_ "EventCommandSignal" SG_ 134 Theft_Auth_ADCCode 1;
BA_ "GatewayedSignals" SG_ 134 Theft_Auth_ADCCode 0;
BA_ "GenSigInactiveValue" SG_ 134 Theft_Auth_ADCCode 0;
BA_ "GenSigInvalidValue" SG_ 134 Theft_Auth_ADCCode 0;
BA_ "GenSigSendType" SG_ 134 Theft_Auth_ADCCode 0;
BA_ "GenSigStartValue" SG_ 134 Theft_Auth_ADCCode 0;
BA_ "GenSigTimeoutValue" SG_ 134 Theft_Auth_ADCCode 0;
BA_ "Remark" SG_ 134 Theft_Auth_ADCCode "";
BA_ "EventCommandSignal" SG_ 793 LBMS_1_CRC 0;
BA_ "GatewayedSignals" SG_ 793 LBMS_1_CRC 0;
BA_ "GenSigInactiveValue" SG_ 793 LBMS_1_CRC 0;
BA_ "GenSigInvalidValue" SG_ 793 LBMS_1_CRC 0;
BA_ "GenSigSendType" SG_ 793 LBMS_1_CRC 1;
BA_ "GenSigStartValue" SG_ 793 LBMS_1_CRC 0;
BA_ "GenSigTimeoutValue" SG_ 793 LBMS_1_CRC 0;
BA_ "Remark" SG_ 793 LBMS_1_CRC "";
BA_ "EventCommandSignal" SG_ 793 LBMS_1_Counter 0;
BA_ "GatewayedSignals" SG_ 793 LBMS_1_Counter 0;
BA_ "GenSigInactiveValue" SG_ 793 LBMS_1_Counter 0;
BA_ "GenSigInvalidValue" SG_ 793 LBMS_1_Counter 0;
BA_ "GenSigSendType" SG_ 793 LBMS_1_Counter 1;
BA_ "GenSigStartValue" SG_ 793 LBMS_1_Counter 0;
BA_ "GenSigTimeoutValue" SG_ 793 LBMS_1_Counter 0;
BA_ "Remark" SG_ 793 LBMS_1_Counter "";
BA_ "EventCommandSignal" SG_ 793 LBMS_SOFVD 0;
BA_ "GatewayedSignals" SG_ 793 LBMS_SOFVD 0;
BA_ "GenSigInactiveValue" SG_ 793 LBMS_SOFVD 0;
BA_ "GenSigInvalidValue" SG_ 793 LBMS_SOFVD 0;
BA_ "GenSigSendType" SG_ 793 LBMS_SOFVD 1;
BA_ "GenSigStartValue" SG_ 793 LBMS_SOFVD 0;
BA_ "GenSigTimeoutValue" SG_ 793 LBMS_SOFVD 0;
BA_ "Remark" SG_ 793 LBMS_SOFVD "";
BA_ "EventCommandSignal" SG_ 793 LBMS_SOFEN 0;
BA_ "GatewayedSignals" SG_ 793 LBMS_SOFEN 0;
BA_ "GenSigInactiveValue" SG_ 793 LBMS_SOFEN 0;
BA_ "GenSigInvalidValue" SG_ 793 LBMS_SOFEN 0;
BA_ "GenSigSendType" SG_ 793 LBMS_SOFEN 1;
BA_ "GenSigStartValue" SG_ 793 LBMS_SOFEN 0;
BA_ "GenSigTimeoutValue" SG_ 793 LBMS_SOFEN 0;
BA_ "Remark" SG_ 793 LBMS_SOFEN "";
BA_ "EventCommandSignal" SG_ 1024 SYNC_FC_Type 0;
BA_ "GatewayedSignals" SG_ 1024 SYNC_FC_Type 0;
BA_ "GenSigInactiveValue" SG_ 1024 SYNC_FC_Type 0;
BA_ "GenSigInvalidValue" SG_ 1024 SYNC_FC_Type 0;
BA_ "GenSigSendType" SG_ 1024 SYNC_FC_Type 1;
BA_ "GenSigStartValue" SG_ 1024 SYNC_FC_Type 0;
BA_ "GenSigTimeoutValue" SG_ 1024 SYNC_FC_Type 0;
BA_ "Remark" SG_ 1024 SYNC_FC_Type "";
BA_ "EventCommandSignal" SG_ 1024 SYNC_FC_CRC 0;
BA_ "GatewayedSignals" SG_ 1024 SYNC_FC_CRC 0;
BA_ "GenSigInactiveValue" SG_ 1024 SYNC_FC_CRC 0;
BA_ "GenSigInvalidValue" SG_ 1024 SYNC_FC_CRC 0;
BA_ "GenSigSendType" SG_ 1024 SYNC_FC_CRC 1;
BA_ "GenSigStartValue" SG_ 1024 SYNC_FC_CRC 0;
BA_ "GenSigTimeoutValue" SG_ 1024 SYNC_FC_CRC 0;
BA_ "Remark" SG_ 1024 SYNC_FC_CRC "";
BA_ "EventCommandSignal" SG_ 1024 SYNC_FC_Sequencecnt 0;
BA_ "GatewayedSignals" SG_ 1024 SYNC_FC_Sequencecnt 0;
BA_ "GenSigInactiveValue" SG_ 1024 SYNC_FC_Sequencecnt 0;
BA_ "GenSigInvalidValue" SG_ 1024 SYNC_FC_Sequencecnt 0;
BA_ "GenSigSendType" SG_ 1024 SYNC_FC_Sequencecnt 1;
BA_ "GenSigStartValue" SG_ 1024 SYNC_FC_Sequencecnt 0;
BA_ "GenSigTimeoutValue" SG_ 1024 SYNC_FC_Sequencecnt 0;
BA_ "Remark" SG_ 1024 SYNC_FC_Sequencecnt "";
BA_ "EventCommandSignal" SG_ 1024 SYNC_FC_TimeDomain 0;
BA_ "GatewayedSignals" SG_ 1024 SYNC_FC_TimeDomain 0;
BA_ "GenSigInactiveValue" SG_ 1024 SYNC_FC_TimeDomain 0;
BA_ "GenSigInvalidValue" SG_ 1024 SYNC_FC_TimeDomain 0;
BA_ "GenSigSendType" SG_ 1024 SYNC_FC_TimeDomain 1;
BA_ "GenSigStartValue" SG_ 1024 SYNC_FC_TimeDomain 0;
BA_ "GenSigTimeoutValue" SG_ 1024 SYNC_FC_TimeDomain 0;
BA_ "Remark" SG_ 1024 SYNC_FC_TimeDomain "";
BA_ "EventCommandSignal" SG_ 1024 SYNC_FC_OVS 0;
BA_ "GatewayedSignals" SG_ 1024 SYNC_FC_OVS 0;
BA_ "GenSigInactiveValue" SG_ 1024 SYNC_FC_OVS 0;
BA_ "GenSigInvalidValue" SG_ 1024 SYNC_FC_OVS 0;
BA_ "GenSigSendType" SG_ 1024 SYNC_FC_OVS 1;
BA_ "GenSigStartValue" SG_ 1024 SYNC_FC_OVS 0;
BA_ "GenSigTimeoutValue" SG_ 1024 SYNC_FC_OVS 0;
BA_ "Remark" SG_ 1024 SYNC_FC_OVS "";
BA_ "EventCommandSignal" SG_ 1024 SYNC_FC_SGW 0;
BA_ "GatewayedSignals" SG_ 1024 SYNC_FC_SGW 0;
BA_ "GenSigInactiveValue" SG_ 1024 SYNC_FC_SGW 0;
BA_ "GenSigInvalidValue" SG_ 1024 SYNC_FC_SGW 0;
BA_ "GenSigSendType" SG_ 1024 SYNC_FC_SGW 1;
BA_ "GenSigStartValue" SG_ 1024 SYNC_FC_SGW 0;
BA_ "GenSigTimeoutValue" SG_ 1024 SYNC_FC_SGW 0;
BA_ "Remark" SG_ 1024 SYNC_FC_SGW "";
BA_ "EventCommandSignal" SG_ 1024 SYNC_FC_Reserved 0;
BA_ "GatewayedSignals" SG_ 1024 SYNC_FC_Reserved 0;
BA_ "GenSigInactiveValue" SG_ 1024 SYNC_FC_Reserved 0;
BA_ "GenSigInvalidValue" SG_ 1024 SYNC_FC_Reserved 0;
BA_ "GenSigSendType" SG_ 1024 SYNC_FC_Reserved 1;
BA_ "GenSigStartValue" SG_ 1024 SYNC_FC_Reserved 0;
BA_ "GenSigTimeoutValue" SG_ 1024 SYNC_FC_Reserved 0;
BA_ "Remark" SG_ 1024 SYNC_FC_Reserved "";
BA_ "EventCommandSignal" SG_ 1024 SYNC_FC_SyncTime 0;
BA_ "GatewayedSignals" SG_ 1024 SYNC_FC_SyncTime 0;
BA_ "GenSigInactiveValue" SG_ 1024 SYNC_FC_SyncTime 0;
BA_ "GenSigInvalidValue" SG_ 1024 SYNC_FC_SyncTime 0;
BA_ "GenSigSendType" SG_ 1024 SYNC_FC_SyncTime 1;
BA_ "GenSigStartValue" SG_ 1024 SYNC_FC_SyncTime 0;
BA_ "GenSigTimeoutValue" SG_ 1024 SYNC_FC_SyncTime 0;
BA_ "Remark" SG_ 1024 SYNC_FC_SyncTime "";
BA_ "EventCommandSignal" SG_ 476 FCP_OmniViewBtnSt 1;
BA_ "GatewayedSignals" SG_ 476 FCP_OmniViewBtnSt 0;
BA_ "GenSigInactiveValue" SG_ 476 FCP_OmniViewBtnSt 0;
BA_ "GenSigInvalidValue" SG_ 476 FCP_OmniViewBtnSt 0;
BA_ "GenSigSendType" SG_ 476 FCP_OmniViewBtnSt 0;
BA_ "GenSigStartValue" SG_ 476 FCP_OmniViewBtnSt 0;
BA_ "GenSigTimeoutValue" SG_ 476 FCP_OmniViewBtnSt 0;
BA_ "Remark" SG_ 476 FCP_OmniViewBtnSt "";
BA_ "EventCommandSignal" SG_ 476 FCP_OmniViewBtnStVD 0;
BA_ "GatewayedSignals" SG_ 476 FCP_OmniViewBtnStVD 0;
BA_ "GenSigInactiveValue" SG_ 476 FCP_OmniViewBtnStVD 0;
BA_ "GenSigInvalidValue" SG_ 476 FCP_OmniViewBtnStVD 0;
BA_ "GenSigSendType" SG_ 476 FCP_OmniViewBtnStVD 1;
BA_ "GenSigStartValue" SG_ 476 FCP_OmniViewBtnStVD 0;
BA_ "GenSigTimeoutValue" SG_ 476 FCP_OmniViewBtnStVD 0;
BA_ "Remark" SG_ 476 FCP_OmniViewBtnStVD "";
BA_ "EventCommandSignal" SG_ 1657 ADC_MCU_Diag_Request 0;
BA_ "GatewayedSignals" SG_ 1657 ADC_MCU_Diag_Request 0;
BA_ "GenSigInactiveValue" SG_ 1657 ADC_MCU_Diag_Request 0;
BA_ "GenSigInvalidValue" SG_ 1657 ADC_MCU_Diag_Request 0;
BA_ "GenSigSendType" SG_ 1657 ADC_MCU_Diag_Request 1;
BA_ "GenSigStartValue" SG_ 1657 ADC_MCU_Diag_Request 0;
BA_ "GenSigTimeoutValue" SG_ 1657 ADC_MCU_Diag_Request 0;
BA_ "Remark" SG_ 1657 ADC_MCU_Diag_Request "";
BA_ "EventCommandSignal" SG_ 1806 ADC_Diag_Request 1;
BA_ "GatewayedSignals" SG_ 1806 ADC_Diag_Request 0;
BA_ "GenSigInactiveValue" SG_ 1806 ADC_Diag_Request 0;
BA_ "GenSigInvalidValue" SG_ 1806 ADC_Diag_Request 0;
BA_ "GenSigSendType" SG_ 1806 ADC_Diag_Request 0;
BA_ "GenSigStartValue" SG_ 1806 ADC_Diag_Request 0;
BA_ "GenSigTimeoutValue" SG_ 1806 ADC_Diag_Request 0;
BA_ "Remark" SG_ 1806 ADC_Diag_Request "";
BA_ "EventCommandSignal" SG_ 1854 FR_Diag_Request 0;
BA_ "GatewayedSignals" SG_ 1854 FR_Diag_Request 0;
BA_ "GenSigInactiveValue" SG_ 1854 FR_Diag_Request 0;
BA_ "GenSigInvalidValue" SG_ 1854 FR_Diag_Request 0;
BA_ "GenSigSendType" SG_ 1854 FR_Diag_Request 1;
BA_ "GenSigStartValue" SG_ 1854 FR_Diag_Request 0;
BA_ "GenSigTimeoutValue" SG_ 1854 FR_Diag_Request 0;
BA_ "Remark" SG_ 1854 FR_Diag_Request "";
BA_ "EventCommandSignal" SG_ 1354 RLR_NMNodeAddress 0;
BA_ "GatewayedSignals" SG_ 1354 RLR_NMNodeAddress 0;
BA_ "GenSigInactiveValue" SG_ 1354 RLR_NMNodeAddress 0;
BA_ "GenSigInvalidValue" SG_ 1354 RLR_NMNodeAddress 0;
BA_ "GenSigSendType" SG_ 1354 RLR_NMNodeAddress 1;
BA_ "GenSigStartValue" SG_ 1354 RLR_NMNodeAddress 74;
BA_ "GenSigTimeoutValue" SG_ 1354 RLR_NMNodeAddress 0;
BA_ "Remark" SG_ 1354 RLR_NMNodeAddress "此信号恒定为：0x4A";
BA_ "EventCommandSignal" SG_ 1354 RLR_NMCBV 0;
BA_ "GatewayedSignals" SG_ 1354 RLR_NMCBV 0;
BA_ "GenSigInactiveValue" SG_ 1354 RLR_NMCBV 0;
BA_ "GenSigInvalidValue" SG_ 1354 RLR_NMCBV 0;
BA_ "GenSigSendType" SG_ 1354 RLR_NMCBV 1;
BA_ "GenSigStartValue" SG_ 1354 RLR_NMCBV 0;
BA_ "GenSigTimeoutValue" SG_ 1354 RLR_NMCBV 0;
BA_ "Remark" SG_ 1354 RLR_NMCBV "此信号恒定为：0x50";
BA_ "EventCommandSignal" SG_ 1354 RLR_NMWakeupOrigin 0;
BA_ "GatewayedSignals" SG_ 1354 RLR_NMWakeupOrigin 0;
BA_ "GenSigInactiveValue" SG_ 1354 RLR_NMWakeupOrigin 0;
BA_ "GenSigInvalidValue" SG_ 1354 RLR_NMWakeupOrigin 0;
BA_ "GenSigSendType" SG_ 1354 RLR_NMWakeupOrigin 1;
BA_ "GenSigStartValue" SG_ 1354 RLR_NMWakeupOrigin 0;
BA_ "GenSigTimeoutValue" SG_ 1354 RLR_NMWakeupOrigin 0;
BA_ "Remark" SG_ 1354 RLR_NMWakeupOrigin "此信号恒定为：0x00";
BA_ "EventCommandSignal" SG_ 1354 RLR_PNCInformation0 0;
BA_ "GatewayedSignals" SG_ 1354 RLR_PNCInformation0 0;
BA_ "GenSigInactiveValue" SG_ 1354 RLR_PNCInformation0 0;
BA_ "GenSigInvalidValue" SG_ 1354 RLR_PNCInformation0 0;
BA_ "GenSigSendType" SG_ 1354 RLR_PNCInformation0 1;
BA_ "GenSigStartValue" SG_ 1354 RLR_PNCInformation0 0;
BA_ "GenSigTimeoutValue" SG_ 1354 RLR_PNCInformation0 0;
BA_ "Remark" SG_ 1354 RLR_PNCInformation0 "此信号恒定为：0x01";
BA_ "EventCommandSignal" SG_ 1354 RLR_PNCInformation1 0;
BA_ "GatewayedSignals" SG_ 1354 RLR_PNCInformation1 0;
BA_ "GenSigInactiveValue" SG_ 1354 RLR_PNCInformation1 0;
BA_ "GenSigInvalidValue" SG_ 1354 RLR_PNCInformation1 0;
BA_ "GenSigSendType" SG_ 1354 RLR_PNCInformation1 1;
BA_ "GenSigStartValue" SG_ 1354 RLR_PNCInformation1 0;
BA_ "GenSigTimeoutValue" SG_ 1354 RLR_PNCInformation1 0;
BA_ "Remark" SG_ 1354 RLR_PNCInformation1 "此信号恒定为：0x00000000";
BA_ "EventCommandSignal" SG_ 1354 RLR_PNCInformation2 0;
BA_ "GatewayedSignals" SG_ 1354 RLR_PNCInformation2 0;
BA_ "GenSigInactiveValue" SG_ 1354 RLR_PNCInformation2 0;
BA_ "GenSigInvalidValue" SG_ 1354 RLR_PNCInformation2 0;
BA_ "GenSigSendType" SG_ 1354 RLR_PNCInformation2 1;
BA_ "GenSigStartValue" SG_ 1354 RLR_PNCInformation2 0;
BA_ "GenSigTimeoutValue" SG_ 1354 RLR_PNCInformation2 0;
BA_ "Remark" SG_ 1354 RLR_PNCInformation2 "此信号恒定为：0x00000000";
BA_ "EventCommandSignal" SG_ 987 RLR_1_CRC 0;
BA_ "GatewayedSignals" SG_ 987 RLR_1_CRC 0;
BA_ "GenSigInactiveValue" SG_ 987 RLR_1_CRC 0;
BA_ "GenSigInvalidValue" SG_ 987 RLR_1_CRC 0;
BA_ "GenSigSendType" SG_ 987 RLR_1_CRC 1;
BA_ "GenSigStartValue" SG_ 987 RLR_1_CRC 0;
BA_ "GenSigTimeoutValue" SG_ 987 RLR_1_CRC 0;
BA_ "Remark" SG_ 987 RLR_1_CRC "";
BA_ "EventCommandSignal" SG_ 987 RLR_1_Counter 0;
BA_ "GatewayedSignals" SG_ 987 RLR_1_Counter 0;
BA_ "GenSigInactiveValue" SG_ 987 RLR_1_Counter 0;
BA_ "GenSigInvalidValue" SG_ 987 RLR_1_Counter 0;
BA_ "GenSigSendType" SG_ 987 RLR_1_Counter 1;
BA_ "GenSigStartValue" SG_ 987 RLR_1_Counter 0;
BA_ "GenSigTimeoutValue" SG_ 987 RLR_1_Counter 0;
BA_ "Remark" SG_ 987 RLR_1_Counter "";
BA_ "EventCommandSignal" SG_ 987 RLR_MRRSt 0;
BA_ "GatewayedSignals" SG_ 987 RLR_MRRSt 0;
BA_ "GenSigInactiveValue" SG_ 987 RLR_MRRSt 0;
BA_ "GenSigInvalidValue" SG_ 987 RLR_MRRSt 0;
BA_ "GenSigSendType" SG_ 987 RLR_MRRSt 1;
BA_ "GenSigStartValue" SG_ 987 RLR_MRRSt 0;
BA_ "GenSigTimeoutValue" SG_ 987 RLR_MRRSt 2;
BA_ "Remark" SG_ 987 RLR_MRRSt "";
BA_ "EventCommandSignal" SG_ 987 RLR_ExMirLedWarnL 0;
BA_ "GatewayedSignals" SG_ 987 RLR_ExMirLedWarnL 0;
BA_ "GenSigInactiveValue" SG_ 987 RLR_ExMirLedWarnL 0;
BA_ "GenSigInvalidValue" SG_ 987 RLR_ExMirLedWarnL 0;
BA_ "GenSigSendType" SG_ 987 RLR_ExMirLedWarnL 1;
BA_ "GenSigStartValue" SG_ 987 RLR_ExMirLedWarnL 0;
BA_ "GenSigTimeoutValue" SG_ 987 RLR_ExMirLedWarnL 0;
BA_ "Remark" SG_ 987 RLR_ExMirLedWarnL "";
BA_ "EventCommandSignal" SG_ 987 RLR_LCASt 0;
BA_ "GatewayedSignals" SG_ 987 RLR_LCASt 0;
BA_ "GenSigInactiveValue" SG_ 987 RLR_LCASt 0;
BA_ "GenSigInvalidValue" SG_ 987 RLR_LCASt 0;
BA_ "GenSigSendType" SG_ 987 RLR_LCASt 1;
BA_ "GenSigStartValue" SG_ 987 RLR_LCASt 0;
BA_ "GenSigTimeoutValue" SG_ 987 RLR_LCASt 3;
BA_ "Remark" SG_ 987 RLR_LCASt "";
BA_ "EventCommandSignal" SG_ 987 RLR_LCAWarnLeft 0;
BA_ "GatewayedSignals" SG_ 987 RLR_LCAWarnLeft 0;
BA_ "GenSigInactiveValue" SG_ 987 RLR_LCAWarnLeft 0;
BA_ "GenSigInvalidValue" SG_ 987 RLR_LCAWarnLeft 0;
BA_ "GenSigSendType" SG_ 987 RLR_LCAWarnLeft 1;
BA_ "GenSigStartValue" SG_ 987 RLR_LCAWarnLeft 0;
BA_ "GenSigTimeoutValue" SG_ 987 RLR_LCAWarnLeft 0;
BA_ "Remark" SG_ 987 RLR_LCAWarnLeft "";
BA_ "EventCommandSignal" SG_ 987 RLR_ClusterLamp 0;
BA_ "GatewayedSignals" SG_ 987 RLR_ClusterLamp 0;
BA_ "GenSigInactiveValue" SG_ 987 RLR_ClusterLamp 0;
BA_ "GenSigInvalidValue" SG_ 987 RLR_ClusterLamp 0;
BA_ "GenSigSendType" SG_ 987 RLR_ClusterLamp 1;
BA_ "GenSigStartValue" SG_ 987 RLR_ClusterLamp 0;
BA_ "GenSigTimeoutValue" SG_ 987 RLR_ClusterLamp 1;
BA_ "Remark" SG_ 987 RLR_ClusterLamp "";
BA_ "EventCommandSignal" SG_ 987 RLR_DOWWarnL 0;
BA_ "GatewayedSignals" SG_ 987 RLR_DOWWarnL 0;
BA_ "GenSigInactiveValue" SG_ 987 RLR_DOWWarnL 0;
BA_ "GenSigInvalidValue" SG_ 987 RLR_DOWWarnL 0;
BA_ "GenSigSendType" SG_ 987 RLR_DOWWarnL 1;
BA_ "GenSigStartValue" SG_ 987 RLR_DOWWarnL 0;
BA_ "GenSigTimeoutValue" SG_ 987 RLR_DOWWarnL 0;
BA_ "Remark" SG_ 987 RLR_DOWWarnL "";
BA_ "EventCommandSignal" SG_ 987 RLR_DOWSt 0;
BA_ "GatewayedSignals" SG_ 987 RLR_DOWSt 0;
BA_ "GenSigInactiveValue" SG_ 987 RLR_DOWSt 0;
BA_ "GenSigInvalidValue" SG_ 987 RLR_DOWSt 0;
BA_ "GenSigSendType" SG_ 987 RLR_DOWSt 1;
BA_ "GenSigStartValue" SG_ 987 RLR_DOWSt 0;
BA_ "GenSigTimeoutValue" SG_ 987 RLR_DOWSt 0;
BA_ "Remark" SG_ 987 RLR_DOWSt "";
BA_ "EventCommandSignal" SG_ 987 RLR_AudioWarnFL 0;
BA_ "GatewayedSignals" SG_ 987 RLR_AudioWarnFL 0;
BA_ "GenSigInactiveValue" SG_ 987 RLR_AudioWarnFL 0;
BA_ "GenSigInvalidValue" SG_ 987 RLR_AudioWarnFL 0;
BA_ "GenSigSendType" SG_ 987 RLR_AudioWarnFL 1;
BA_ "GenSigStartValue" SG_ 987 RLR_AudioWarnFL 0;
BA_ "GenSigTimeoutValue" SG_ 987 RLR_AudioWarnFL 0;
BA_ "Remark" SG_ 987 RLR_AudioWarnFL "";
BA_ "EventCommandSignal" SG_ 987 RLR_AudioWarnRL 0;
BA_ "GatewayedSignals" SG_ 987 RLR_AudioWarnRL 0;
BA_ "GenSigInactiveValue" SG_ 987 RLR_AudioWarnRL 0;
BA_ "GenSigInvalidValue" SG_ 987 RLR_AudioWarnRL 0;
BA_ "GenSigSendType" SG_ 987 RLR_AudioWarnRL 1;
BA_ "GenSigStartValue" SG_ 987 RLR_AudioWarnRL 0;
BA_ "GenSigTimeoutValue" SG_ 987 RLR_AudioWarnRL 0;
BA_ "Remark" SG_ 987 RLR_AudioWarnRL "";
BA_ "EventCommandSignal" SG_ 987 RLR_IALWarnFL 0;
BA_ "GatewayedSignals" SG_ 987 RLR_IALWarnFL 0;
BA_ "GenSigInactiveValue" SG_ 987 RLR_IALWarnFL 0;
BA_ "GenSigInvalidValue" SG_ 987 RLR_IALWarnFL 0;
BA_ "GenSigSendType" SG_ 987 RLR_IALWarnFL 1;
BA_ "GenSigStartValue" SG_ 987 RLR_IALWarnFL 0;
BA_ "GenSigTimeoutValue" SG_ 987 RLR_IALWarnFL 0;
BA_ "Remark" SG_ 987 RLR_IALWarnFL "";
BA_ "EventCommandSignal" SG_ 987 RLR_IALWarnRL 0;
BA_ "GatewayedSignals" SG_ 987 RLR_IALWarnRL 0;
BA_ "GenSigInactiveValue" SG_ 987 RLR_IALWarnRL 0;
BA_ "GenSigInvalidValue" SG_ 987 RLR_IALWarnRL 0;
BA_ "GenSigSendType" SG_ 987 RLR_IALWarnRL 1;
BA_ "GenSigStartValue" SG_ 987 RLR_IALWarnRL 0;
BA_ "GenSigTimeoutValue" SG_ 987 RLR_IALWarnRL 0;
BA_ "Remark" SG_ 987 RLR_IALWarnRL "";
BA_ "EventCommandSignal" SG_ 987 RLR_RCTAWarnLeft 0;
BA_ "GatewayedSignals" SG_ 987 RLR_RCTAWarnLeft 0;
BA_ "GenSigInactiveValue" SG_ 987 RLR_RCTAWarnLeft 0;
BA_ "GenSigInvalidValue" SG_ 987 RLR_RCTAWarnLeft 0;
BA_ "GenSigSendType" SG_ 987 RLR_RCTAWarnLeft 1;
BA_ "GenSigStartValue" SG_ 987 RLR_RCTAWarnLeft 0;
BA_ "GenSigTimeoutValue" SG_ 987 RLR_RCTAWarnLeft 0;
BA_ "Remark" SG_ 987 RLR_RCTAWarnLeft "";
BA_ "EventCommandSignal" SG_ 987 RLR_RCWSt 0;
BA_ "GatewayedSignals" SG_ 987 RLR_RCWSt 0;
BA_ "GenSigInactiveValue" SG_ 987 RLR_RCWSt 0;
BA_ "GenSigInvalidValue" SG_ 987 RLR_RCWSt 0;
BA_ "GenSigSendType" SG_ 987 RLR_RCWSt 1;
BA_ "GenSigStartValue" SG_ 987 RLR_RCWSt 0;
BA_ "GenSigTimeoutValue" SG_ 987 RLR_RCWSt 0;
BA_ "Remark" SG_ 987 RLR_RCWSt "";
BA_ "EventCommandSignal" SG_ 987 RLR_RCWWarn 0;
BA_ "GatewayedSignals" SG_ 987 RLR_RCWWarn 0;
BA_ "GenSigInactiveValue" SG_ 987 RLR_RCWWarn 0;
BA_ "GenSigInvalidValue" SG_ 987 RLR_RCWWarn 0;
BA_ "GenSigSendType" SG_ 987 RLR_RCWWarn 1;
BA_ "GenSigStartValue" SG_ 987 RLR_RCWWarn 0;
BA_ "GenSigTimeoutValue" SG_ 987 RLR_RCWWarn 0;
BA_ "Remark" SG_ 987 RLR_RCWWarn "";
BA_ "EventCommandSignal" SG_ 987 RLR_TargetLVD 0;
BA_ "GatewayedSignals" SG_ 987 RLR_TargetLVD 0;
BA_ "GenSigInactiveValue" SG_ 987 RLR_TargetLVD 0;
BA_ "GenSigInvalidValue" SG_ 987 RLR_TargetLVD 0;
BA_ "GenSigSendType" SG_ 987 RLR_TargetLVD 1;
BA_ "GenSigStartValue" SG_ 987 RLR_TargetLVD 0;
BA_ "GenSigTimeoutValue" SG_ 987 RLR_TargetLVD 0;
BA_ "Remark" SG_ 987 RLR_TargetLVD "";
BA_ "EventCommandSignal" SG_ 987 RLR_TargetRelSpdL 0;
BA_ "GatewayedSignals" SG_ 987 RLR_TargetRelSpdL 0;
BA_ "GenSigInactiveValue" SG_ 987 RLR_TargetRelSpdL 0;
BA_ "GenSigInvalidValue" SG_ 987 RLR_TargetRelSpdL 0;
BA_ "GenSigSendType" SG_ 987 RLR_TargetRelSpdL 1;
BA_ "GenSigStartValue" SG_ 987 RLR_TargetRelSpdL 0;
BA_ "GenSigTimeoutValue" SG_ 987 RLR_TargetRelSpdL 0;
BA_ "Remark" SG_ 987 RLR_TargetRelSpdL "";
BA_ "EventCommandSignal" SG_ 987 RLR_TargetDstL 0;
BA_ "GatewayedSignals" SG_ 987 RLR_TargetDstL 0;
BA_ "GenSigInactiveValue" SG_ 987 RLR_TargetDstL 0;
BA_ "GenSigInvalidValue" SG_ 987 RLR_TargetDstL 0;
BA_ "GenSigSendType" SG_ 987 RLR_TargetDstL 1;
BA_ "GenSigStartValue" SG_ 987 RLR_TargetDstL 0;
BA_ "GenSigTimeoutValue" SG_ 987 RLR_TargetDstL 0;
BA_ "Remark" SG_ 987 RLR_TargetDstL "";
BA_ "EventCommandSignal" SG_ 987 RLR_TargetLatDistL 0;
BA_ "GatewayedSignals" SG_ 987 RLR_TargetLatDistL 0;
BA_ "GenSigInactiveValue" SG_ 987 RLR_TargetLatDistL 0;
BA_ "GenSigInvalidValue" SG_ 987 RLR_TargetLatDistL 0;
BA_ "GenSigSendType" SG_ 987 RLR_TargetLatDistL 1;
BA_ "GenSigStartValue" SG_ 987 RLR_TargetLatDistL 0;
BA_ "GenSigTimeoutValue" SG_ 987 RLR_TargetLatDistL 0;
BA_ "Remark" SG_ 987 RLR_TargetLatDistL "";
BA_ "EventCommandSignal" SG_ 987 RLR_RCTASt 0;
BA_ "GatewayedSignals" SG_ 987 RLR_RCTASt 0;
BA_ "GenSigInactiveValue" SG_ 987 RLR_RCTASt 0;
BA_ "GenSigInvalidValue" SG_ 987 RLR_RCTASt 0;
BA_ "GenSigSendType" SG_ 987 RLR_RCTASt 1;
BA_ "GenSigStartValue" SG_ 987 RLR_RCTASt 0;
BA_ "GenSigTimeoutValue" SG_ 987 RLR_RCTASt 0;
BA_ "Remark" SG_ 987 RLR_RCTASt "";
BA_ "EventCommandSignal" SG_ 987 RLR_RCTAAssistType 0;
BA_ "GatewayedSignals" SG_ 987 RLR_RCTAAssistType 0;
BA_ "GenSigInactiveValue" SG_ 987 RLR_RCTAAssistType 0;
BA_ "GenSigInvalidValue" SG_ 987 RLR_RCTAAssistType 0;
BA_ "GenSigSendType" SG_ 987 RLR_RCTAAssistType 1;
BA_ "GenSigStartValue" SG_ 987 RLR_RCTAAssistType 0;
BA_ "GenSigTimeoutValue" SG_ 987 RLR_RCTAAssistType 0;
BA_ "Remark" SG_ 987 RLR_RCTAAssistType "";
BA_ "EventCommandSignal" SG_ 1343 RRR_NMNodeAddress 0;
BA_ "GatewayedSignals" SG_ 1343 RRR_NMNodeAddress 0;
BA_ "GenSigInactiveValue" SG_ 1343 RRR_NMNodeAddress 0;
BA_ "GenSigInvalidValue" SG_ 1343 RRR_NMNodeAddress 0;
BA_ "GenSigSendType" SG_ 1343 RRR_NMNodeAddress 1;
BA_ "GenSigStartValue" SG_ 1343 RRR_NMNodeAddress 63;
BA_ "GenSigTimeoutValue" SG_ 1343 RRR_NMNodeAddress 0;
BA_ "Remark" SG_ 1343 RRR_NMNodeAddress "此信号恒定为：0x3F";
BA_ "EventCommandSignal" SG_ 1343 RRR_NMCBV 0;
BA_ "GatewayedSignals" SG_ 1343 RRR_NMCBV 0;
BA_ "GenSigInactiveValue" SG_ 1343 RRR_NMCBV 0;
BA_ "GenSigInvalidValue" SG_ 1343 RRR_NMCBV 0;
BA_ "GenSigSendType" SG_ 1343 RRR_NMCBV 1;
BA_ "GenSigStartValue" SG_ 1343 RRR_NMCBV 0;
BA_ "GenSigTimeoutValue" SG_ 1343 RRR_NMCBV 0;
BA_ "Remark" SG_ 1343 RRR_NMCBV "此信号恒定为：0x50";
BA_ "EventCommandSignal" SG_ 1343 RRR_NMWakeupOrigin 0;
BA_ "GatewayedSignals" SG_ 1343 RRR_NMWakeupOrigin 0;
BA_ "GenSigInactiveValue" SG_ 1343 RRR_NMWakeupOrigin 0;
BA_ "GenSigInvalidValue" SG_ 1343 RRR_NMWakeupOrigin 0;
BA_ "GenSigSendType" SG_ 1343 RRR_NMWakeupOrigin 1;
BA_ "GenSigStartValue" SG_ 1343 RRR_NMWakeupOrigin 0;
BA_ "GenSigTimeoutValue" SG_ 1343 RRR_NMWakeupOrigin 0;
BA_ "Remark" SG_ 1343 RRR_NMWakeupOrigin "此信号恒定为：0x00";
BA_ "EventCommandSignal" SG_ 1343 RRR_PNCInformation0 0;
BA_ "GatewayedSignals" SG_ 1343 RRR_PNCInformation0 0;
BA_ "GenSigInactiveValue" SG_ 1343 RRR_PNCInformation0 0;
BA_ "GenSigInvalidValue" SG_ 1343 RRR_PNCInformation0 0;
BA_ "GenSigSendType" SG_ 1343 RRR_PNCInformation0 1;
BA_ "GenSigStartValue" SG_ 1343 RRR_PNCInformation0 0;
BA_ "GenSigTimeoutValue" SG_ 1343 RRR_PNCInformation0 0;
BA_ "Remark" SG_ 1343 RRR_PNCInformation0 "此信号恒定为：0x01";
BA_ "EventCommandSignal" SG_ 1343 RRR_PNCInformation1 0;
BA_ "GatewayedSignals" SG_ 1343 RRR_PNCInformation1 0;
BA_ "GenSigInactiveValue" SG_ 1343 RRR_PNCInformation1 0;
BA_ "GenSigInvalidValue" SG_ 1343 RRR_PNCInformation1 0;
BA_ "GenSigSendType" SG_ 1343 RRR_PNCInformation1 1;
BA_ "GenSigStartValue" SG_ 1343 RRR_PNCInformation1 0;
BA_ "GenSigTimeoutValue" SG_ 1343 RRR_PNCInformation1 0;
BA_ "Remark" SG_ 1343 RRR_PNCInformation1 "此信号恒定为：0x00000000";
BA_ "EventCommandSignal" SG_ 1343 RRR_PNCInformation2 0;
BA_ "GatewayedSignals" SG_ 1343 RRR_PNCInformation2 0;
BA_ "GenSigInactiveValue" SG_ 1343 RRR_PNCInformation2 0;
BA_ "GenSigInvalidValue" SG_ 1343 RRR_PNCInformation2 0;
BA_ "GenSigSendType" SG_ 1343 RRR_PNCInformation2 1;
BA_ "GenSigStartValue" SG_ 1343 RRR_PNCInformation2 0;
BA_ "GenSigTimeoutValue" SG_ 1343 RRR_PNCInformation2 0;
BA_ "Remark" SG_ 1343 RRR_PNCInformation2 "此信号恒定为：0x00000000";
BA_ "EventCommandSignal" SG_ 932 RRR_1_CRC 0;
BA_ "GatewayedSignals" SG_ 932 RRR_1_CRC 0;
BA_ "GenSigInactiveValue" SG_ 932 RRR_1_CRC 0;
BA_ "GenSigInvalidValue" SG_ 932 RRR_1_CRC 0;
BA_ "GenSigSendType" SG_ 932 RRR_1_CRC 1;
BA_ "GenSigStartValue" SG_ 932 RRR_1_CRC 0;
BA_ "GenSigTimeoutValue" SG_ 932 RRR_1_CRC 0;
BA_ "Remark" SG_ 932 RRR_1_CRC "";
BA_ "EventCommandSignal" SG_ 932 RRR_1_Counter 0;
BA_ "GatewayedSignals" SG_ 932 RRR_1_Counter 0;
BA_ "GenSigInactiveValue" SG_ 932 RRR_1_Counter 0;
BA_ "GenSigInvalidValue" SG_ 932 RRR_1_Counter 0;
BA_ "GenSigSendType" SG_ 932 RRR_1_Counter 1;
BA_ "GenSigStartValue" SG_ 932 RRR_1_Counter 0;
BA_ "GenSigTimeoutValue" SG_ 932 RRR_1_Counter 0;
BA_ "Remark" SG_ 932 RRR_1_Counter "";
BA_ "EventCommandSignal" SG_ 932 RRR_MRRSt 0;
BA_ "GatewayedSignals" SG_ 932 RRR_MRRSt 0;
BA_ "GenSigInactiveValue" SG_ 932 RRR_MRRSt 0;
BA_ "GenSigInvalidValue" SG_ 932 RRR_MRRSt 0;
BA_ "GenSigSendType" SG_ 932 RRR_MRRSt 1;
BA_ "GenSigStartValue" SG_ 932 RRR_MRRSt 0;
BA_ "GenSigTimeoutValue" SG_ 932 RRR_MRRSt 2;
BA_ "Remark" SG_ 932 RRR_MRRSt "";
BA_ "EventCommandSignal" SG_ 932 RRR_ExMirLedWarnR 0;
BA_ "GatewayedSignals" SG_ 932 RRR_ExMirLedWarnR 0;
BA_ "GenSigInactiveValue" SG_ 932 RRR_ExMirLedWarnR 0;
BA_ "GenSigInvalidValue" SG_ 932 RRR_ExMirLedWarnR 0;
BA_ "GenSigSendType" SG_ 932 RRR_ExMirLedWarnR 1;
BA_ "GenSigStartValue" SG_ 932 RRR_ExMirLedWarnR 0;
BA_ "GenSigTimeoutValue" SG_ 932 RRR_ExMirLedWarnR 0;
BA_ "Remark" SG_ 932 RRR_ExMirLedWarnR "";
BA_ "EventCommandSignal" SG_ 932 RRR_LCASt 0;
BA_ "GatewayedSignals" SG_ 932 RRR_LCASt 0;
BA_ "GenSigInactiveValue" SG_ 932 RRR_LCASt 0;
BA_ "GenSigInvalidValue" SG_ 932 RRR_LCASt 0;
BA_ "GenSigSendType" SG_ 932 RRR_LCASt 1;
BA_ "GenSigStartValue" SG_ 932 RRR_LCASt 0;
BA_ "GenSigTimeoutValue" SG_ 932 RRR_LCASt 3;
BA_ "Remark" SG_ 932 RRR_LCASt "";
BA_ "EventCommandSignal" SG_ 932 RRR_LCAWarnRight 0;
BA_ "GatewayedSignals" SG_ 932 RRR_LCAWarnRight 0;
BA_ "GenSigInactiveValue" SG_ 932 RRR_LCAWarnRight 0;
BA_ "GenSigInvalidValue" SG_ 932 RRR_LCAWarnRight 0;
BA_ "GenSigSendType" SG_ 932 RRR_LCAWarnRight 1;
BA_ "GenSigStartValue" SG_ 932 RRR_LCAWarnRight 0;
BA_ "GenSigTimeoutValue" SG_ 932 RRR_LCAWarnRight 0;
BA_ "Remark" SG_ 932 RRR_LCAWarnRight "";
BA_ "EventCommandSignal" SG_ 932 RRR_ClusterLamp 0;
BA_ "GatewayedSignals" SG_ 932 RRR_ClusterLamp 0;
BA_ "GenSigInactiveValue" SG_ 932 RRR_ClusterLamp 0;
BA_ "GenSigInvalidValue" SG_ 932 RRR_ClusterLamp 0;
BA_ "GenSigSendType" SG_ 932 RRR_ClusterLamp 1;
BA_ "GenSigStartValue" SG_ 932 RRR_ClusterLamp 0;
BA_ "GenSigTimeoutValue" SG_ 932 RRR_ClusterLamp 1;
BA_ "Remark" SG_ 932 RRR_ClusterLamp "";
BA_ "EventCommandSignal" SG_ 932 RRR_DOWWarnR 0;
BA_ "GatewayedSignals" SG_ 932 RRR_DOWWarnR 0;
BA_ "GenSigInactiveValue" SG_ 932 RRR_DOWWarnR 0;
BA_ "GenSigInvalidValue" SG_ 932 RRR_DOWWarnR 0;
BA_ "GenSigSendType" SG_ 932 RRR_DOWWarnR 1;
BA_ "GenSigStartValue" SG_ 932 RRR_DOWWarnR 0;
BA_ "GenSigTimeoutValue" SG_ 932 RRR_DOWWarnR 0;
BA_ "Remark" SG_ 932 RRR_DOWWarnR "";
BA_ "EventCommandSignal" SG_ 932 RRR_DOWSt 0;
BA_ "GatewayedSignals" SG_ 932 RRR_DOWSt 0;
BA_ "GenSigInactiveValue" SG_ 932 RRR_DOWSt 0;
BA_ "GenSigInvalidValue" SG_ 932 RRR_DOWSt 0;
BA_ "GenSigSendType" SG_ 932 RRR_DOWSt 1;
BA_ "GenSigStartValue" SG_ 932 RRR_DOWSt 0;
BA_ "GenSigTimeoutValue" SG_ 932 RRR_DOWSt 0;
BA_ "Remark" SG_ 932 RRR_DOWSt "";
BA_ "EventCommandSignal" SG_ 932 RRR_AudioWarnFR 0;
BA_ "GatewayedSignals" SG_ 932 RRR_AudioWarnFR 0;
BA_ "GenSigInactiveValue" SG_ 932 RRR_AudioWarnFR 0;
BA_ "GenSigInvalidValue" SG_ 932 RRR_AudioWarnFR 0;
BA_ "GenSigSendType" SG_ 932 RRR_AudioWarnFR 1;
BA_ "GenSigStartValue" SG_ 932 RRR_AudioWarnFR 0;
BA_ "GenSigTimeoutValue" SG_ 932 RRR_AudioWarnFR 0;
BA_ "Remark" SG_ 932 RRR_AudioWarnFR "";
BA_ "EventCommandSignal" SG_ 932 RRR_AudioWarnRR 0;
BA_ "GatewayedSignals" SG_ 932 RRR_AudioWarnRR 0;
BA_ "GenSigInactiveValue" SG_ 932 RRR_AudioWarnRR 0;
BA_ "GenSigInvalidValue" SG_ 932 RRR_AudioWarnRR 0;
BA_ "GenSigSendType" SG_ 932 RRR_AudioWarnRR 1;
BA_ "GenSigStartValue" SG_ 932 RRR_AudioWarnRR 0;
BA_ "GenSigTimeoutValue" SG_ 932 RRR_AudioWarnRR 0;
BA_ "Remark" SG_ 932 RRR_AudioWarnRR "";
BA_ "EventCommandSignal" SG_ 932 RRR_IALWarnFR 0;
BA_ "GatewayedSignals" SG_ 932 RRR_IALWarnFR 0;
BA_ "GenSigInactiveValue" SG_ 932 RRR_IALWarnFR 0;
BA_ "GenSigInvalidValue" SG_ 932 RRR_IALWarnFR 0;
BA_ "GenSigSendType" SG_ 932 RRR_IALWarnFR 1;
BA_ "GenSigStartValue" SG_ 932 RRR_IALWarnFR 0;
BA_ "GenSigTimeoutValue" SG_ 932 RRR_IALWarnFR 0;
BA_ "Remark" SG_ 932 RRR_IALWarnFR "";
BA_ "EventCommandSignal" SG_ 932 RRR_IALWarnRR 0;
BA_ "GatewayedSignals" SG_ 932 RRR_IALWarnRR 0;
BA_ "GenSigInactiveValue" SG_ 932 RRR_IALWarnRR 0;
BA_ "GenSigInvalidValue" SG_ 932 RRR_IALWarnRR 0;
BA_ "GenSigSendType" SG_ 932 RRR_IALWarnRR 1;
BA_ "GenSigStartValue" SG_ 932 RRR_IALWarnRR 0;
BA_ "GenSigTimeoutValue" SG_ 932 RRR_IALWarnRR 0;
BA_ "Remark" SG_ 932 RRR_IALWarnRR "";
BA_ "EventCommandSignal" SG_ 932 RRR_RCTASt 0;
BA_ "GatewayedSignals" SG_ 932 RRR_RCTASt 0;
BA_ "GenSigInactiveValue" SG_ 932 RRR_RCTASt 0;
BA_ "GenSigInvalidValue" SG_ 932 RRR_RCTASt 0;
BA_ "GenSigSendType" SG_ 932 RRR_RCTASt 1;
BA_ "GenSigStartValue" SG_ 932 RRR_RCTASt 0;
BA_ "EventCommandSignal" SG_ 932 RRR_RCTAWarnRight 0;
BA_ "GatewayedSignals" SG_ 932 RRR_RCTAWarnRight 0;
BA_ "GenSigInactiveValue" SG_ 932 RRR_RCTAWarnRight 0;
BA_ "GenSigInvalidValue" SG_ 932 RRR_RCTAWarnRight 0;
BA_ "GenSigSendType" SG_ 932 RRR_RCTAWarnRight 1;
BA_ "GenSigStartValue" SG_ 932 RRR_RCTAWarnRight 0;
BA_ "GenSigTimeoutValue" SG_ 932 RRR_RCTAWarnRight 0;
BA_ "Remark" SG_ 932 RRR_RCTAWarnRight "";
BA_ "EventCommandSignal" SG_ 932 RRR_RCWSt 0;
BA_ "GatewayedSignals" SG_ 932 RRR_RCWSt 0;
BA_ "GenSigInactiveValue" SG_ 932 RRR_RCWSt 0;
BA_ "GenSigInvalidValue" SG_ 932 RRR_RCWSt 0;
BA_ "GenSigSendType" SG_ 932 RRR_RCWSt 1;
BA_ "GenSigStartValue" SG_ 932 RRR_RCWSt 0;
BA_ "GenSigTimeoutValue" SG_ 932 RRR_RCWSt 3;
BA_ "Remark" SG_ 932 RRR_RCWSt "";
BA_ "EventCommandSignal" SG_ 932 RRR_RCWWarn 0;
BA_ "GatewayedSignals" SG_ 932 RRR_RCWWarn 0;
BA_ "GenSigInactiveValue" SG_ 932 RRR_RCWWarn 0;
BA_ "GenSigInvalidValue" SG_ 932 RRR_RCWWarn 0;
BA_ "GenSigSendType" SG_ 932 RRR_RCWWarn 1;
BA_ "GenSigStartValue" SG_ 932 RRR_RCWWarn 0;
BA_ "GenSigTimeoutValue" SG_ 932 RRR_RCWWarn 0;
BA_ "Remark" SG_ 932 RRR_RCWWarn "";
BA_ "EventCommandSignal" SG_ 932 RRR_RCTBTargetDecel 0;
BA_ "GatewayedSignals" SG_ 932 RRR_RCTBTargetDecel 0;
BA_ "GenSigInactiveValue" SG_ 932 RRR_RCTBTargetDecel 0;
BA_ "GenSigInvalidValue" SG_ 932 RRR_RCTBTargetDecel 0;
BA_ "GenSigSendType" SG_ 932 RRR_RCTBTargetDecel 1;
BA_ "GenSigStartValue" SG_ 932 RRR_RCTBTargetDecel 0;
BA_ "GenSigTimeoutValue" SG_ 932 RRR_RCTBTargetDecel 0;
BA_ "Remark" SG_ 932 RRR_RCTBTargetDecel "";
BA_ "EventCommandSignal" SG_ 932 RRR_RCTBBrkReq 0;
BA_ "GatewayedSignals" SG_ 932 RRR_RCTBBrkReq 0;
BA_ "GenSigInactiveValue" SG_ 932 RRR_RCTBBrkReq 0;
BA_ "GenSigInvalidValue" SG_ 932 RRR_RCTBBrkReq 0;
BA_ "GenSigSendType" SG_ 932 RRR_RCTBBrkReq 1;
BA_ "GenSigStartValue" SG_ 932 RRR_RCTBBrkReq 0;
BA_ "GenSigTimeoutValue" SG_ 932 RRR_RCTBBrkReq 0;
BA_ "Remark" SG_ 932 RRR_RCTBBrkReq "";
BA_ "EventCommandSignal" SG_ 932 RRR_TargetLatDistR 0;
BA_ "GatewayedSignals" SG_ 932 RRR_TargetLatDistR 0;
BA_ "GenSigInactiveValue" SG_ 932 RRR_TargetLatDistR 0;
BA_ "GenSigInvalidValue" SG_ 932 RRR_TargetLatDistR 0;
BA_ "GenSigSendType" SG_ 932 RRR_TargetLatDistR 1;
BA_ "GenSigStartValue" SG_ 932 RRR_TargetLatDistR 0;
BA_ "GenSigTimeoutValue" SG_ 932 RRR_TargetLatDistR 0;
BA_ "Remark" SG_ 932 RRR_TargetLatDistR "";
BA_ "EventCommandSignal" SG_ 932 RRR_TargetRelSpdR 0;
BA_ "GatewayedSignals" SG_ 932 RRR_TargetRelSpdR 0;
BA_ "GenSigInactiveValue" SG_ 932 RRR_TargetRelSpdR 0;
BA_ "GenSigInvalidValue" SG_ 932 RRR_TargetRelSpdR 0;
BA_ "GenSigSendType" SG_ 932 RRR_TargetRelSpdR 1;
BA_ "GenSigStartValue" SG_ 932 RRR_TargetRelSpdR 0;
BA_ "GenSigTimeoutValue" SG_ 932 RRR_TargetRelSpdR 0;
BA_ "Remark" SG_ 932 RRR_TargetRelSpdR "";
BA_ "EventCommandSignal" SG_ 932 RRR_RCTBBrkgVD 0;
BA_ "GatewayedSignals" SG_ 932 RRR_RCTBBrkgVD 0;
BA_ "GenSigInactiveValue" SG_ 932 RRR_RCTBBrkgVD 0;
BA_ "GenSigInvalidValue" SG_ 932 RRR_RCTBBrkgVD 0;
BA_ "GenSigSendType" SG_ 932 RRR_RCTBBrkgVD 1;
BA_ "GenSigStartValue" SG_ 932 RRR_RCTBBrkgVD 0;
BA_ "GenSigTimeoutValue" SG_ 932 RRR_RCTBBrkgVD 1;
BA_ "Remark" SG_ 932 RRR_RCTBBrkgVD "";
BA_ "EventCommandSignal" SG_ 932 RRR_TargetRVD 0;
BA_ "GatewayedSignals" SG_ 932 RRR_TargetRVD 0;
BA_ "GenSigInactiveValue" SG_ 932 RRR_TargetRVD 0;
BA_ "GenSigInvalidValue" SG_ 932 RRR_TargetRVD 0;
BA_ "GenSigSendType" SG_ 932 RRR_TargetRVD 1;
BA_ "GenSigStartValue" SG_ 932 RRR_TargetRVD 0;
BA_ "GenSigTimeoutValue" SG_ 932 RRR_TargetRVD 0;
BA_ "Remark" SG_ 932 RRR_TargetRVD "";
BA_ "EventCommandSignal" SG_ 932 RRR_TargetDstR 0;
BA_ "GatewayedSignals" SG_ 932 RRR_TargetDstR 0;
BA_ "GenSigInactiveValue" SG_ 932 RRR_TargetDstR 0;
BA_ "GenSigInvalidValue" SG_ 932 RRR_TargetDstR 0;
BA_ "GenSigSendType" SG_ 932 RRR_TargetDstR 1;
BA_ "GenSigStartValue" SG_ 932 RRR_TargetDstR 0;
BA_ "GenSigTimeoutValue" SG_ 932 RRR_TargetDstR 0;
BA_ "Remark" SG_ 932 RRR_TargetDstR "";
BA_ "EventCommandSignal" SG_ 932 RRR_RCTAAssistType 0;
BA_ "GatewayedSignals" SG_ 932 RRR_RCTAAssistType 0;
BA_ "GenSigInactiveValue" SG_ 932 RRR_RCTAAssistType 0;
BA_ "GenSigInvalidValue" SG_ 932 RRR_RCTAAssistType 0;
BA_ "GenSigSendType" SG_ 932 RRR_RCTAAssistType 1;
BA_ "GenSigStartValue" SG_ 932 RRR_RCTAAssistType 0;
BA_ "GenSigTimeoutValue" SG_ 932 RRR_RCTAAssistType 0;
BA_ "Remark" SG_ 932 RRR_RCTAAssistType "";
BA_ "EventCommandSignal" SG_ 620 CCU_PADS_2_CRC 0;
BA_ "GatewayedSignals" SG_ 620 CCU_PADS_2_CRC 0;
BA_ "GenSigInactiveValue" SG_ 620 CCU_PADS_2_CRC 0;
BA_ "GenSigInvalidValue" SG_ 620 CCU_PADS_2_CRC 0;
BA_ "GenSigSendType" SG_ 620 CCU_PADS_2_CRC 1;
BA_ "GenSigStartValue" SG_ 620 CCU_PADS_2_CRC 0;
BA_ "GenSigTimeoutValue" SG_ 620 CCU_PADS_2_CRC 0;
BA_ "Remark" SG_ 620 CCU_PADS_2_CRC "";
BA_ "EventCommandSignal" SG_ 620 CCU_PADS_2_Counter 0;
BA_ "GatewayedSignals" SG_ 620 CCU_PADS_2_Counter 0;
BA_ "GenSigInactiveValue" SG_ 620 CCU_PADS_2_Counter 0;
BA_ "GenSigInvalidValue" SG_ 620 CCU_PADS_2_Counter 0;
BA_ "GenSigSendType" SG_ 620 CCU_PADS_2_Counter 1;
BA_ "GenSigStartValue" SG_ 620 CCU_PADS_2_Counter 0;
BA_ "GenSigTimeoutValue" SG_ 620 CCU_PADS_2_Counter 0;
BA_ "Remark" SG_ 620 CCU_PADS_2_Counter "";
BA_ "EventCommandSignal" SG_ 620 UINM_PADS_ResponseErr 0;
BA_ "GatewayedSignals" SG_ 620 UINM_PADS_ResponseErr 0;
BA_ "GenSigInactiveValue" SG_ 620 UINM_PADS_ResponseErr 0;
BA_ "GenSigInvalidValue" SG_ 620 UINM_PADS_ResponseErr 0;
BA_ "GenSigSendType" SG_ 620 UINM_PADS_ResponseErr 1;
BA_ "GenSigStartValue" SG_ 620 UINM_PADS_ResponseErr 0;
BA_ "GenSigTimeoutValue" SG_ 620 UINM_PADS_ResponseErr 0;
BA_ "Remark" SG_ 620 UINM_PADS_ResponseErr "";
BA_ "EventCommandSignal" SG_ 620 UINM_PADS_CustomSWSt 0;
BA_ "GatewayedSignals" SG_ 620 UINM_PADS_CustomSWSt 0;
BA_ "GenSigInactiveValue" SG_ 620 UINM_PADS_CustomSWSt 0;
BA_ "GenSigInvalidValue" SG_ 620 UINM_PADS_CustomSWSt 0;
BA_ "GenSigSendType" SG_ 620 UINM_PADS_CustomSWSt 1;
BA_ "GenSigStartValue" SG_ 620 UINM_PADS_CustomSWSt 0;
BA_ "GenSigTimeoutValue" SG_ 620 UINM_PADS_CustomSWSt 0;
BA_ "Remark" SG_ 620 UINM_PADS_CustomSWSt "";
BA_ "EventCommandSignal" SG_ 620 UINM_PADS_CustomSWStVD 0;
BA_ "GatewayedSignals" SG_ 620 UINM_PADS_CustomSWStVD 0;
BA_ "GenSigInactiveValue" SG_ 620 UINM_PADS_CustomSWStVD 0;
BA_ "GenSigInvalidValue" SG_ 620 UINM_PADS_CustomSWStVD 0;
BA_ "GenSigSendType" SG_ 620 UINM_PADS_CustomSWStVD 1;
BA_ "GenSigStartValue" SG_ 620 UINM_PADS_CustomSWStVD 0;
BA_ "GenSigTimeoutValue" SG_ 620 UINM_PADS_CustomSWStVD 0;
BA_ "Remark" SG_ 620 UINM_PADS_CustomSWStVD "";
BA_ "EventCommandSignal" SG_ 620 UINM_PADS_CustomSWstuck 0;
BA_ "GatewayedSignals" SG_ 620 UINM_PADS_CustomSWstuck 0;
BA_ "GenSigInactiveValue" SG_ 620 UINM_PADS_CustomSWstuck 0;
BA_ "GenSigInvalidValue" SG_ 620 UINM_PADS_CustomSWstuck 0;
BA_ "GenSigSendType" SG_ 620 UINM_PADS_CustomSWstuck 1;
BA_ "GenSigStartValue" SG_ 620 UINM_PADS_CustomSWstuck 0;
BA_ "GenSigTimeoutValue" SG_ 620 UINM_PADS_CustomSWstuck 0;
BA_ "Remark" SG_ 620 UINM_PADS_CustomSWstuck "";
BA_ "EventCommandSignal" SG_ 620 UINM_PADS_IDC_PlaySWSt 0;
BA_ "GatewayedSignals" SG_ 620 UINM_PADS_IDC_PlaySWSt 0;
BA_ "GenSigInactiveValue" SG_ 620 UINM_PADS_IDC_PlaySWSt 0;
BA_ "GenSigInvalidValue" SG_ 620 UINM_PADS_IDC_PlaySWSt 0;
BA_ "GenSigSendType" SG_ 620 UINM_PADS_IDC_PlaySWSt 1;
BA_ "GenSigStartValue" SG_ 620 UINM_PADS_IDC_PlaySWSt 0;
BA_ "GenSigTimeoutValue" SG_ 620 UINM_PADS_IDC_PlaySWSt 0;
BA_ "Remark" SG_ 620 UINM_PADS_IDC_PlaySWSt "";
BA_ "EventCommandSignal" SG_ 620 UINM_PADS_IDC_PlaySWStVD 0;
BA_ "GatewayedSignals" SG_ 620 UINM_PADS_IDC_PlaySWStVD 0;
BA_ "GenSigInactiveValue" SG_ 620 UINM_PADS_IDC_PlaySWStVD 0;
BA_ "GenSigInvalidValue" SG_ 620 UINM_PADS_IDC_PlaySWStVD 0;
BA_ "GenSigSendType" SG_ 620 UINM_PADS_IDC_PlaySWStVD 1;
BA_ "GenSigStartValue" SG_ 620 UINM_PADS_IDC_PlaySWStVD 0;
BA_ "GenSigTimeoutValue" SG_ 620 UINM_PADS_IDC_PlaySWStVD 0;
BA_ "Remark" SG_ 620 UINM_PADS_IDC_PlaySWStVD "";
BA_ "EventCommandSignal" SG_ 620 UINM_PADS_CruSetSpeedRollerRotatedDir 0;
BA_ "GatewayedSignals" SG_ 620 UINM_PADS_CruSetSpeedRollerRotatedDir 0;
BA_ "GenSigInactiveValue" SG_ 620 UINM_PADS_CruSetSpeedRollerRotatedDir 0;
BA_ "GenSigInvalidValue" SG_ 620 UINM_PADS_CruSetSpeedRollerRotatedDir 0;
BA_ "GenSigSendType" SG_ 620 UINM_PADS_CruSetSpeedRollerRotatedDir 1;
BA_ "GenSigStartValue" SG_ 620 UINM_PADS_CruSetSpeedRollerRotatedDir 0;
BA_ "GenSigTimeoutValue" SG_ 620 UINM_PADS_CruSetSpeedRollerRotatedDir 0;
BA_ "Remark" SG_ 620 UINM_PADS_CruSetSpeedRollerRotatedDir "";
BA_ "EventCommandSignal" SG_ 620 UINM_PADS_FolDistIncSWSt 0;
BA_ "GatewayedSignals" SG_ 620 UINM_PADS_FolDistIncSWSt 0;
BA_ "GenSigInactiveValue" SG_ 620 UINM_PADS_FolDistIncSWSt 0;
BA_ "GenSigInvalidValue" SG_ 620 UINM_PADS_FolDistIncSWSt 0;
BA_ "GenSigSendType" SG_ 620 UINM_PADS_FolDistIncSWSt 1;
BA_ "GenSigStartValue" SG_ 620 UINM_PADS_FolDistIncSWSt 0;
BA_ "GenSigTimeoutValue" SG_ 620 UINM_PADS_FolDistIncSWSt 0;
BA_ "Remark" SG_ 620 UINM_PADS_FolDistIncSWSt "";
BA_ "EventCommandSignal" SG_ 620 UINM_PADS_CruSetSpeedRollerSt 0;
BA_ "GatewayedSignals" SG_ 620 UINM_PADS_CruSetSpeedRollerSt 0;
BA_ "GenSigInactiveValue" SG_ 620 UINM_PADS_CruSetSpeedRollerSt 0;
BA_ "GenSigInvalidValue" SG_ 620 UINM_PADS_CruSetSpeedRollerSt 0;
BA_ "GenSigSendType" SG_ 620 UINM_PADS_CruSetSpeedRollerSt 1;
BA_ "GenSigStartValue" SG_ 620 UINM_PADS_CruSetSpeedRollerSt 0;
BA_ "GenSigTimeoutValue" SG_ 620 UINM_PADS_CruSetSpeedRollerSt 0;
BA_ "Remark" SG_ 620 UINM_PADS_CruSetSpeedRollerSt "";
BA_ "EventCommandSignal" SG_ 620 UINM_PADS_FolDistIncSWStVD 0;
BA_ "GatewayedSignals" SG_ 620 UINM_PADS_FolDistIncSWStVD 0;
BA_ "GenSigInactiveValue" SG_ 620 UINM_PADS_FolDistIncSWStVD 0;
BA_ "GenSigInvalidValue" SG_ 620 UINM_PADS_FolDistIncSWStVD 0;
BA_ "GenSigSendType" SG_ 620 UINM_PADS_FolDistIncSWStVD 1;
BA_ "GenSigStartValue" SG_ 620 UINM_PADS_FolDistIncSWStVD 0;
BA_ "GenSigTimeoutValue" SG_ 620 UINM_PADS_FolDistIncSWStVD 0;
BA_ "Remark" SG_ 620 UINM_PADS_FolDistIncSWStVD "";
BA_ "EventCommandSignal" SG_ 620 UINM_PADS_FolDistIncSWStuckSt 0;
BA_ "GatewayedSignals" SG_ 620 UINM_PADS_FolDistIncSWStuckSt 0;
BA_ "GenSigInactiveValue" SG_ 620 UINM_PADS_FolDistIncSWStuckSt 0;
BA_ "GenSigInvalidValue" SG_ 620 UINM_PADS_FolDistIncSWStuckSt 0;
BA_ "GenSigSendType" SG_ 620 UINM_PADS_FolDistIncSWStuckSt 1;
BA_ "GenSigStartValue" SG_ 620 UINM_PADS_FolDistIncSWStuckSt 0;
BA_ "GenSigTimeoutValue" SG_ 620 UINM_PADS_FolDistIncSWStuckSt 0;
BA_ "Remark" SG_ 620 UINM_PADS_FolDistIncSWStuckSt "";
BA_ "EventCommandSignal" SG_ 620 UINM_PADS_FolDistDecSWStVD 0;
BA_ "GatewayedSignals" SG_ 620 UINM_PADS_FolDistDecSWStVD 0;
BA_ "GenSigInactiveValue" SG_ 620 UINM_PADS_FolDistDecSWStVD 0;
BA_ "GenSigInvalidValue" SG_ 620 UINM_PADS_FolDistDecSWStVD 0;
BA_ "GenSigSendType" SG_ 620 UINM_PADS_FolDistDecSWStVD 1;
BA_ "GenSigStartValue" SG_ 620 UINM_PADS_FolDistDecSWStVD 0;
BA_ "GenSigTimeoutValue" SG_ 620 UINM_PADS_FolDistDecSWStVD 0;
BA_ "Remark" SG_ 620 UINM_PADS_FolDistDecSWStVD "";
BA_ "EventCommandSignal" SG_ 620 UINM_PADS_FolDistDecSWStuckSt 0;
BA_ "GatewayedSignals" SG_ 620 UINM_PADS_FolDistDecSWStuckSt 0;
BA_ "GenSigInactiveValue" SG_ 620 UINM_PADS_FolDistDecSWStuckSt 0;
BA_ "GenSigInvalidValue" SG_ 620 UINM_PADS_FolDistDecSWStuckSt 0;
BA_ "GenSigSendType" SG_ 620 UINM_PADS_FolDistDecSWStuckSt 1;
BA_ "GenSigStartValue" SG_ 620 UINM_PADS_FolDistDecSWStuckSt 0;
BA_ "GenSigTimeoutValue" SG_ 620 UINM_PADS_FolDistDecSWStuckSt 0;
BA_ "Remark" SG_ 620 UINM_PADS_FolDistDecSWStuckSt "";
BA_ "EventCommandSignal" SG_ 620 UINM_PADS_OKSWSt 0;
BA_ "GatewayedSignals" SG_ 620 UINM_PADS_OKSWSt 0;
BA_ "GenSigInactiveValue" SG_ 620 UINM_PADS_OKSWSt 0;
BA_ "GenSigInvalidValue" SG_ 620 UINM_PADS_OKSWSt 0;
BA_ "GenSigSendType" SG_ 620 UINM_PADS_OKSWSt 1;
BA_ "GenSigStartValue" SG_ 620 UINM_PADS_OKSWSt 0;
BA_ "GenSigTimeoutValue" SG_ 620 UINM_PADS_OKSWSt 0;
BA_ "Remark" SG_ 620 UINM_PADS_OKSWSt "";
BA_ "EventCommandSignal" SG_ 620 UINM_PADS_OKSWStVD 0;
BA_ "GatewayedSignals" SG_ 620 UINM_PADS_OKSWStVD 0;
BA_ "GenSigInactiveValue" SG_ 620 UINM_PADS_OKSWStVD 0;
BA_ "GenSigInvalidValue" SG_ 620 UINM_PADS_OKSWStVD 0;
BA_ "GenSigSendType" SG_ 620 UINM_PADS_OKSWStVD 1;
BA_ "GenSigStartValue" SG_ 620 UINM_PADS_OKSWStVD 0;
BA_ "GenSigTimeoutValue" SG_ 620 UINM_PADS_OKSWStVD 0;
BA_ "Remark" SG_ 620 UINM_PADS_OKSWStVD "";
BA_ "EventCommandSignal" SG_ 620 UINM_PADS_OKSWStuckSt 0;
BA_ "GatewayedSignals" SG_ 620 UINM_PADS_OKSWStuckSt 0;
BA_ "GenSigInactiveValue" SG_ 620 UINM_PADS_OKSWStuckSt 0;
BA_ "GenSigInvalidValue" SG_ 620 UINM_PADS_OKSWStuckSt 0;
BA_ "GenSigSendType" SG_ 620 UINM_PADS_OKSWStuckSt 1;
BA_ "GenSigStartValue" SG_ 620 UINM_PADS_OKSWStuckSt 0;
BA_ "GenSigTimeoutValue" SG_ 620 UINM_PADS_OKSWStuckSt 0;
BA_ "Remark" SG_ 620 UINM_PADS_OKSWStuckSt "";
BA_ "EventCommandSignal" SG_ 620 UINM_PADS_CruSetSpeedRollerVD 0;
BA_ "GatewayedSignals" SG_ 620 UINM_PADS_CruSetSpeedRollerVD 0;
BA_ "GenSigInactiveValue" SG_ 620 UINM_PADS_CruSetSpeedRollerVD 0;
BA_ "GenSigInvalidValue" SG_ 620 UINM_PADS_CruSetSpeedRollerVD 0;
BA_ "GenSigSendType" SG_ 620 UINM_PADS_CruSetSpeedRollerVD 1;
BA_ "GenSigStartValue" SG_ 620 UINM_PADS_CruSetSpeedRollerVD 0;
BA_ "GenSigTimeoutValue" SG_ 620 UINM_PADS_CruSetSpeedRollerVD 0;
BA_ "Remark" SG_ 620 UINM_PADS_CruSetSpeedRollerVD "";
BA_ "EventCommandSignal" SG_ 620 UINM_PADS_FolDistDecSWSt 0;
BA_ "GatewayedSignals" SG_ 620 UINM_PADS_FolDistDecSWSt 0;
BA_ "GenSigInactiveValue" SG_ 620 UINM_PADS_FolDistDecSWSt 0;
BA_ "GenSigInvalidValue" SG_ 620 UINM_PADS_FolDistDecSWSt 0;
BA_ "GenSigSendType" SG_ 620 UINM_PADS_FolDistDecSWSt 1;
BA_ "GenSigStartValue" SG_ 620 UINM_PADS_FolDistDecSWSt 0;
BA_ "GenSigTimeoutValue" SG_ 620 UINM_PADS_FolDistDecSWSt 0;
BA_ "Remark" SG_ 620 UINM_PADS_FolDistDecSWSt "";
BA_ "EventCommandSignal" SG_ 620 IL_PADS_LightbarErrSt 0;
BA_ "GatewayedSignals" SG_ 620 IL_PADS_LightbarErrSt 0;
BA_ "GenSigInactiveValue" SG_ 620 IL_PADS_LightbarErrSt 0;
BA_ "GenSigInvalidValue" SG_ 620 IL_PADS_LightbarErrSt 0;
BA_ "GenSigSendType" SG_ 620 IL_PADS_LightbarErrSt 1;
BA_ "GenSigStartValue" SG_ 620 IL_PADS_LightbarErrSt 0;
BA_ "GenSigTimeoutValue" SG_ 620 IL_PADS_LightbarErrSt 0;
BA_ "Remark" SG_ 620 IL_PADS_LightbarErrSt "";
BA_ "EventCommandSignal" SG_ 620 UINM_PADS_CruSWSt 0;
BA_ "GatewayedSignals" SG_ 620 UINM_PADS_CruSWSt 0;
BA_ "GenSigInactiveValue" SG_ 620 UINM_PADS_CruSWSt 0;
BA_ "GenSigInvalidValue" SG_ 620 UINM_PADS_CruSWSt 0;
BA_ "GenSigSendType" SG_ 620 UINM_PADS_CruSWSt 1;
BA_ "GenSigStartValue" SG_ 620 UINM_PADS_CruSWSt 0;
BA_ "GenSigTimeoutValue" SG_ 620 UINM_PADS_CruSWSt 0;
BA_ "Remark" SG_ 620 UINM_PADS_CruSWSt "";
BA_ "EventCommandSignal" SG_ 620 UINM_PADS_CruSWStVD 0;
BA_ "GatewayedSignals" SG_ 620 UINM_PADS_CruSWStVD 0;
BA_ "GenSigInactiveValue" SG_ 620 UINM_PADS_CruSWStVD 0;
BA_ "GenSigInvalidValue" SG_ 620 UINM_PADS_CruSWStVD 0;
BA_ "GenSigSendType" SG_ 620 UINM_PADS_CruSWStVD 1;
BA_ "GenSigStartValue" SG_ 620 UINM_PADS_CruSWStVD 0;
BA_ "GenSigTimeoutValue" SG_ 620 UINM_PADS_CruSWStVD 0;
BA_ "Remark" SG_ 620 UINM_PADS_CruSWStVD "";
BA_ "EventCommandSignal" SG_ 620 UINM_PADS_CruSWStuckSt 0;
BA_ "GatewayedSignals" SG_ 620 UINM_PADS_CruSWStuckSt 0;
BA_ "GenSigInactiveValue" SG_ 620 UINM_PADS_CruSWStuckSt 0;
BA_ "GenSigInvalidValue" SG_ 620 UINM_PADS_CruSWStuckSt 0;
BA_ "GenSigSendType" SG_ 620 UINM_PADS_CruSWStuckSt 1;
BA_ "GenSigStartValue" SG_ 620 UINM_PADS_CruSWStuckSt 0;
BA_ "GenSigTimeoutValue" SG_ 620 UINM_PADS_CruSWStuckSt 0;
BA_ "Remark" SG_ 620 UINM_PADS_CruSWStuckSt "";
BA_ "EventCommandSignal" SG_ 620 UINM_PADS_CruSpeedDecSWSt 0;
BA_ "GatewayedSignals" SG_ 620 UINM_PADS_CruSpeedDecSWSt 0;
BA_ "GenSigInactiveValue" SG_ 620 UINM_PADS_CruSpeedDecSWSt 0;
BA_ "GenSigInvalidValue" SG_ 620 UINM_PADS_CruSpeedDecSWSt 0;
BA_ "GenSigSendType" SG_ 620 UINM_PADS_CruSpeedDecSWSt 1;
BA_ "GenSigStartValue" SG_ 620 UINM_PADS_CruSpeedDecSWSt 0;
BA_ "GenSigTimeoutValue" SG_ 620 UINM_PADS_CruSpeedDecSWSt 0;
BA_ "Remark" SG_ 620 UINM_PADS_CruSpeedDecSWSt "";
BA_ "EventCommandSignal" SG_ 620 UINM_PADS_CruSpeedDecSWStVD 0;
BA_ "GatewayedSignals" SG_ 620 UINM_PADS_CruSpeedDecSWStVD 0;
BA_ "GenSigInactiveValue" SG_ 620 UINM_PADS_CruSpeedDecSWStVD 0;
BA_ "GenSigInvalidValue" SG_ 620 UINM_PADS_CruSpeedDecSWStVD 0;
BA_ "GenSigSendType" SG_ 620 UINM_PADS_CruSpeedDecSWStVD 1;
BA_ "GenSigStartValue" SG_ 620 UINM_PADS_CruSpeedDecSWStVD 0;
BA_ "GenSigTimeoutValue" SG_ 620 UINM_PADS_CruSpeedDecSWStVD 0;
BA_ "Remark" SG_ 620 UINM_PADS_CruSpeedDecSWStVD "";
BA_ "EventCommandSignal" SG_ 620 UINM_PADS_CruSpeedDecSWStuckSt 0;
BA_ "GatewayedSignals" SG_ 620 UINM_PADS_CruSpeedDecSWStuckSt 0;
BA_ "GenSigInactiveValue" SG_ 620 UINM_PADS_CruSpeedDecSWStuckSt 0;
BA_ "GenSigInvalidValue" SG_ 620 UINM_PADS_CruSpeedDecSWStuckSt 0;
BA_ "GenSigSendType" SG_ 620 UINM_PADS_CruSpeedDecSWStuckSt 1;
BA_ "GenSigStartValue" SG_ 620 UINM_PADS_CruSpeedDecSWStuckSt 0;
BA_ "GenSigTimeoutValue" SG_ 620 UINM_PADS_CruSpeedDecSWStuckSt 0;
BA_ "Remark" SG_ 620 UINM_PADS_CruSpeedDecSWStuckSt "";
BA_ "EventCommandSignal" SG_ 620 UINM_PADS_CruResumeSpeedIncSWSt 0;
BA_ "GatewayedSignals" SG_ 620 UINM_PADS_CruResumeSpeedIncSWSt 0;
BA_ "GenSigInactiveValue" SG_ 620 UINM_PADS_CruResumeSpeedIncSWSt 0;
BA_ "GenSigInvalidValue" SG_ 620 UINM_PADS_CruResumeSpeedIncSWSt 0;
BA_ "GenSigSendType" SG_ 620 UINM_PADS_CruResumeSpeedIncSWSt 1;
BA_ "GenSigStartValue" SG_ 620 UINM_PADS_CruResumeSpeedIncSWSt 0;
BA_ "GenSigTimeoutValue" SG_ 620 UINM_PADS_CruResumeSpeedIncSWSt 0;
BA_ "Remark" SG_ 620 UINM_PADS_CruResumeSpeedIncSWSt "";
BA_ "EventCommandSignal" SG_ 620 UINM_PADS_CruResumeSpeedIncSWStVD 0;
BA_ "GatewayedSignals" SG_ 620 UINM_PADS_CruResumeSpeedIncSWStVD 0;
BA_ "GenSigInactiveValue" SG_ 620 UINM_PADS_CruResumeSpeedIncSWStVD 0;
BA_ "GenSigInvalidValue" SG_ 620 UINM_PADS_CruResumeSpeedIncSWStVD 0;
BA_ "GenSigSendType" SG_ 620 UINM_PADS_CruResumeSpeedIncSWStVD 1;
BA_ "GenSigStartValue" SG_ 620 UINM_PADS_CruResumeSpeedIncSWStVD 0;
BA_ "GenSigTimeoutValue" SG_ 620 UINM_PADS_CruResumeSpeedIncSWStVD 0;
BA_ "Remark" SG_ 620 UINM_PADS_CruResumeSpeedIncSWStVD "";
BA_ "EventCommandSignal" SG_ 620 UINM_PADS_CruResumeSpeedIncSWStuckSt 0;
BA_ "GatewayedSignals" SG_ 620 UINM_PADS_CruResumeSpeedIncSWStuckSt 0;
BA_ "GenSigInactiveValue" SG_ 620 UINM_PADS_CruResumeSpeedIncSWStuckSt 0;
BA_ "GenSigInvalidValue" SG_ 620 UINM_PADS_CruResumeSpeedIncSWStuckSt 0;
BA_ "GenSigSendType" SG_ 620 UINM_PADS_CruResumeSpeedIncSWStuckSt 1;
BA_ "GenSigStartValue" SG_ 620 UINM_PADS_CruResumeSpeedIncSWStuckSt 0;
BA_ "GenSigTimeoutValue" SG_ 620 UINM_PADS_CruResumeSpeedIncSWStuckSt 0;
BA_ "Remark" SG_ 620 UINM_PADS_CruResumeSpeedIncSWStuckSt "";
BA_ "EventCommandSignal" SG_ 620 UINM_PADS_CruTJAICASWSt 0;
BA_ "GatewayedSignals" SG_ 620 UINM_PADS_CruTJAICASWSt 0;
BA_ "GenSigInactiveValue" SG_ 620 UINM_PADS_CruTJAICASWSt 0;
BA_ "GenSigInvalidValue" SG_ 620 UINM_PADS_CruTJAICASWSt 0;
BA_ "GenSigSendType" SG_ 620 UINM_PADS_CruTJAICASWSt 1;
BA_ "GenSigStartValue" SG_ 620 UINM_PADS_CruTJAICASWSt 0;
BA_ "GenSigTimeoutValue" SG_ 620 UINM_PADS_CruTJAICASWSt 0;
BA_ "Remark" SG_ 620 UINM_PADS_CruTJAICASWSt "";
BA_ "EventCommandSignal" SG_ 620 UINM_PADS_CruTJAICASWStVD 0;
BA_ "GatewayedSignals" SG_ 620 UINM_PADS_CruTJAICASWStVD 0;
BA_ "GenSigInactiveValue" SG_ 620 UINM_PADS_CruTJAICASWStVD 0;
BA_ "GenSigInvalidValue" SG_ 620 UINM_PADS_CruTJAICASWStVD 0;
BA_ "GenSigSendType" SG_ 620 UINM_PADS_CruTJAICASWStVD 1;
BA_ "GenSigStartValue" SG_ 620 UINM_PADS_CruTJAICASWStVD 0;
BA_ "GenSigTimeoutValue" SG_ 620 UINM_PADS_CruTJAICASWStVD 0;
BA_ "Remark" SG_ 620 UINM_PADS_CruTJAICASWStVD "";
BA_ "EventCommandSignal" SG_ 620 UINM_PADS_CruTJAICASWStuckSt 0;
BA_ "GatewayedSignals" SG_ 620 UINM_PADS_CruTJAICASWStuckSt 0;
BA_ "GenSigInactiveValue" SG_ 620 UINM_PADS_CruTJAICASWStuckSt 0;
BA_ "GenSigInvalidValue" SG_ 620 UINM_PADS_CruTJAICASWStuckSt 0;
BA_ "GenSigSendType" SG_ 620 UINM_PADS_CruTJAICASWStuckSt 1;
BA_ "GenSigStartValue" SG_ 620 UINM_PADS_CruTJAICASWStuckSt 0;
BA_ "GenSigTimeoutValue" SG_ 620 UINM_PADS_CruTJAICASWStuckSt 0;
BA_ "Remark" SG_ 620 UINM_PADS_CruTJAICASWStuckSt "";
BA_ "EventCommandSignal" SG_ 620 UINM_PADS_Custom2SWSt 0;
BA_ "GatewayedSignals" SG_ 620 UINM_PADS_Custom2SWSt 0;
BA_ "GenSigInactiveValue" SG_ 620 UINM_PADS_Custom2SWSt 0;
BA_ "GenSigInvalidValue" SG_ 620 UINM_PADS_Custom2SWSt 0;
BA_ "GenSigSendType" SG_ 620 UINM_PADS_Custom2SWSt 1;
BA_ "GenSigStartValue" SG_ 620 UINM_PADS_Custom2SWSt 0;
BA_ "GenSigTimeoutValue" SG_ 620 UINM_PADS_Custom2SWSt 0;
BA_ "Remark" SG_ 620 UINM_PADS_Custom2SWSt "";
BA_ "EventCommandSignal" SG_ 620 UINM_PADS_Custom2SWStVD 0;
BA_ "GatewayedSignals" SG_ 620 UINM_PADS_Custom2SWStVD 0;
BA_ "GenSigInactiveValue" SG_ 620 UINM_PADS_Custom2SWStVD 0;
BA_ "GenSigInvalidValue" SG_ 620 UINM_PADS_Custom2SWStVD 0;
BA_ "GenSigSendType" SG_ 620 UINM_PADS_Custom2SWStVD 1;
BA_ "GenSigStartValue" SG_ 620 UINM_PADS_Custom2SWStVD 0;
BA_ "GenSigTimeoutValue" SG_ 620 UINM_PADS_Custom2SWStVD 0;
BA_ "Remark" SG_ 620 UINM_PADS_Custom2SWStVD "";
BA_ "EventCommandSignal" SG_ 620 UINM_PADS_Custom2SWStuckSt 0;
BA_ "GatewayedSignals" SG_ 620 UINM_PADS_Custom2SWStuckSt 0;
BA_ "GenSigInactiveValue" SG_ 620 UINM_PADS_Custom2SWStuckSt 0;
BA_ "GenSigInvalidValue" SG_ 620 UINM_PADS_Custom2SWStuckSt 0;
BA_ "GenSigSendType" SG_ 620 UINM_PADS_Custom2SWStuckSt 1;
BA_ "GenSigStartValue" SG_ 620 UINM_PADS_Custom2SWStuckSt 0;
BA_ "GenSigTimeoutValue" SG_ 620 UINM_PADS_Custom2SWStuckSt 0;
BA_ "Remark" SG_ 620 UINM_PADS_Custom2SWStuckSt "";
BA_ "EventCommandSignal" SG_ 620 UINM_PADS_ACCSWSt 0;
BA_ "GatewayedSignals" SG_ 620 UINM_PADS_ACCSWSt 0;
BA_ "GenSigInactiveValue" SG_ 620 UINM_PADS_ACCSWSt 0;
BA_ "GenSigInvalidValue" SG_ 620 UINM_PADS_ACCSWSt 0;
BA_ "GenSigSendType" SG_ 620 UINM_PADS_ACCSWSt 1;
BA_ "GenSigStartValue" SG_ 620 UINM_PADS_ACCSWSt 0;
BA_ "GenSigTimeoutValue" SG_ 620 UINM_PADS_ACCSWSt 0;
BA_ "Remark" SG_ 620 UINM_PADS_ACCSWSt "";
BA_ "EventCommandSignal" SG_ 620 UINM_PADS_VoltageFaultSt 0;
BA_ "GatewayedSignals" SG_ 620 UINM_PADS_VoltageFaultSt 0;
BA_ "GenSigInactiveValue" SG_ 620 UINM_PADS_VoltageFaultSt 0;
BA_ "GenSigInvalidValue" SG_ 620 UINM_PADS_VoltageFaultSt 0;
BA_ "GenSigSendType" SG_ 620 UINM_PADS_VoltageFaultSt 1;
BA_ "GenSigStartValue" SG_ 620 UINM_PADS_VoltageFaultSt 0;
BA_ "GenSigTimeoutValue" SG_ 620 UINM_PADS_VoltageFaultSt 0;
BA_ "Remark" SG_ 620 UINM_PADS_VoltageFaultSt "";
BA_ "EventCommandSignal" SG_ 620 UINM_PADS_L3SWSt 0;
BA_ "GatewayedSignals" SG_ 620 UINM_PADS_L3SWSt 0;
BA_ "GenSigInactiveValue" SG_ 620 UINM_PADS_L3SWSt 0;
BA_ "GenSigInvalidValue" SG_ 620 UINM_PADS_L3SWSt 0;
BA_ "GenSigSendType" SG_ 620 UINM_PADS_L3SWSt 1;
BA_ "GenSigStartValue" SG_ 620 UINM_PADS_L3SWSt 0;
BA_ "GenSigTimeoutValue" SG_ 620 UINM_PADS_L3SWSt 0;
BA_ "Remark" SG_ 620 UINM_PADS_L3SWSt "";
BA_ "EventCommandSignal" SG_ 620 UINM_PADS_L3SWStVD 0;
BA_ "GatewayedSignals" SG_ 620 UINM_PADS_L3SWStVD 0;
BA_ "GenSigInactiveValue" SG_ 620 UINM_PADS_L3SWStVD 0;
BA_ "GenSigInvalidValue" SG_ 620 UINM_PADS_L3SWStVD 0;
BA_ "GenSigSendType" SG_ 620 UINM_PADS_L3SWStVD 1;
BA_ "GenSigStartValue" SG_ 620 UINM_PADS_L3SWStVD 0;
BA_ "GenSigTimeoutValue" SG_ 620 UINM_PADS_L3SWStVD 0;
BA_ "Remark" SG_ 620 UINM_PADS_L3SWStVD "";
BA_ "EventCommandSignal" SG_ 620 UINM_PADS_L3SWStuckSt 0;
BA_ "GatewayedSignals" SG_ 620 UINM_PADS_L3SWStuckSt 0;
BA_ "GenSigInactiveValue" SG_ 620 UINM_PADS_L3SWStuckSt 0;
BA_ "GenSigInvalidValue" SG_ 620 UINM_PADS_L3SWStuckSt 0;
BA_ "GenSigSendType" SG_ 620 UINM_PADS_L3SWStuckSt 1;
BA_ "GenSigStartValue" SG_ 620 UINM_PADS_L3SWStuckSt 0;
BA_ "GenSigTimeoutValue" SG_ 620 UINM_PADS_L3SWStuckSt 0;
BA_ "Remark" SG_ 620 UINM_PADS_L3SWStuckSt "";
BA_ "EventCommandSignal" SG_ 620 IL_PADS_LightbarSt 0;
BA_ "GatewayedSignals" SG_ 620 IL_PADS_LightbarSt 0;
BA_ "GenSigInactiveValue" SG_ 620 IL_PADS_LightbarSt 0;
BA_ "GenSigInvalidValue" SG_ 620 IL_PADS_LightbarSt 0;
BA_ "GenSigSendType" SG_ 620 IL_PADS_LightbarSt 1;
BA_ "GenSigStartValue" SG_ 620 IL_PADS_LightbarSt 0;
BA_ "GenSigTimeoutValue" SG_ 620 IL_PADS_LightbarSt 15;
BA_ "Remark" SG_ 620 IL_PADS_LightbarSt "";
VAL_ 696 KAE_EDK1UnlockBtnPressSt 0 "Undifiend" 1 "Short press" 2 "Twice short press" 3 "Long press"  ;
VAL_ 696 KAE_EDK1LockBtnPressSt 0 "Undifiend" 1 "Short press" 2 "Twice short press" 3 "Long press"  ;
VAL_ 696 KAE_EDK1RESBtnPressSt 0 "Undifiend" 1 "Short press" 2 "Twice short press" 3 "Long press"  ;
VAL_ 696 KAE_EDK1PSD_LBtnPressSt 0 "Undifiend" 1 "Short press" 2 "Twice short press" 3 "Long press"  ;
VAL_ 696 KAE_EDK1PSD_RBtnPressSt 0 "Undifiend" 1 "Short press" 2 "Twice short press" 3 "Long press"  ;
VAL_ 696 KAE_EDK1TrunkBtnPressSt 0 "Undifiend" 1 "Short press" 2 "Twice short press" 3 "Long press"  ;
VAL_ 696 KAE_EDK1PanicBtnPressSt 0 "Undifiend" 1 "Short press" 2 "Twice short press" 3 "Long press"  ;
VAL_ 696 KAE_EDK1User_definedBtnPressSt 0 "Undifiend" 1 "Short press" 2 "Twice short press" 3 "Long press"  ;
VAL_ 696 KAE_EDK2UnlockBtnPressSt 0 "Undifiend" 1 "Short press" 2 "Twice short press" 3 "Long press"  ;
VAL_ 696 KAE_EDK2LockBtnPressSt 0 "Undifiend" 1 "Short press" 2 "Twice short press" 3 "Long press"  ;
VAL_ 696 KAE_EDK2RESBtnPressSt 0 "Undifiend" 1 "Short press" 2 "Twice short press" 3 "Long press"  ;
VAL_ 696 KAE_EDK2PSD_LBtnPressSt 0 "Undifiend" 1 "Short press" 2 "Twice short press" 3 "Long press"  ;
VAL_ 696 KAE_EDK2PSD_RBtnPressSt 0 "Undifiend" 1 "Short press" 2 "Twice short press" 3 "Long press"  ;
VAL_ 696 KAE_EDK2TrunkBtnPressSt 0 "Undifiend" 1 "Short press" 2 "Twice short press" 3 "Long press"  ;
VAL_ 696 KAE_EDK2PanicBtnPressSt 0 "Undifiend" 1 "Short press" 2 "Twice short press" 3 "Long press"  ;
VAL_ 696 KAE_EDK2User_definedBtnPressSt 0 "Undifiend" 1 "Short press" 2 "Twice short press" 3 "Long press"  ;
VAL_ 696 KAE_EDK3UnlockBtnPressSt 0 "Undifiend" 1 "Short press" 2 "Twice short press" 3 "Long press"  ;
VAL_ 696 KAE_EDK3LockBtnPressSt 0 "Undifiend" 1 "Short press" 2 "Twice short press" 3 "Long press"  ;
VAL_ 696 KAE_EDK3RESBtnPressSt 0 "Undifiend" 1 "Short press" 2 "Twice short press" 3 "Long press"  ;
VAL_ 696 KAE_EDK3PSD_LBtnPressSt 0 "Undifiend" 1 "Short press" 2 "Twice short press" 3 "Long press"  ;
VAL_ 696 KAE_EDK3PSD_RBtnPressSt 0 "Undifiend" 1 "Short press" 2 "Twice short press" 3 "Long press"  ;
VAL_ 696 KAE_EDK3TrunkBtnPressSt 0 "Undifiend" 1 "Short press" 2 "Twice short press" 3 "Long press"  ;
VAL_ 696 KAE_EDK3PanicBtnPressSt 0 "Undifiend" 1 "Short press" 2 "Twice short press" 3 "Long press"  ;
VAL_ 696 KAE_EDK3User_definedBtnPressSt 0 "Undifiend" 1 "Short press" 2 "Twice short press" 3 "Long press"  ;
VAL_ 696 KAE_RPADirectionSel 0 "No_ParkSlot" 1 "Cross Left Out" 2 "Parallel Left Out" 3 "Front Out" 4 "Cross Right Out" 5 "Parallel Right Out" 6 "Rear Out" 7 "Reserved"  ;
VAL_ 696 KAE_RPAmode 0 "RPA mode" 1 "AVP mode" 2 "Resered" 3 "Resered"  ;
VAL_ 696 KAE_RPADeviceSt 0 "RD_Inactive" 1 "RD_Ready" 2 "RD_Active" 3 "Reserved" 4 "Reserved" 5 "Reserved" 6 "Reserved" 7 "Reserved"  ;
VAL_ 696 KAE_RPACheckReq 0 "Not active" 1 "Requst"  ;
VAL_ 696 KAE_RPAKeyPstSt 0 "In the Car" 1 "Range Too Close" 2 "Normally Range" 3 "Range Too Far"  ;
VAL_ 696 KAE_RPADeviceFailReason 0 "RD_NoFailure" 1 "RD_Offline" 2 "RD_OutOfRange" 3 "RD_LowBatt" 4 "Other Failures" 5 "RD_UserExitParkingMode" 6 "CameraFail" 7 "Charg plug locked" 8 "Remote start fail" 9 "Reserved" 10 "Reserved" 11 "Reserved" 12 "Reserved" 13 "Reserved" 14 "Reserved" 15 "Reserved"  ;
VAL_ 696 KAE_RPABtnSt 0 "Not Pressed" 1 "Pressed"  ;
VAL_ 696 KAE_ForRPAFailReason 0 "SBM_NoFailure" 1 "SBM&RD_Offline" 2 "Not used" 3 "SBM&RPA_Offline" 4 "Other Failures" 5 "Reserved" 6 "Reserved" 7 "Reserved" 8 "Reserved" 9 "Reserved" 10 "Reserved" 11 "Reserved" 12 "Reserved" 13 "Reserved" 14 "Reserved" 15 "Reserved"  ;
VAL_ 696 KAE_RPABtnStVD 0 "Invalid" 1 "Valid"  ;
VAL_ 696 KAE_RPACancelBtnSt 0 "Not Pressed" 1 "Pressed"  ;
VAL_ 696 KAE_RPACancelBtnStVD 0 "Invalid" 1 "Valid"  ;
VAL_ 696 KAE_HAVPCancelParking 0 "No comment" 1 "Cancel"  ;
VAL_ 696 KAE_HAVPDisclaimerAgree 0 "No comment" 1 "Agree" 2 "Disagree" 3 "Reserved"  ;
VAL_ 696 KAE_HAVPUWBZone 0 "Not used" 1 "FL zone" 2 "Ahead zone" 3 "FR zone" 4 "Ahead right side zone" 5 "Back right side zone" 6 "RR zone" 7 "back zone" 8 "RL zone" 9 "Back left side zone" 10 "Ahead left side zone"  ;
VAL_ 696 KAE_UnlockDoorReq 0 "No request" 1 "Unlock"  ;
VAL_ 696 KAE_UnlockDoorReqVD 0 "Invalid" 1 "Valid"  ;
VAL_ 696 KAE_LockDoorReq 0 "No request" 1 "Lock"  ;
VAL_ 696 KAE_LockDoorReqVD 0 "Invalid" 1 "Valid"  ;
VAL_ 696 KAE_WindowsCloseReq 0 "No request" 1 "Close the windows"  ;
VAL_ 696 KAE_WindowsCloseReqVD 0 "Invalid" 1 "Valid"  ;
VAL_ 696 KAE_WindowsOpenReq 0 "No request" 1 "Open the windows"  ;
VAL_ 696 KAE_WindowsOpenReqVD 0 "Invalid" 1 "Valid"  ;
VAL_ 696 KAE_TrunkUnlockReq 0 "No request" 1 "Trunk unlock"  ;
VAL_ 696 KAE_TrunkUnlockReqVD 0 "Invalid" 1 "Valid"  ;
VAL_ 696 KAE_HoodUnlockReq 0 "No request" 1 "Hood unlock"  ;
VAL_ 696 KAE_HoodUnlockReqVD 0 "Invalid" 1 "Valid"  ;
VAL_ 696 KAE_PLGMOpenReq 0 "No request" 1 "PLGM open"  ;
VAL_ 696 KAE_PLGMOpenReqVD 0 "Invalid" 1 "valid"  ;
VAL_ 696 KAE_PLGMCloseReq 0 "No request" 1 "PLGM close"  ;
VAL_ 696 KAE_PLGMCloseReqVD 0 "Invalid" 1 "valid"  ;
VAL_ 696 KAE_SunRoofOpenReq 0 "No request" 1 "Sun roof open"  ;
VAL_ 696 KAE_SunRoofOpenReqVD 0 "Invalid" 1 "Valid"  ;
VAL_ 696 KAE_SunRoofCloseReq 0 "No request" 1 "Sun roof close"  ;
VAL_ 696 KAE_SunRoofCloseReqVD 0 "Invalid" 1 "Valid"  ;
VAL_ 696 KAE_PAAReq 0 "No request" 1 "RPA request" 2 "HPA request" 3 "EDK request"  ;
VAL_ 696 KAE_PAAReqVd 0 "Invalid" 1 "Valid"  ;
VAL_ 696 KAE_EDK1UnlockBtnSt 0 "Not active" 1 "Active"  ;
VAL_ 696 KAE_EDK1LockBtnSt 0 "Not active" 1 "Active"  ;
VAL_ 696 KAE_EDK1RESBtnSt 0 "Not active" 1 "Active"  ;
VAL_ 696 KAE_EDK1PSD_LBtnSt 0 "Not active" 1 "Active"  ;
VAL_ 696 KAE_EDK1PSD_RBtnSt 0 "Not active" 1 "Active"  ;
VAL_ 696 KAE_EDK1TrunkBtnSt 0 "Not active" 1 "Active"  ;
VAL_ 696 KAE_EDK1PanicBtnSt 0 "Not active" 1 "Active"  ;
VAL_ 696 KAE_EDK1User_definedBtnSt 0 "Not active" 1 "Active"  ;
VAL_ 696 KAE_EDK2UnlockBtnSt 0 "Not active" 1 "Active"  ;
VAL_ 696 KAE_EDK2LockBtnSt 0 "Not active" 1 "Active"  ;
VAL_ 696 KAE_EDK2RESBtnSt 0 "Not active" 1 "Active"  ;
VAL_ 696 PKC_RemPwrOnOffReq 0 "None" 1 "Power on & Enter Ready" 2 "Power off & Lock car" 3 "Enter the ready state" 4 "Exit ready state (maintain high voltage)" 5 "Power off only" 6 "Reserved" 7 "Reserved"  ;
VAL_ 696 KAE_EDK2PSD_LBtnSt 0 "Not active" 1 "Active"  ;
VAL_ 696 KAE_EDK2PSD_RBtnSt 0 "Not active" 1 "Active"  ;
VAL_ 696 KAE_EDK2TrunkBtnSt 0 "Not active" 1 "Active"  ;
VAL_ 696 KAE_EDK2PanicBtnSt 0 "Not active" 1 "Active"  ;
VAL_ 696 KAE_EDK2User_definedBtnSt 0 "Not active" 1 "Active"  ;
VAL_ 696 KAE_EDK3UnlockBtnSt 0 "Not active" 1 "Active"  ;
VAL_ 696 KAE_EDK3LockBtnSt 0 "Not active" 1 "Active"  ;
VAL_ 696 KAE_EDK3RESBtnSt 0 "Not active" 1 "Active"  ;
VAL_ 696 KAE_EDK3PSD_LBtnSt 0 "Not active" 1 "Active"  ;
VAL_ 696 KAE_EDK3PSD_RBtnSt 0 "Not active" 1 "Active"  ;
VAL_ 696 KAE_EDK3TrunkBtnSt 0 "Not active" 1 "Active"  ;
VAL_ 696 KAE_EDK3PanicBtnSt 0 "Not active" 1 "Active"  ;
VAL_ 696 KAE_EDK3User_definedBtnSt 0 "Not active" 1 "Active"  ;
VAL_ 696 PKC_PhoneRPAOnlineOrNot 0 "None" 1 "rolling counter" 2 "rolling counter" 3 "rolling counter" 4 "rolling counter" 5 "rolling counter" 6 "rolling counter" 7 "rolling counter" 8 "rolling counter" 9 "rolling counter" 10 "rolling counter" 11 "rolling counter" 12 "rolling counter" 13 "rolling counter" 14 "rolling counter" 15 "rolling counter" 16 "rolling counter" 17 "rolling counter" 18 "rolling counter" 19 "rolling counter" 20 "rolling counter" 21 "rolling counter" 22 "rolling counter" 23 "rolling counter" 24 "rolling counter" 25 "rolling counter" 26 "rolling counter" 27 "rolling counter" 28 "rolling counter" 29 "rolling counter" 30 "rolling counter" 31 "rolling counter" 32 "rolling counter" 33 "rolling counter" 34 "rolling counter" 35 "rolling counter" 36 "rolling counter" 37 "rolling counter" 38 "rolling counter" 39 "rolling counter" 40 "rolling counter" 41 "rolling counter" 42 "rolling counter" 43 "rolling counter" 44 "rolling counter" 45 "rolling counter" 46 "rolling counter" 47 "rolling counter" 48 "rolling counter" 49 "rolling counter" 50 "rolling counter" 51 "rolling counter" 52 "rolling counter" 53 "rolling counter" 54 "rolling counter" 55 "rolling counter" 56 "rolling counter" 57 "rolling counter" 58 "rolling counter" 59 "rolling counter" 60 "rolling counter" 61 "rolling counter" 62 "rolling counter" 63 "rolling counter" 64 "rolling counter" 65 "rolling counter" 66 "rolling counter" 67 "rolling counter" 68 "rolling counter" 69 "rolling counter" 70 "rolling counter" 71 "rolling counter" 72 "rolling counter" 73 "rolling counter" 74 "rolling counter" 75 "rolling counter" 76 "rolling counter" 77 "rolling counter" 78 "rolling counter" 79 "rolling counter" 80 "rolling counter" 81 "rolling counter" 82 "rolling counter" 83 "rolling counter" 84 "rolling counter" 85 "rolling counter" 86 "rolling counter" 87 "rolling counter" 88 "rolling counter" 89 "rolling counter" 90 "rolling counter" 91 "rolling counter" 92 "rolling counter" 93 "rolling counter" 94 "rolling counter" 95 "rolling counter" 96 "rolling counter" 97 "rolling counter" 98 "rolling counter" 99 "rolling counter" 100 "rolling counter" 101 "rolling counter" 102 "rolling counter" 103 "rolling counter" 104 "rolling counter" 105 "rolling counter" 106 "rolling counter" 107 "rolling counter" 108 "rolling counter" 109 "rolling counter" 110 "rolling counter" 111 "rolling counter" 112 "rolling counter" 113 "rolling counter" 114 "rolling counter" 115 "rolling counter" 116 "rolling counter" 117 "rolling counter" 118 "rolling counter" 119 "rolling counter" 120 "rolling counter" 121 "rolling counter" 122 "rolling counter" 123 "rolling counter" 124 "rolling counter" 125 "rolling counter" 126 "rolling counter" 127 "rolling counter" 128 "rolling counter" 129 "rolling counter" 130 "rolling counter" 131 "rolling counter" 132 "rolling counter" 133 "rolling counter" 134 "rolling counter" 135 "rolling counter" 136 "rolling counter" 137 "rolling counter" 138 "rolling counter" 139 "rolling counter" 140 "rolling counter" 141 "rolling counter" 142 "rolling counter" 143 "rolling counter" 144 "rolling counter" 145 "rolling counter" 146 "rolling counter" 147 "rolling counter" 148 "rolling counter" 149 "rolling counter" 150 "rolling counter" 151 "rolling counter" 152 "rolling counter" 153 "rolling counter" 154 "rolling counter" 155 "rolling counter" 156 "rolling counter" 157 "rolling counter" 158 "rolling counter" 159 "rolling counter" 160 "rolling counter" 161 "rolling counter" 162 "rolling counter" 163 "rolling counter" 164 "rolling counter" 165 "rolling counter" 166 "rolling counter" 167 "rolling counter" 168 "rolling counter" 169 "rolling counter" 170 "rolling counter" 171 "rolling counter" 172 "rolling counter" 173 "rolling counter" 174 "rolling counter" 175 "rolling counter" 176 "rolling counter" 177 "rolling counter" 178 "rolling counter" 179 "rolling counter" 180 "rolling counter" 181 "rolling counter" 182 "rolling counter" 183 "rolling counter" 184 "rolling counter" 185 "rolling counter" 186 "rolling counter" 187 "rolling counter" 188 "rolling counter" 189 "rolling counter" 190 "rolling counter" 191 "rolling counter" 192 "rolling counter" 193 "rolling counter" 194 "rolling counter" 195 "rolling counter" 196 "rolling counter" 197 "rolling counter" 198 "rolling counter" 199 "rolling counter" 200 "rolling counter" 201 "rolling counter" 202 "rolling counter" 203 "rolling counter" 204 "rolling counter" 205 "rolling counter" 206 "rolling counter" 207 "rolling counter" 208 "rolling counter" 209 "rolling counter" 210 "rolling counter" 211 "rolling counter" 212 "rolling counter" 213 "rolling counter" 214 "rolling counter" 215 "rolling counter" 216 "rolling counter" 217 "rolling counter" 218 "rolling counter" 219 "rolling counter" 220 "rolling counter" 221 "rolling counter" 222 "rolling counter" 223 "rolling counter" 224 "rolling counter" 225 "rolling counter" 226 "rolling counter" 227 "rolling counter" 228 "rolling counter" 229 "rolling counter" 230 "rolling counter" 231 "rolling counter" 232 "rolling counter" 233 "rolling counter" 234 "rolling counter" 235 "rolling counter" 236 "rolling counter" 237 "rolling counter" 238 "rolling counter" 239 "rolling counter" 240 "rolling counter" 241 "rolling counter" 242 "rolling counter" 243 "rolling counter" 244 "rolling counter" 245 "rolling counter" 246 "rolling counter" 247 "rolling counter" 248 "rolling counter" 249 "rolling counter" 250 "rolling counter" 251 "rolling counter" 252 "rolling counter" 253 "rolling counter" 254 "rolling counter" 255 "rolling counter"  ;
VAL_ 793 LBMS_SOFVD 0 "Invalid" 1 "Valid"  ;
VAL_ 793 LBMS_SOFEN 0 "Keep to the side parking False,Original lane parking False" 1 "Keep to the side parking True,Original lane parking False" 2 "Keep to the side parking False,Original lane parking True" 3 "Keep to the side parking True,Original lane parking True"  ;
VAL_ 476 FCP_OmniViewBtnSt 0 "Release" 1 "Press"  ;
VAL_ 476 FCP_OmniViewBtnStVD 0 "Not valid" 1 "Valid"  ;
VAL_ 1354 RLR_NMCBV 0 "Node has not woken up the    network(passive wakeup);" 1 "Node has woken up the network(active wakeup)" 0 "NM PDU contains no Partial Network request information" 1 "NM PDU contains Partial Network request information"  ;
VAL_ 1354 RLR_PNCInformation0 0 "No request" 1 "Request" 0 "No request" 1 "Request" 0 "No request" 1 "Request" 0 "No request" 1 "Request" 1 "Request" 0 "No request" 1 "Request" 0 "No request" 1 "Request"  ;
VAL_ 1354 RLR_PNCInformation1 0 "No request" 1 "Request" 0 "No request" 1 "Request"  ;
VAL_ 987 RLR_MRRSt 0 "ON" 1 "Sensor Covered" 2 "System Error" 3 "Temporary Error" 4 "initializing"  ;
VAL_ 987 RLR_ExMirLedWarnL 0 "OFF" 1 "Continue ON（Warning level 1）" 2 "Flashing（Warning level 2）" 3 "Reserved"  ;
VAL_ 987 RLR_LCASt 0 "OFF" 1 "Passive" 2 "Active" 3 "Failure"  ;
VAL_ 987 RLR_LCAWarnLeft 0 "No warning" 1 "Warning level 1" 2 "Warning level 2" 3 "Not used"  ;
VAL_ 987 RLR_ClusterLamp 0 "OFF" 1 "Continue ON(Yellow)" 2 "Continue ON(Green)"  ;
VAL_ 987 RLR_DOWWarnL 0 "OFF" 1 "Warning level 1" 2 "Warning level 2" 3 "Reserved"  ;
VAL_ 987 RLR_DOWSt 0 "OFF" 1 "Passive" 2 "Active" 3 "Failure"  ;
VAL_ 987 RLR_AudioWarnFL 0 "No Warning" 1 "Warning"  ;
VAL_ 987 RLR_AudioWarnRL 0 "No Warning" 1 "Warning"  ;
VAL_ 987 RLR_IALWarnFL 0 "No Warning" 1 "Warning level 1" 2 "Warning level 2" 3 "Reserved"  ;
VAL_ 987 RLR_IALWarnRL 0 "No Warning" 1 "Warning level 1" 2 "Warning level 2" 3 "Reserved"  ;
VAL_ 987 RLR_RCTAWarnLeft 0 "No warning" 1 "Warning level 1" 2 "Warning level 2" 3 "Not used"  ;
VAL_ 987 RLR_RCWSt 0 "Off" 1 "Passive/On/Inactive" 2 "Active" 3 "Failure"  ;
VAL_ 987 RLR_RCWWarn 0 "No warning" 1 "Warning level 1" 2 "Warning level 2" 3 "Not used"  ;
VAL_ 987 RLR_TargetLVD 0 "Target Invalid" 1 "Target Valid" 2 "No Target" 3 "reserved"  ;
VAL_ 987 RLR_RCTASt 0 "OFF" 1 "Passive" 2 "Active" 3 "Failure"  ;
VAL_ 987 RLR_RCTAAssistType 0 "OFF" 1 "fail" 2 "Warning" 3 "brake and Warning"  ;
VAL_ 1343 RRR_NMCBV 0 "Node has not woken up the    network(passive wakeup);" 1 "Node has woken up the network(active wakeup)" 0 "NM PDU contains no Partial Network request information" 1 "NM PDU contains Partial Network request information"  ;
VAL_ 1343 RRR_PNCInformation0 0 "No request" 1 "Request" 0 "No request" 1 "Request" 0 "No request" 1 "Request" 0 "No request" 1 "Request" 1 "Request" 0 "No request" 1 "Request" 0 "No request" 1 "Request"  ;
VAL_ 1343 RRR_PNCInformation1 0 "No request" 1 "Request" 0 "No request" 1 "Request"  ;
VAL_ 932 RRR_MRRSt 0 "ON" 1 "Sensor Covered" 2 "System Error" 3 "Temporary Error" 4 "initializing"  ;
VAL_ 932 RRR_ExMirLedWarnR 0 "OFF" 1 "Continue ON（Warning level 1）" 2 "Flashing（Warning level 2）" 3 "Reserved"  ;
VAL_ 932 RRR_LCASt 0 "OFF" 1 "Passive" 2 "Active" 3 "Failure"  ;
VAL_ 932 RRR_LCAWarnRight 0 "No warning" 1 "Warning level 1" 2 "Warning level 2" 3 "Not used"  ;
VAL_ 932 RRR_ClusterLamp 0 "OFF" 1 "Continue ON(Yellow)" 2 "Continue ON(Green)"  ;
VAL_ 932 RRR_DOWWarnR 0 "OFF" 1 "Warning level 1" 2 "Warning level 2" 3 "Reserved"  ;
VAL_ 932 RRR_DOWSt 0 "OFF" 1 "Passive" 2 "Active" 3 "Failure"  ;
VAL_ 932 RRR_AudioWarnFR 0 "No Warning" 1 "Warning"  ;
VAL_ 932 RRR_AudioWarnRR 0 "No Warning" 1 "Warning"  ;
VAL_ 932 RRR_IALWarnFR 0 "No Warning" 1 "Warning level 1" 2 "Warning level 2" 3 "Reserved"  ;
VAL_ 932 RRR_IALWarnRR 0 "No Warning" 1 "Warning level 1" 2 "Warning level 2" 3 "Reserved"  ;
VAL_ 932 RRR_RCTASt 0 "OFF" 1 "Passive" 2 "Active" 3 "Failure"  ;
VAL_ 932 RRR_RCTAWarnRight 0 "No warning" 1 "Warning level 1" 2 "Warning level 2" 3 "Not used"  ;
VAL_ 932 RRR_RCWSt 0 "Off" 1 "Passive/On/Inactive" 2 "Active" 3 "Failure"  ;
VAL_ 932 RRR_RCWWarn 0 "No warning" 1 "Warning level 1" 2 "Warning level 2" 3 "Not used"  ;
VAL_ 932 RRR_RCTBBrkReq 0 "No request" 1 "Request"  ;
VAL_ 932 RRR_RCTBBrkgVD 0 "Invalid" 1 "Valid"  ;
VAL_ 932 RRR_TargetRVD 0 "Target Invalid" 1 "Target Valid" 2 "No Target" 3 "reserved"  ;
VAL_ 932 RRR_RCTAAssistType 0 "OFF" 1 "fail" 2 "Warning" 3 "brake and Warning"  ;
VAL_ 620 UINM_PADS_ResponseErr 0 "No Error" 1 "Error"  ;
VAL_ 620 UINM_PADS_CustomSWSt 0 "not active;" 1 "active;"  ;
VAL_ 620 UINM_PADS_CustomSWStVD 0 "Not valid" 1 "Valid"  ;
VAL_ 620 UINM_PADS_CustomSWstuck 0 "Normal" 1 "stuck"  ;
VAL_ 620 UINM_PADS_IDC_PlaySWSt 0 "not active;" 1 "active;"  ;
VAL_ 620 UINM_PADS_IDC_PlaySWStVD 0 "Not valid" 1 "Valid"  ;
VAL_ 620 UINM_PADS_CruSetSpeedRollerRotatedDir 0 "Not rotated" 1 "Forward" 2 "Backward" 3 "Not used"  ;
VAL_ 620 UINM_PADS_FolDistIncSWSt 0 "not active;" 1 "active;"  ;
VAL_ 620 UINM_PADS_FolDistIncSWStVD 0 "Not valid" 1 "Valid"  ;
VAL_ 620 UINM_PADS_FolDistIncSWStuckSt 0 "Normal" 1 "stuck"  ;
VAL_ 620 UINM_PADS_FolDistDecSWStVD 0 "Not valid" 1 "Valid"  ;
VAL_ 620 UINM_PADS_FolDistDecSWStuckSt 0 "Normal" 1 "stuck"  ;
VAL_ 620 UINM_PADS_OKSWSt 0 "not active;" 1 "active;"  ;
VAL_ 620 UINM_PADS_OKSWStVD 0 "Not valid" 1 "Valid"  ;
VAL_ 620 UINM_PADS_OKSWStuckSt 0 "Normal" 1 "stuck"  ;
VAL_ 620 UINM_PADS_CruSetSpeedRollerVD 0 "Not valid" 1 "Valid"  ;
VAL_ 620 UINM_PADS_FolDistDecSWSt 0 "not active;" 1 "active;"  ;
VAL_ 620 IL_PADS_LightbarErrSt 0 "No Error" 1 "Error"  ;
VAL_ 620 UINM_PADS_CruSWSt 0 "not active;" 1 "active;"  ;
VAL_ 620 UINM_PADS_CruSWStVD 0 "Not valid" 1 "Valid"  ;
VAL_ 620 UINM_PADS_CruSWStuckSt 0 "Normal" 1 "stuck"  ;
VAL_ 620 UINM_PADS_CruSpeedDecSWSt 0 "not active;" 1 "active;"  ;
VAL_ 620 UINM_PADS_CruSpeedDecSWStVD 0 "Not valid" 1 "Valid"  ;
VAL_ 620 UINM_PADS_CruSpeedDecSWStuckSt 0 "Normal" 1 "stuck"  ;
VAL_ 620 UINM_PADS_CruResumeSpeedIncSWSt 0 "not active;" 1 "active;"  ;
VAL_ 620 UINM_PADS_CruResumeSpeedIncSWStVD 0 "Not valid" 1 "Valid"  ;
VAL_ 620 UINM_PADS_CruResumeSpeedIncSWStuckSt 0 "Normal" 1 "stuck"  ;
VAL_ 620 UINM_PADS_CruTJAICASWSt 0 "not active;" 1 "active;"  ;
VAL_ 620 UINM_PADS_CruTJAICASWStVD 0 "Not valid" 1 "Valid"  ;
VAL_ 620 UINM_PADS_CruTJAICASWStuckSt 0 "Normal" 1 "stuck"  ;
VAL_ 620 UINM_PADS_Custom2SWSt 0 "not active" 1 "active"  ;
VAL_ 620 UINM_PADS_Custom2SWStVD 0 "Not valid" 1 "Valid"  ;
VAL_ 620 UINM_PADS_Custom2SWStuckSt 0 "Normal" 1 "stuck"  ;
VAL_ 620 UINM_PADS_ACCSWSt 0 "not perssed" 1 "short pressed" 2 "long pressed" 3 "reserved"  ;
VAL_ 620 UINM_PADS_VoltageFaultSt 0 "No error" 1 "Low voltage" 2 "High voltage" 3 "Not used"  ;
VAL_ 620 UINM_PADS_L3SWSt 0 "Not Perssed" 1 "Short Pressed" 2 "Long Pressed" 3 "Reserved"  ;
VAL_ 620 UINM_PADS_L3SWStVD 0 "Not Valid" 1 "Valid"  ;
VAL_ 620 UINM_PADS_L3SWStuckSt 0 "Normal" 1 "Stuck"  ;
VAL_ 620 IL_PADS_LightbarSt 0 "Off;" 1 "White;" 2 "Blue;" 3 "Orange;" 4 "Red;" 5 "Reserved;" 6 "Reserved;" 7 "Reserved;" 8 "Reserved;" 9 "Reserved;" 10 "Reserved;" 11 "Reserved;" 12 "Reserved;" 13 "Reserved;" 14 "Reserved;" 15 "Invalid:"  ;
